VERSION "dbc-export 1 2026.26.6.5"

NS_ :

BS_:

BU_: ADSP APSB BB CMP DAS DPB EPAS3P EPASTP EPASTS GTW IDB OCS1P PTC RCM RCU TCU TCU2 UDS UI UIS VCLEFT VCSEAT2L VCSEAT2R

BO_ 1384 GTW_alertLog: 8 GTW
 SG_ GTW_alertID M : 0|9@1+ (1,0) [0|511] "" Vector__XXX
 SG_ GTW_alertState : 15|1@1+ (1,0) [0|1] "" Vector__XXX
 SG_ GTW_a014_crcVersion m14 : 16|32@1+ (1,0) [0|4294967295] "" Vector__XXX
 SG_ GTW_a015_crcVersion m15 : 16|32@1+ (1,0) [0|4294967295] "" Vector__XXX
 SG_ GTW_a016_crcVersion m16 : 16|32@1+ (1,0) [0|4294967295] "" Vector__XXX
 SG_ GTW_a017_crcVersion m17 : 16|32@1+ (1,0) [0|4294967295] "" Vector__XXX
 SG_ GTW_a018_crcVersion m18 : 16|32@1+ (1,0) [0|4294967295] "" Vector__XXX
 SG_ GTW_a019_crcVersion m19 : 16|32@1+ (1,0) [0|4294967295] "" Vector__XXX
 SG_ GTW_a020_crcVersion m20 : 16|32@1+ (1,0) [0|4294967295] "" Vector__XXX
 SG_ GTW_a021_crcVersion m21 : 16|32@1+ (1,0) [0|4294967295] "" Vector__XXX
 SG_ GTW_a022_crcVersion m22 : 16|32@1+ (1,0) [0|4294967295] "" Vector__XXX
 SG_ GTW_a023_crcVersion m23 : 16|32@1+ (1,0) [0|4294967295] "" Vector__XXX
 SG_ GTW_a024_crcVersion m24 : 16|32@1+ (1,0) [0|4294967295] "" Vector__XXX
 SG_ GTW_a025_crcVersion m25 : 16|32@1+ (1,0) [0|4294967295] "" Vector__XXX
 SG_ GTW_a026_crcVersion m26 : 16|32@1+ (1,0) [0|4294967295] "" Vector__XXX
 SG_ GTW_a027_crcVersion m27 : 16|32@1+ (1,0) [0|4294967295] "" Vector__XXX
 SG_ GTW_a028_crcVersion m28 : 16|32@1+ (1,0) [0|4294967295] "" Vector__XXX
 SG_ GTW_a029_crcVersion m29 : 16|32@1+ (1,0) [0|4294967295] "" Vector__XXX
 SG_ GTW_a030_crcVersion m30 : 16|32@1+ (1,0) [0|4294967295] "" Vector__XXX
 SG_ GTW_a031_crcVersion m31 : 16|32@1+ (1,0) [0|4294967295] "" Vector__XXX
 SG_ GTW_a032_crcVersion m32 : 16|32@1+ (1,0) [0|4294967295] "" Vector__XXX
 SG_ GTW_a033_crcVersion m33 : 16|32@1+ (1,0) [0|4294967295] "" Vector__XXX
 SG_ GTW_a034_crcVersion m34 : 16|32@1+ (1,0) [0|4294967295] "" Vector__XXX
 SG_ GTW_a035_crcVersion m35 : 16|32@1+ (1,0) [0|4294967295] "" Vector__XXX
 SG_ GTW_a036_crcVersion m36 : 16|32@1+ (1,0) [0|4294967295] "" Vector__XXX
 SG_ GTW_a037_crcVersion m37 : 16|32@1+ (1,0) [0|4294967295] "" Vector__XXX
 SG_ GTW_a038_crcVersion m38 : 16|32@1+ (1,0) [0|4294967295] "" Vector__XXX
 SG_ GTW_a039_crcVersion m39 : 16|32@1+ (1,0) [0|4294967295] "" Vector__XXX
 SG_ GTW_a040_crcVersion m40 : 16|32@1+ (1,0) [0|4294967295] "" Vector__XXX
 SG_ GTW_a041_crcVersion m41 : 16|32@1+ (1,0) [0|4294967295] "" Vector__XXX
 SG_ GTW_a042_crcVersion m42 : 16|32@1+ (1,0) [0|4294967295] "" Vector__XXX
 SG_ GTW_a043_crcVersion m43 : 16|32@1+ (1,0) [0|4294967295] "" Vector__XXX
 SG_ GTW_a045_crcVersion m45 : 16|32@1+ (1,0) [0|4294967295] "" Vector__XXX
 SG_ GTW_a046_crcVersion m46 : 16|32@1+ (1,0) [0|4294967295] "" Vector__XXX
 SG_ GTW_a047_crcVersion m47 : 16|32@1+ (1,0) [0|4294967295] "" Vector__XXX
 SG_ GTW_a048_crcVersion m48 : 16|32@1+ (1,0) [0|4294967295] "" Vector__XXX
 SG_ GTW_a049_headerError m49 : 16|2@1+ (1,0) [0|3] "" Vector__XXX
 SG_ GTW_a054_crcVersion m54 : 16|32@1+ (1,0) [0|4294967295] "" Vector__XXX
 SG_ GTW_a055_crcVersion m55 : 16|32@1+ (1,0) [0|4294967295] "" Vector__XXX
 SG_ GTW_a062_bmpWatchdogReason m62 : 16|3@1+ (1,0) [0|7] "" Vector__XXX
 SG_ GTW_a063_VEH_faultConfinement m63 : 16|2@1+ (1,0) [0|3] "" Vector__XXX
 SG_ GTW_a064_CH_faultConfinement m64 : 16|2@1+ (1,0) [0|3] "" Vector__XXX
 SG_ GTW_a065_PARTY_faultConfinement m65 : 16|2@1+ (1,0) [0|3] "" Vector__XXX
 SG_ GTW_a066_type m66 : 16|5@1+ (1,0) [0|31] "" Vector__XXX
 SG_ GTW_a066_exceptionCfgId m66 : 21|8@1+ (1,0) [0|255] "" Vector__XXX
 SG_ GTW_a066_uptime m66 : 29|32@1+ (1,0) [0|4294967295] "" Vector__XXX
 SG_ GTW_a066_core m66 : 61|3@1+ (1,0) [0|7] "" Vector__XXX
 SG_ GTW_a068_codeKeyMissing m68 : 16|1@1+ (1,0) [0|1] "" Vector__XXX
 SG_ GTW_a068_cmdKeyMissing m68 : 17|1@1+ (1,0) [0|1] "" Vector__XXX
 SG_ GTW_a069_sdIntStatusErrs m69 : 16|1@1+ (1,0) [0|1] "" Vector__XXX
 SG_ GTW_a069_sdTimeout m69 : 17|1@1+ (1,0) [0|1] "" Vector__XXX
 SG_ GTW_a069_sdCmdErr m69 : 18|1@1+ (1,0) [0|1] "" Vector__XXX
 SG_ GTW_a069_sdWriteErr m69 : 19|1@1+ (1,0) [0|1] "" Vector__XXX
 SG_ GTW_a069_sdReadErr m69 : 20|1@1+ (1,0) [0|1] "" Vector__XXX
 SG_ GTW_a069_autoCmd12Err m69 : 21|1@1+ (1,0) [0|1] "" Vector__XXX
 SG_ GTW_a072_updtFailureMask m72 : 16|32@1+ (1,0) [0|4294967295] "" Vector__XXX
 SG_ GTW_a073_SOCResetRequestor m73 : 16|3@1+ (1,0) [0|7] "" Vector__XXX
 SG_ GTW_a077_bmpPmicErrorType m77 : 16|3@1+ (1,0) [0|7] "" Vector__XXX
 SG_ GTW_a097_crcVersion m97 : 16|32@1+ (1,0) [0|4294967295] "" Vector__XXX
 SG_ GTW_a098_crcVersion m98 : 16|32@1+ (1,0) [0|4294967295] "" Vector__XXX
 SG_ GTW_a099_crcVersion m99 : 16|32@1+ (1,0) [0|4294967295] "" Vector__XXX
 SG_ GTW_a100_crcVersion m100 : 16|32@1+ (1,0) [0|4294967295] "" Vector__XXX
 SG_ GTW_a101_switchStuck m101 : 16|1@1+ (1,0) [0|1] "" Vector__XXX
 SG_ GTW_a101_ETH_SW_nINT m101 : 17|1@1+ (1,0) [0|1] "" Vector__XXX
 SG_ GTW_a106_crcVersion m106 : 16|32@1+ (1,0) [0|4294967295] "" Vector__XXX
 SG_ GTW_a107_crcVersion m107 : 16|32@1+ (1,0) [0|4294967295] "" Vector__XXX
 SG_ GTW_a108_crcVersion m108 : 16|32@1+ (1,0) [0|4294967295] "" Vector__XXX
 SG_ GTW_a117_MC_RGM_DES m117 : 16|32@1+ (1,0) [0|4294967295] "" Vector__XXX
 SG_ GTW_a118_MC_RGM_FES m118 : 16|32@1+ (1,0) [0|4294967295] "" Vector__XXX
 SG_ GTW_a122_BDY_faultConfinement m122 : 16|2@1+ (1,0) [0|3] "" Vector__XXX
 SG_ GTW_a129_crcVersion m129 : 16|32@1+ (1,0) [0|4294967295] "" Vector__XXX
 SG_ GTW_a138_sdLifetimeUsed m138 : 16|8@1+ (1,0) [0|255] "" Vector__XXX
 SG_ GTW_a139_crcVersion m139 : 16|32@1+ (1,0) [0|4294967295] "" Vector__XXX
 SG_ GTW_a150_crcVersion m150 : 16|32@1+ (1,0) [0|4294967295] "" Vector__XXX
 SG_ GTW_a151_crcVersion m151 : 16|32@1+ (1,0) [0|4294967295] "" Vector__XXX
 SG_ GTW_a155_crcVersion m155 : 16|32@1+ (1,0) [0|4294967295] "" Vector__XXX
 SG_ GTW_a164_crcVersion m164 : 16|32@1+ (1,0) [0|4294967295] "" Vector__XXX
 SG_ GTW_a165_crcVersion m165 : 16|32@1+ (1,0) [0|4294967295] "" Vector__XXX
 SG_ GTW_a169_TPMS_pressureFL m169 : 16|8@1+ (1,0) [0|255] "" Vector__XXX
 SG_ GTW_a170_TPMS_pressureFR m170 : 16|8@1+ (1,0) [0|255] "" Vector__XXX
 SG_ GTW_a171_TPMS_pressureRL m171 : 16|8@1+ (1,0) [0|255] "" Vector__XXX
 SG_ GTW_a172_TPMS_pressureRR m172 : 16|8@1+ (1,0) [0|255] "" Vector__XXX
 SG_ GTW_a173_TPMS_pressureFL m173 : 16|8@1+ (1,0) [0|255] "" Vector__XXX
 SG_ GTW_a174_TPMS_pressureFR m174 : 16|8@1+ (1,0) [0|255] "" Vector__XXX
 SG_ GTW_a175_TPMS_pressureRL m175 : 16|8@1+ (1,0) [0|255] "" Vector__XXX
 SG_ GTW_a176_TPMS_pressureRR m176 : 16|8@1+ (1,0) [0|255] "" Vector__XXX
 SG_ GTW_a219_crcVersion m219 : 16|32@1+ (1,0) [0|4294967295] "" Vector__XXX
 SG_ GTW_a223_crcVersion m223 : 16|32@1+ (1,0) [0|4294967295] "" Vector__XXX
 SG_ GTW_a226_crcVersion m226 : 16|32@1+ (1,0) [0|4294967295] "" Vector__XXX
 SG_ GTW_a227_crcVersion m227 : 16|32@1+ (1,0) [0|4294967295] "" Vector__XXX
 SG_ GTW_a228_crcVersion m228 : 16|32@1+ (1,0) [0|4294967295] "" Vector__XXX
 SG_ GTW_a244_crcVersion m244 : 16|32@1+ (1,0) [0|4294967295] "" Vector__XXX
 SG_ GTW_a245_page0ControlValue m245 : 16|16@1+ (1,0) [0|65535] "" Vector__XXX
 SG_ GTW_a245_page1ControlValue m245 : 32|16@1+ (1,0) [0|65535] "" Vector__XXX
 SG_ GTW_a261_failureReason m261 : 16|3@1+ (1,0) [0|7] "" Vector__XXX
 SG_ GTW_a261_failureData1 m261 : 24|16@1+ (1,0) [0|65535] "" Vector__XXX
 SG_ GTW_a261_failureData2 m261 : 40|16@1+ (1,0) [0|65535] "" Vector__XXX
 SG_ GTW_a273_crcVersion m273 : 16|32@1+ (1,0) [0|4294967295] "" Vector__XXX
 SG_ GTW_a274_crcVersion m274 : 16|32@1+ (1,0) [0|4294967295] "" Vector__XXX
 SG_ GTW_a277_mitigationFailureReason m277 : 16|3@1+ (1,0) [0|7] "" Vector__XXX
 SG_ GTW_a279_repeatCount m279 : 16|8@1+ (1,0) [0|255] "" Vector__XXX
 SG_ GTW_a279_failureReason m279 : 24|3@1+ (1,0) [0|7] "" Vector__XXX
 SG_ GTW_a279_failureData1 m279 : 32|16@1+ (1,0) [0|65535] "" Vector__XXX
 SG_ GTW_a279_failureData2 m279 : 48|16@1+ (1,0) [0|65535] "" Vector__XXX
 SG_ GTW_a309_crcVersion m309 : 16|32@1+ (1,0) [0|4294967295] "" Vector__XXX
 SG_ GTW_a317_status m317 : 16|3@1+ (1,0) [0|7] "" Vector__XXX
 SG_ GTW_a317_errorCode m317 : 19|5@1+ (1,0) [0|31] "" Vector__XXX
 SG_ GTW_a329_crcVersion m329 : 16|32@1+ (1,0) [0|4294967295] "" Vector__XXX
 SG_ GTW_a330_crcVersion m330 : 16|32@1+ (1,0) [0|4294967295] "" Vector__XXX
 SG_ GTW_a331_crcVersion m331 : 16|32@1+ (1,0) [0|4294967295] "" Vector__XXX
 SG_ GTW_a342_crcVersion m342 : 16|32@1+ (1,0) [0|4294967295] "" Vector__XXX
 SG_ GTW_a348_crcVersion m348 : 16|32@1+ (1,0) [0|4294967295] "" Vector__XXX
 SG_ GTW_a349_crcVersion m349 : 16|32@1+ (1,0) [0|4294967295] "" Vector__XXX
 SG_ GTW_a354_crcVersion m354 : 16|32@1+ (1,0) [0|4294967295] "" Vector__XXX
 SG_ GTW_a355_crcVersion m355 : 16|32@1+ (1,0) [0|4294967295] "" Vector__XXX
 SG_ GTW_a358_crcVersion m358 : 16|32@1+ (1,0) [0|4294967295] "" Vector__XXX
 SG_ GTW_a359_crcVersion m359 : 16|32@1+ (1,0) [0|4294967295] "" Vector__XXX
 SG_ GTW_a360_crcVersion m360 : 16|32@1+ (1,0) [0|4294967295] "" Vector__XXX
 SG_ GTW_a361_crcVersion m361 : 16|32@1+ (1,0) [0|4294967295] "" Vector__XXX
 SG_ GTW_a362_crcVersion m362 : 16|32@1+ (1,0) [0|4294967295] "" Vector__XXX
 SG_ GTW_a363_crcVersion m363 : 16|32@1+ (1,0) [0|4294967295] "" Vector__XXX
 SG_ GTW_a364_crcVersion m364 : 16|32@1+ (1,0) [0|4294967295] "" Vector__XXX
 SG_ GTW_a380_crcVersion m380 : 16|32@1+ (1,0) [0|4294967295] "" Vector__XXX
 SG_ GTW_a381_crcVersion m381 : 16|32@1+ (1,0) [0|4294967295] "" Vector__XXX
 SG_ GTW_a382_crcVersion m382 : 16|32@1+ (1,0) [0|4294967295] "" Vector__XXX
 SG_ GTW_a383_crcVersion m383 : 16|32@1+ (1,0) [0|4294967295] "" Vector__XXX
 SG_ GTW_a384_crcVersion m384 : 16|32@1+ (1,0) [0|4294967295] "" Vector__XXX
 SG_ GTW_a385_crcVersion m385 : 16|32@1+ (1,0) [0|4294967295] "" Vector__XXX
 SG_ GTW_a386_crcVersion m386 : 16|32@1+ (1,0) [0|4294967295] "" Vector__XXX
 SG_ GTW_a394_crcVersion m394 : 16|32@1+ (1,0) [0|4294967295] "" Vector__XXX
 SG_ GTW_a401_crcVersion m401 : 16|32@1+ (1,0) [0|4294967295] "" Vector__XXX
 SG_ GTW_a402_crcVersion m402 : 16|32@1+ (1,0) [0|4294967295] "" Vector__XXX
 SG_ GTW_a409_RES_CAUSE m409 : 16|32@1+ (1,0) [0|4294967295] "" Vector__XXX
 SG_ GTW_a410_RES_CAUSE2 m410 : 16|32@1+ (1,0) [0|4294967295] "" Vector__XXX
 SG_ GTW_a418_crcVersion m418 : 16|32@1+ (1,0) [0|4294967295] "" Vector__XXX
 SG_ GTW_a427_crcVersion m427 : 16|32@1+ (1,0) [0|4294967295] "" Vector__XXX
 SG_ GTW_a428_crcVersion m428 : 16|32@1+ (1,0) [0|4294967295] "" Vector__XXX
 SG_ GTW_a429_crcVersion m429 : 16|32@1+ (1,0) [0|4294967295] "" Vector__XXX
 SG_ GTW_a439_crcVersion m439 : 16|32@1+ (1,0) [0|4294967295] "" Vector__XXX

BO_ 62 GTW_alertMatrix: 8 GTW
 SG_ GTW_matrixIndex M : 0|4@1+ (1,0) [0|15] "" Vector__XXX
 SG_ GTW_w001_canEthTxQueue m0 : 4|1@1+ (1,0) [0|1] "" Vector__XXX
 SG_ GTW_w002_taskError m0 : 5|1@1+ (1,0) [0|1] "" Vector__XXX
 SG_ GTW_w003_logWriteRecord m0 : 6|1@1+ (1,0) [0|1] "" Vector__XXX
 SG_ GTW_w004_mallocHook m0 : 7|1@1+ (1,0) [0|1] "" Vector__XXX
 SG_ GTW_w005_stackOverflowHook m0 : 8|1@1+ (1,0) [0|1] "" Vector__XXX
 SG_ GTW_w006_ifTxOutputFull m0 : 9|1@1+ (1,0) [0|1] "" Vector__XXX
 SG_ GTW_w007_ifRxBufError m0 : 10|1@1+ (1,0) [0|1] "" Vector__XXX
 SG_ GTW_w008_ifPbufAllocError m0 : 11|1@1+ (1,0) [0|1] "" Vector__XXX
 SG_ GTW_w009_lateTask m0 : 12|1@1+ (1,0) [0|1] "" Vector__XXX
 SG_ GTW_w010_wdTaskCount m0 : 13|1@1+ (1,0) [0|1] "" Vector__XXX
 SG_ GTW_w011_cancoreWatchdog m0 : 14|1@1+ (1,0) [0|1] "" Vector__XXX
 SG_ GTW_w012_maincoreWatchdog m0 : 15|1@1+ (1,0) [0|1] "" Vector__XXX
 SG_ GTW_w014_APSversionMismatch m0 : 17|1@1+ (1,0) [0|1] "" Vector__XXX
 SG_ GTW_w015_DIFversionMismatch m0 : 18|1@1+ (1,0) [0|1] "" Vector__XXX
 SG_ GTW_w016_BLEEPCENTERversionMisma m0 : 19|1@1+ (1,0) [0|1] "" Vector__XXX
 SG_ GTW_w017_BMSversionMismatch m0 : 20|1@1+ (1,0) [0|1] "" Vector__XXX
 SG_ GTW_w018_CMPversionMismatch m0 : 21|1@1+ (1,0) [0|1] "" Vector__XXX
 SG_ GTW_w019_CPversionMismatch m0 : 22|1@1+ (1,0) [0|1] "" Vector__XXX
 SG_ GTW_w020_DIRversionMismatch m0 : 23|1@1+ (1,0) [0|1] "" Vector__XXX
 SG_ GTW_w021_EPAS3PversionMismatch m0 : 24|1@1+ (1,0) [0|1] "" Vector__XXX
 SG_ GTW_w022_EPBLversionMismatch m0 : 25|1@1+ (1,0) [0|1] "" Vector__XXX
 SG_ GTW_w023_EPBRversionMismatch m0 : 26|1@1+ (1,0) [0|1] "" Vector__XXX
 SG_ GTW_w024_ESPversionMismatch m0 : 27|1@1+ (1,0) [0|1] "" Vector__XXX
 SG_ GTW_w025_ESPCALversionMismatch m0 : 28|1@1+ (1,0) [0|1] "" Vector__XXX
 SG_ GTW_w026_GTWversionMismatch m0 : 29|1@1+ (1,0) [0|1] "" Vector__XXX
 SG_ GTW_w027_HVPversionMismatch m0 : 30|1@1+ (1,0) [0|1] "" Vector__XXX
 SG_ GTW_w028_IBSTversionMismatch m0 : 31|1@1+ (1,0) [0|1] "" Vector__XXX
 SG_ GTW_w029_IBSTCALversionMismatch m0 : 32|1@1+ (1,0) [0|1] "" Vector__XXX
 SG_ GTW_w030_OCS1PversionMismatch m0 : 33|1@1+ (1,0) [0|1] "" Vector__XXX
 SG_ GTW_w031_PARKversionMismatch m0 : 34|1@1+ (1,0) [0|1] "" Vector__XXX
 SG_ GTW_w032_PCSversionMismatch m0 : 35|1@1+ (1,0) [0|1] "" Vector__XXX
 SG_ GTW_w033_PCSCPU2versionMismatch m0 : 36|1@1+ (1,0) [0|1] "" Vector__XXX
 SG_ GTW_w034_PMRversionMismatch m0 : 37|1@1+ (1,0) [0|1] "" Vector__XXX
 SG_ GTW_w035_PMFversionMismatch m0 : 38|1@1+ (1,0) [0|1] "" Vector__XXX
 SG_ GTW_w036_PTCversionMismatch m0 : 39|1@1+ (1,0) [0|1] "" Vector__XXX
 SG_ GTW_w037_RADCversionMismatch m0 : 40|1@1+ (1,0) [0|1] "" Vector__XXX
 SG_ GTW_w038_RCMversionMismatch m0 : 41|1@1+ (1,0) [0|1] "" Vector__XXX
 SG_ GTW_w039_RCMCALversionMismatch m0 : 42|1@1+ (1,0) [0|1] "" Vector__XXX
 SG_ GTW_w040_SCCMversionMismatch m0 : 43|1@1+ (1,0) [0|1] "" Vector__XXX
 SG_ GTW_w041_VCSECversionMismatch m0 : 44|1@1+ (1,0) [0|1] "" Vector__XXX
 SG_ GTW_w042_TASversionMismatch m0 : 45|1@1+ (1,0) [0|1] "" Vector__XXX
 SG_ GTW_w043_THSversionMismatch m0 : 46|1@1+ (1,0) [0|1] "" Vector__XXX
 SG_ GTW_w045_VCFRONTversionMismatch m0 : 48|1@1+ (1,0) [0|1] "" Vector__XXX
 SG_ GTW_w046_VCLEFTversionMismatch m0 : 49|1@1+ (1,0) [0|1] "" Vector__XXX
 SG_ GTW_w047_VCRIGHTversionMismatch m0 : 50|1@1+ (1,0) [0|1] "" Vector__XXX
 SG_ GTW_w048_EPAS3SversionMismatch m0 : 51|1@1+ (1,0) [0|1] "" Vector__XXX
 SG_ GTW_w049_corruptedManifest m0 : 52|1@1+ (1,0) [0|1] "" Vector__XXX
 SG_ GTW_w050_sdCardInitFailure m0 : 53|1@1+ (1,0) [0|1] "" Vector__XXX
 SG_ GTW_w051_sdCardFileSystemFailure m0 : 54|1@1+ (1,0) [0|1] "" Vector__XXX
 SG_ GTW_w052_ifTxSpans m0 : 55|1@1+ (1,0) [0|1] "" Vector__XXX
 SG_ GTW_w053_busSleepFailure m0 : 56|1@1+ (1,0) [0|1] "" Vector__XXX
 SG_ GTW_w054_OPCRversionMismatch m0 : 57|1@1+ (1,0) [0|1] "" Vector__XXX
 SG_ GTW_w055_OPCFversionMismatch m0 : 58|1@1+ (1,0) [0|1] "" Vector__XXX
 SG_ GTW_w057_i2cFailure m0 : 60|1@1+ (1,0) [0|1] "" Vector__XXX
 SG_ GTW_w058_rtcAlarmFailure m0 : 61|1@1+ (1,0) [0|1] "" Vector__XXX
 SG_ GTW_w059_inFactoryMode m0 : 62|1@1+ (1,0) [0|1] "" Vector__XXX
 SG_ GTW_w060_unFused m0 : 63|1@1+ (1,0) [0|1] "" Vector__XXX
 SG_ GTW_w061_bmpSleepFailure m1 : 4|1@1+ (1,0) [0|1] "" Vector__XXX
 SG_ GTW_w062_bmpWatchdog m1 : 5|1@1+ (1,0) [0|1] "" Vector__XXX
 SG_ GTW_w063_VEH_canFault m1 : 6|1@1+ (1,0) [0|1] "" Vector__XXX
 SG_ GTW_w064_CH_canFault m1 : 7|1@1+ (1,0) [0|1] "" Vector__XXX
 SG_ GTW_w065_PARTY_canFault m1 : 8|1@1+ (1,0) [0|1] "" Vector__XXX
 SG_ GTW_w066_exception m1 : 9|1@1+ (1,0) [0|1] "" Vector__XXX
 SG_ GTW_w067_tcpDebug m1 : 10|1@1+ (1,0) [0|1] "" Vector__XXX
 SG_ GTW_w068_prodKeyMissing m1 : 11|1@1+ (1,0) [0|1] "" Vector__XXX
 SG_ GTW_w069_diskioErr m1 : 12|1@1+ (1,0) [0|1] "" Vector__XXX
 SG_ GTW_w070_hrlDump m1 : 13|1@1+ (1,0) [0|1] "" Vector__XXX
 SG_ GTW_w071_hrlTrigger m1 : 14|1@1+ (1,0) [0|1] "" Vector__XXX
 SG_ GTW_w072_updateFailure m1 : 15|1@1+ (1,0) [0|1] "" Vector__XXX
 SG_ GTW_w073_steeringWheelReset m1 : 16|1@1+ (1,0) [0|1] "" Vector__XXX
 SG_ GTW_w074_epas3pMIA m1 : 17|1@1+ (1,0) [0|1] "" Vector__XXX
 SG_ GTW_w075_epas3sMIA m1 : 18|1@1+ (1,0) [0|1] "" Vector__XXX
 SG_ GTW_w076_ethInterfaceReset m1 : 19|1@1+ (1,0) [0|1] "" Vector__XXX
 SG_ GTW_w077_bmpPmicError m1 : 20|1@1+ (1,0) [0|1] "" Vector__XXX
 SG_ GTW_w078_VEHbusOverloaded m1 : 21|1@1+ (1,0) [0|1] "" Vector__XXX
 SG_ GTW_w079_PARTYbusOverloaded m1 : 22|1@1+ (1,0) [0|1] "" Vector__XXX
 SG_ GTW_w080_CHbusOverloaded m1 : 23|1@1+ (1,0) [0|1] "" Vector__XXX
 SG_ GTW_w081_udsMessageRejected m1 : 24|1@1+ (1,0) [0|1] "" Vector__XXX
 SG_ GTW_w082_sdCardBSCorrupted m1 : 25|1@1+ (1,0) [0|1] "" Vector__XXX
 SG_ GTW_w083_udsMsgDroppedByTcpStack m1 : 26|1@1+ (1,0) [0|1] "" Vector__XXX
 SG_ GTW_w084_canFrameDropped m1 : 27|1@1+ (1,0) [0|1] "" Vector__XXX
 SG_ GTW_w085_fuseStateUnknown m1 : 28|1@1+ (1,0) [0|1] "" Vector__XXX
 SG_ GTW_w086_ocu m1 : 29|1@1+ (1,0) [0|1] "" Vector__XXX
 SG_ GTW_w087_ocuInProgress m1 : 30|1@1+ (1,0) [0|1] "" Vector__XXX
 SG_ GTW_w088_sdCardInvReqParallel m1 : 31|1@1+ (1,0) [0|1] "" Vector__XXX
 SG_ GTW_w089_sdCardWatchdog m1 : 32|1@1+ (1,0) [0|1] "" Vector__XXX
 SG_ GTW_w090_ocuFailed m1 : 33|1@1+ (1,0) [0|1] "" Vector__XXX
 SG_ GTW_w091_lowStack m1 : 34|1@1+ (1,0) [0|1] "" Vector__XXX
 SG_ GTW_w092_sdCardInvReqZero m1 : 35|1@1+ (1,0) [0|1] "" Vector__XXX
 SG_ GTW_w093_sdCardInvReqOverflowBas m1 : 36|1@1+ (1,0) [0|1] "" Vector__XXX
 SG_ GTW_w094_sdCardInvReqOverflowCou m1 : 37|1@1+ (1,0) [0|1] "" Vector__XXX
 SG_ GTW_w095_sdCardFull m1 : 38|1@1+ (1,0) [0|1] "" Vector__XXX
 SG_ GTW_w096_sdCardFatCorrupted m1 : 39|1@1+ (1,0) [0|1] "" Vector__XXX
 SG_ GTW_w097_HCMLversionMismatch m1 : 40|1@1+ (1,0) [0|1] "" Vector__XXX
 SG_ GTW_w098_HCMRversionMismatch m1 : 41|1@1+ (1,0) [0|1] "" Vector__XXX
 SG_ GTW_w099_SWCversionMismatch m1 : 42|1@1+ (1,0) [0|1] "" Vector__XXX
 SG_ GTW_w100_CBCversionMismatch m1 : 43|1@1+ (1,0) [0|1] "" Vector__XXX
 SG_ GTW_w101_switchWatchdog m1 : 44|1@1+ (1,0) [0|1] "" Vector__XXX
 SG_ GTW_w103_sdCardFormatted m1 : 46|1@1+ (1,0) [0|1] "" Vector__XXX
 SG_ GTW_w104_sdCardDriverArgCorrupte m1 : 47|1@1+ (1,0) [0|1] "" Vector__XXX
 SG_ GTW_w105_eBuckConfigured m1 : 48|1@1+ (1,0) [0|1] "" Vector__XXX
 SG_ GTW_w106_BLEEPLEFTversionMismatc m1 : 49|1@1+ (1,0) [0|1] "" Vector__XXX
 SG_ GTW_w107_BLEEPRIGHTversionMismat m1 : 50|1@1+ (1,0) [0|1] "" Vector__XXX
 SG_ GTW_w108_BLEEPREARversionMismatc m1 : 51|1@1+ (1,0) [0|1] "" Vector__XXX
 SG_ GTW_w109_failedToStartUpdater m1 : 52|1@1+ (1,0) [0|1] "" Vector__XXX
 SG_ GTW_w110_readMdioFailed m1 : 53|1@1+ (1,0) [0|1] "" Vector__XXX
 SG_ GTW_w111_writeMdioFailed m1 : 54|1@1+ (1,0) [0|1] "" Vector__XXX
 SG_ GTW_w112_z4bDisabled m1 : 55|1@1+ (1,0) [0|1] "" Vector__XXX
 SG_ GTW_w113_unrecognizedCanMessage m1 : 56|1@1+ (1,0) [0|1] "" Vector__XXX
 SG_ GTW_w114_updtRetried m1 : 57|1@1+ (1,0) [0|1] "" Vector__XXX
 SG_ GTW_w115_hrlEventFileAvail m1 : 58|1@1+ (1,0) [0|1] "" Vector__XXX
 SG_ GTW_w116_switchInitFailed m1 : 59|1@1+ (1,0) [0|1] "" Vector__XXX
 SG_ GTW_w117_unexpectedDestructiveRe m1 : 60|1@1+ (1,0) [0|1] "" Vector__XXX
 SG_ GTW_w118_unexpectedFunctionalRes m1 : 61|1@1+ (1,0) [0|1] "" Vector__XXX
 SG_ GTW_w120_switchUnlocked m1 : 63|1@1+ (1,0) [0|1] "" Vector__XXX
 SG_ GTW_w122_BDY_canFault m2 : 5|1@1+ (1,0) [0|1] "" Vector__XXX
 SG_ GTW_w123_BDYbusOverloaded m2 : 6|1@1+ (1,0) [0|1] "" Vector__XXX
 SG_ GTW_w125_switchReplayUnlocked m2 : 8|1@1+ (1,0) [0|1] "" Vector__XXX
 SG_ GTW_w127_noFilePointersAvailable m2 : 10|1@1+ (1,0) [0|1] "" Vector__XXX
 SG_ GTW_w129_ICRversionMismatch m2 : 12|1@1+ (1,0) [0|1] "" Vector__XXX
 SG_ GTW_w133_adspFaultDetected m2 : 16|1@1+ (1,0) [0|1] "" Vector__XXX
 SG_ GTW_w134_disableFeatureFailed m2 : 17|1@1+ (1,0) [0|1] "" Vector__XXX
 SG_ GTW_w135_canLogQueueFull m2 : 18|1@1+ (1,0) [0|1] "" Vector__XXX
 SG_ GTW_w136_hrlGameModeFileAvail m2 : 19|1@1+ (1,0) [0|1] "" Vector__XXX
 SG_ GTW_w137_lowHeap m2 : 20|1@1+ (1,0) [0|1] "" Vector__XXX
 SG_ GTW_w138_sdCardEndOfLife m2 : 21|1@1+ (1,0) [0|1] "" Vector__XXX
 SG_ GTW_w139_CMPDversionMismatch m2 : 22|1@1+ (1,0) [0|1] "" Vector__XXX
 SG_ GTW_w140_cancoreHeartbeat m2 : 23|1@1+ (1,0) [0|1] "" Vector__XXX
 SG_ GTW_w141_teleCANETHis m2 : 24|1@1+ (1,0) [0|1] "" Vector__XXX
 SG_ GTW_w143_possibleCanWakeIssue m2 : 26|1@1+ (1,0) [0|1] "" Vector__XXX
 SG_ GTW_w144_hrlStateMachine m2 : 27|1@1+ (1,0) [0|1] "" Vector__XXX
 SG_ GTW_w145_carConfigsNotWritten m2 : 28|1@1+ (1,0) [0|1] "" Vector__XXX
 SG_ GTW_w146_performancePackageMisma m2 : 29|1@1+ (1,0) [0|1] "" Vector__XXX
 SG_ GTW_w147_updateAbortFor12v m2 : 30|1@1+ (1,0) [0|1] "" Vector__XXX
 SG_ GTW_w149_rtcTimeSetInPast m2 : 32|1@1+ (1,0) [0|1] "" Vector__XXX
 SG_ GTW_w150_HCM3LversionMismatch m2 : 33|1@1+ (1,0) [0|1] "" Vector__XXX
 SG_ GTW_w151_HCM3RversionMismatch m2 : 34|1@1+ (1,0) [0|1] "" Vector__XXX
 SG_ GTW_w153_externalRtcAlarmFailure m2 : 36|1@1+ (1,0) [0|1] "" Vector__XXX
 SG_ GTW_w155_PMversionMismatch m2 : 38|1@1+ (1,0) [0|1] "" Vector__XXX
 SG_ GTW_w164_VCBATTversionMismatch m2 : 47|1@1+ (1,0) [0|1] "" Vector__XXX
 SG_ GTW_w165_USMversionMismatch m2 : 48|1@1+ (1,0) [0|1] "" Vector__XXX
 SG_ GTW_w166_nErrCanFaultVeh m2 : 49|1@1+ (1,0) [0|1] "" Vector__XXX
 SG_ GTW_w167_nErrCanFaultCh m2 : 50|1@1+ (1,0) [0|1] "" Vector__XXX
 SG_ GTW_w168_nErrCanFaultParty m2 : 51|1@1+ (1,0) [0|1] "" Vector__XXX
 SG_ GTW_w169_TPMSsoftWarnFrontLeft m2 : 52|1@1+ (1,0) [0|1] "" Vector__XXX
 SG_ GTW_w170_TPMSsoftWarnFrontRight m2 : 53|1@1+ (1,0) [0|1] "" Vector__XXX
 SG_ GTW_w171_TPMSsoftWarnRearLeft m2 : 54|1@1+ (1,0) [0|1] "" Vector__XXX
 SG_ GTW_w172_TPMSsoftWarnRearRight m2 : 55|1@1+ (1,0) [0|1] "" Vector__XXX
 SG_ GTW_w173_TPMShardWarnFrontLeft m2 : 56|1@1+ (1,0) [0|1] "" Vector__XXX
 SG_ GTW_w174_TPMShardWarnFrontRight m2 : 57|1@1+ (1,0) [0|1] "" Vector__XXX
 SG_ GTW_w175_TPMShardWarnRearLeft m2 : 58|1@1+ (1,0) [0|1] "" Vector__XXX
 SG_ GTW_w176_TPMShardWarnRearRight m2 : 59|1@1+ (1,0) [0|1] "" Vector__XXX
 SG_ GTW_w186_swrPrecaution m3 : 9|1@1+ (1,0) [0|1] "" Vector__XXX
 SG_ GTW_w218_switchOTPIncorrect m3 : 41|1@1+ (1,0) [0|1] "" Vector__XXX
 SG_ GTW_w219_CMPSversionMismatch m3 : 42|1@1+ (1,0) [0|1] "" Vector__XXX
 SG_ GTW_w223_LVBMSversionMismatch m3 : 46|1@1+ (1,0) [0|1] "" Vector__XXX
 SG_ GTW_w224_sdCardUpgradeNeeded m3 : 47|1@1+ (1,0) [0|1] "" Vector__XXX
 SG_ GTW_w225_resetOnSleepWake m3 : 48|1@1+ (1,0) [0|1] "" Vector__XXX
 SG_ GTW_w226_DISPversionMismatch m3 : 49|1@1+ (1,0) [0|1] "" Vector__XXX
 SG_ GTW_w227_DISPTOUCHversionMismatc m3 : 50|1@1+ (1,0) [0|1] "" Vector__XXX
 SG_ GTW_w228_DISPOSDversionMismatch m3 : 51|1@1+ (1,0) [0|1] "" Vector__XXX
 SG_ GTW_w229_displaySoftsetConnectio m3 : 52|1@1+ (1,0) [0|1] "" Vector__XXX
 SG_ GTW_w230_touchInterruptStorm m3 : 53|1@1+ (1,0) [0|1] "" Vector__XXX
 SG_ GTW_w244_SDCRversionMismatch m4 : 7|1@1+ (1,0) [0|1] "" Vector__XXX
 SG_ GTW_w245_apsNotDisabled m4 : 8|1@1+ (1,0) [0|1] "" Vector__XXX
 SG_ GTW_w246_touchcoreHeartbeat m4 : 9|1@1+ (1,0) [0|1] "" Vector__XXX
 SG_ GTW_w255_rtc32KHzWatchdog m4 : 18|1@1+ (1,0) [0|1] "" Vector__XXX
 SG_ GTW_w260_unknownPN m4 : 23|1@1+ (1,0) [0|1] "" Vector__XXX
 SG_ GTW_w261_adspWatchdog m4 : 24|1@1+ (1,0) [0|1] "" Vector__XXX
 SG_ GTW_w262_canLogBlockDropped m4 : 25|1@1+ (1,0) [0|1] "" Vector__XXX
 SG_ GTW_w263_hrlUdpFileAvail m4 : 26|1@1+ (1,0) [0|1] "" Vector__XXX
 SG_ GTW_w264_hrlPseudoFileAvail m4 : 27|1@1+ (1,0) [0|1] "" Vector__XXX
 SG_ GTW_w265_optionFlagsError m4 : 28|1@1+ (1,0) [0|1] "" Vector__XXX
 SG_ GTW_w266_dpp1MIA m4 : 29|1@1+ (1,0) [0|1] "" Vector__XXX
 SG_ GTW_w267_dpp2MIA m4 : 30|1@1+ (1,0) [0|1] "" Vector__XXX
 SG_ GTW_w268_stoMIA m4 : 31|1@1+ (1,0) [0|1] "" Vector__XXX
 SG_ GTW_w273_BLEEPREARLEFTversionMis m4 : 36|1@1+ (1,0) [0|1] "" Vector__XXX
 SG_ GTW_w274_BLEEPREARRIGHTversionMi m4 : 37|1@1+ (1,0) [0|1] "" Vector__XXX
 SG_ GTW_w275_VDDCORE_DrMOS_Fault m4 : 38|1@1+ (1,0) [0|1] "" Vector__XXX
 SG_ GTW_w276_VDDSOC_DrMOS_Fault m4 : 39|1@1+ (1,0) [0|1] "" Vector__XXX
 SG_ GTW_w277_NonRevCDrMOSMitigationF m4 : 40|1@1+ (1,0) [0|1] "" Vector__XXX
 SG_ GTW_w278_ethSwitchCongested m4 : 41|1@1+ (1,0) [0|1] "" Vector__XXX
 SG_ GTW_w279_adspRepeatedWatchdog m4 : 42|1@1+ (1,0) [0|1] "" Vector__XXX
 SG_ GTW_w280_hrlFrameDropped m4 : 43|1@1+ (1,0) [0|1] "" Vector__XXX
 SG_ GTW_w281_likelyMissedPoke m4 : 44|1@1+ (1,0) [0|1] "" Vector__XXX
 SG_ GTW_w282_tcuPhyConfigurationFail m4 : 45|1@1+ (1,0) [0|1] "" Vector__XXX
 SG_ GTW_w309_VCUSBversionMismatch m5 : 12|1@1+ (1,0) [0|1] "" Vector__XXX
 SG_ GTW_w311_canLogQueueFullBeforeFs m5 : 14|1@1+ (1,0) [0|1] "" Vector__XXX
 SG_ GTW_w312_hrlFileIncomplete m5 : 15|1@1+ (1,0) [0|1] "" Vector__XXX
 SG_ GTW_w313_OSDActive m5 : 16|1@1+ (1,0) [0|1] "" Vector__XXX
 SG_ GTW_w314_canLogBlockWriteErr m5 : 17|1@1+ (1,0) [0|1] "" Vector__XXX
 SG_ GTW_w316_sdCardChkdskRepair m5 : 19|1@1+ (1,0) [0|1] "" Vector__XXX
 SG_ GTW_w317_sdCardChkdskRepairFaile m5 : 20|1@1+ (1,0) [0|1] "" Vector__XXX
 SG_ GTW_w322_gestureUnrecognizedFrom m5 : 25|1@1+ (1,0) [0|1] "" Vector__XXX
 SG_ GTW_w323_gestureStartOutOfStrip m5 : 26|1@1+ (1,0) [0|1] "" Vector__XXX
 SG_ GTW_w328_smartShiftDisabled m5 : 31|1@1+ (1,0) [0|1] "" Vector__XXX
 SG_ GTW_w329_FOHMversionMismatch m5 : 32|1@1+ (1,0) [0|1] "" Vector__XXX
 SG_ GTW_w330_SWSLversionMismatch m5 : 33|1@1+ (1,0) [0|1] "" Vector__XXX
 SG_ GTW_w331_SWSRversionMismatch m5 : 34|1@1+ (1,0) [0|1] "" Vector__XXX
 SG_ GTW_w332_unknownDisplayPN m5 : 35|1@1+ (1,0) [0|1] "" Vector__XXX
 SG_ GTW_w334_hrlFolderSpaceLow m5 : 37|1@1+ (1,0) [0|1] "" Vector__XXX
 SG_ GTW_w336_possibleCanTxIssue m5 : 39|1@1+ (1,0) [0|1] "" Vector__XXX
 SG_ GTW_w342_VCBLDCPPversionMismatch m5 : 45|1@1+ (1,0) [0|1] "" Vector__XXX
 SG_ GTW_w348_VCBLDCFversionMismatch m5 : 51|1@1+ (1,0) [0|1] "" Vector__XXX
 SG_ GTW_w349_VCBLDCPBversionMismatch m5 : 52|1@1+ (1,0) [0|1] "" Vector__XXX
 SG_ GTW_w350_mOSDCrcCheck m5 : 53|1@1+ (1,0) [0|1] "" Vector__XXX
 SG_ GTW_w351_sOSDCrcCheck m5 : 54|1@1+ (1,0) [0|1] "" Vector__XXX
 SG_ GTW_w352_mASILStatusCheck m5 : 55|1@1+ (1,0) [0|1] "" Vector__XXX
 SG_ GTW_w353_sASILStatusCheck m5 : 56|1@1+ (1,0) [0|1] "" Vector__XXX
 SG_ GTW_w354_EPASTPversionMismatch m5 : 57|1@1+ (1,0) [0|1] "" Vector__XXX
 SG_ GTW_w355_EPASTSversionMismatch m5 : 58|1@1+ (1,0) [0|1] "" Vector__XXX
 SG_ GTW_w356_touchGPIOStatusCheck m5 : 59|1@1+ (1,0) [0|1] "" Vector__XXX
 SG_ GTW_w358_RGBIPFLversionMismatch m5 : 61|1@1+ (1,0) [0|1] "" Vector__XXX
 SG_ GTW_w359_RGBIPFRversionMismatch m5 : 62|1@1+ (1,0) [0|1] "" Vector__XXX
 SG_ GTW_w360_RGBDOORFLversionMismatc m5 : 63|1@1+ (1,0) [0|1] "" Vector__XXX
 SG_ GTW_w361_RGBDOORRLversionMismatc m6 : 4|1@1+ (1,0) [0|1] "" Vector__XXX
 SG_ GTW_w362_RGBDOORFRversionMismatc m6 : 5|1@1+ (1,0) [0|1] "" Vector__XXX
 SG_ GTW_w363_RGBDOORRRversionMismatc m6 : 6|1@1+ (1,0) [0|1] "" Vector__XXX
 SG_ GTW_w364_BLEEPCRADLEversionMisma m6 : 7|1@1+ (1,0) [0|1] "" Vector__XXX
 SG_ GTW_w366_uiGearRequestMismatch m6 : 9|1@1+ (1,0) [0|1] "" Vector__XXX
 SG_ GTW_w376_blFailedToExecBootImg m6 : 19|1@1+ (1,0) [0|1] "" Vector__XXX
 SG_ GTW_w380_DPBversionMismatch m6 : 23|1@1+ (1,0) [0|1] "" Vector__XXX
 SG_ GTW_w381_DPBCALversionMismatch m6 : 24|1@1+ (1,0) [0|1] "" Vector__XXX
 SG_ GTW_w382_IDBversionMismatch m6 : 25|1@1+ (1,0) [0|1] "" Vector__XXX
 SG_ GTW_w383_IDB1versionMismatch m6 : 26|1@1+ (1,0) [0|1] "" Vector__XXX
 SG_ GTW_w384_IDBCALversionMismatch m6 : 27|1@1+ (1,0) [0|1] "" Vector__XXX
 SG_ GTW_w385_RCUversionMismatch m6 : 28|1@1+ (1,0) [0|1] "" Vector__XXX
 SG_ GTW_w386_RCUCALversionMismatch m6 : 29|1@1+ (1,0) [0|1] "" Vector__XXX
 SG_ GTW_w387_externalRtcReadFailure m6 : 30|1@1+ (1,0) [0|1] "" Vector__XXX
 SG_ GTW_w388_adspWatchdogSkipped m6 : 31|1@1+ (1,0) [0|1] "" Vector__XXX
 SG_ GTW_w389_rcmEventDetected m6 : 32|1@1+ (1,0) [0|1] "" Vector__XXX
 SG_ GTW_w390_displayFwQueryFailed m6 : 33|1@1+ (1,0) [0|1] "" Vector__XXX
 SG_ GTW_w391_adspMacAddrCheckFailed m6 : 34|1@1+ (1,0) [0|1] "" Vector__XXX
 SG_ GTW_w393_osdSramCrcMismatch m6 : 36|1@1+ (1,0) [0|1] "" Vector__XXX
 SG_ GTW_w394_WIPERversionMismatch m6 : 37|1@1+ (1,0) [0|1] "" Vector__XXX
 SG_ GTW_w395_lwipIcmpError m6 : 38|1@1+ (1,0) [0|1] "" Vector__XXX
 SG_ GTW_w396_alreadyInReverse m6 : 39|1@1+ (1,0) [0|1] "" Vector__XXX
 SG_ GTW_w397_alreadyInDrive m6 : 40|1@1+ (1,0) [0|1] "" Vector__XXX
 SG_ GTW_w398_awakeForExtendedTime m6 : 41|1@1+ (1,0) [0|1] "" Vector__XXX
 SG_ GTW_w399_ethIfRxTcpipQueueDrop m6 : 42|1@1+ (1,0) [0|1] "" Vector__XXX
 SG_ GTW_w400_ethlSwitchOTPIncorrect m6 : 43|1@1+ (1,0) [0|1] "" Vector__XXX
 SG_ GTW_w401_VCSEAT2LversionMismatch m6 : 44|1@1+ (1,0) [0|1] "" Vector__XXX
 SG_ GTW_w402_VCSEAT2RversionMismatch m6 : 45|1@1+ (1,0) [0|1] "" Vector__XXX
 SG_ GTW_w409_unexpectedResetCause m6 : 52|1@1+ (1,0) [0|1] "" Vector__XXX
 SG_ GTW_w410_unexpectedResetCause2 m6 : 53|1@1+ (1,0) [0|1] "" Vector__XXX
 SG_ GTW_w411_tASILStatusCheck m6 : 54|1@1+ (1,0) [0|1] "" Vector__XXX
 SG_ GTW_w414_socHeldInReset m6 : 57|1@1+ (1,0) [0|1] "" Vector__XXX
 SG_ GTW_w418_TRCMversionMismatch m6 : 61|1@1+ (1,0) [0|1] "" Vector__XXX
 SG_ GTW_w420_unexpectedCanMessageLen m6 : 63|1@1+ (1,0) [0|1] "" Vector__XXX
 SG_ GTW_w421_ModemEthLinkDown m7 : 4|1@1+ (1,0) [0|1] "" Vector__XXX
 SG_ GTW_w422_ethSwitchSevereCongesti m7 : 5|1@1+ (1,0) [0|1] "" Vector__XXX
 SG_ GTW_w427_DISPBRIDGEversionMismat m7 : 10|1@1+ (1,0) [0|1] "" Vector__XXX
 SG_ GTW_w428_LUMBAR32LversionMismatc m7 : 11|1@1+ (1,0) [0|1] "" Vector__XXX
 SG_ GTW_w429_LUMBAR32RversionMismatc m7 : 12|1@1+ (1,0) [0|1] "" Vector__XXX
 SG_ GTW_w436_possibleCanRxIssue m7 : 19|1@1+ (1,0) [0|1] "" Vector__XXX
 SG_ GTW_w437_softFlowControlNotRunni m7 : 20|1@1+ (1,0) [0|1] "" Vector__XXX
 SG_ GTW_w438_wakeSourceUnknown m7 : 21|1@1+ (1,0) [0|1] "" Vector__XXX
 SG_ GTW_w439_VCCCversionMismatch m7 : 22|1@1+ (1,0) [0|1] "" Vector__XXX
 SG_ GTW_w450_unexpectedAutopilotCont m7 : 33|1@1+ (1,0) [0|1] "" Vector__XXX
 SG_ GTW_w451_diagCanBufferExhausted m7 : 34|1@1+ (1,0) [0|1] "" Vector__XXX
 SG_ GTW_w452_diagCanStaleSocket m7 : 35|1@1+ (1,0) [0|1] "" Vector__XXX
 SG_ GTW_w453_diagCanFdSetDesync m7 : 36|1@1+ (1,0) [0|1] "" Vector__XXX
 SG_ GTW_w454_diagCanFrameOverread m7 : 37|1@1+ (1,0) [0|1] "" Vector__XXX
 SG_ GTW_w455_hrlDumpPageOwnershipErr m7 : 38|1@1+ (1,0) [0|1] "" Vector__XXX
 SG_ GTW_w456_hrlStateMachinePageOwne m7 : 39|1@1+ (1,0) [0|1] "" Vector__XXX
 SG_ GTW_w463_displayEdidReadFailed m7 : 46|1@1+ (1,0) [0|1] "" Vector__XXX
 SG_ GTW_w469_backlightFsmUnhealthy m7 : 52|1@1+ (1,0) [0|1] "" Vector__XXX

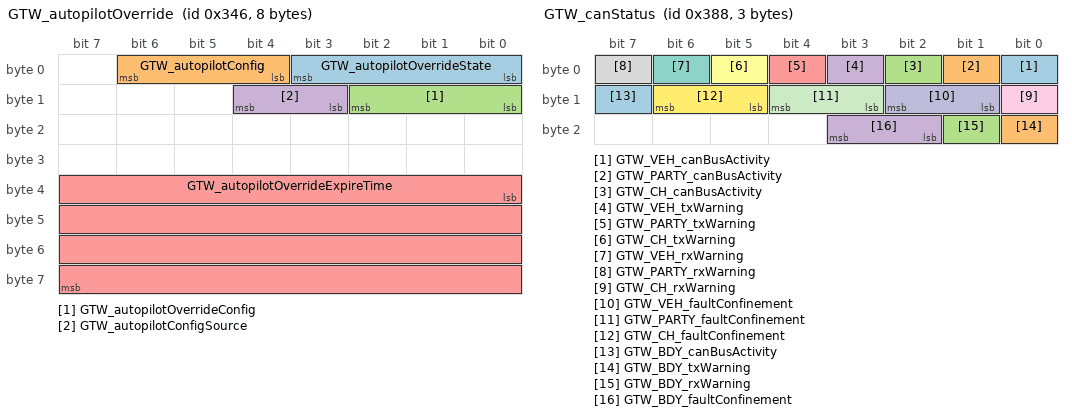
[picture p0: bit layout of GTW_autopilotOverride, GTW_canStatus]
BO_ 838 GTW_autopilotOverride: 8 GTW
 SG_ GTW_autopilotOverrideState : 0|4@1+ (1,0) [0|15] "" Vector__XXX
 SG_ GTW_autopilotConfig : 4|3@1+ (1,0) [0|7] "" Vector__XXX
 SG_ GTW_autopilotOverrideConfig : 8|3@1+ (1,0) [0|7] "" Vector__XXX
 SG_ GTW_autopilotConfigSource : 11|2@1+ (1,0) [0|3] "" Vector__XXX
 SG_ GTW_autopilotOverrideExpireTime : 32|32@1+ (1,0) [0|4294967295] "" Vector__XXX

BO_ 904 GTW_canStatus: 3 GTW
 SG_ GTW_VEH_canBusActivity : 0|1@1+ (1,0) [0|1] "" Vector__XXX
 SG_ GTW_PARTY_canBusActivity : 1|1@1+ (1,0) [0|1] "" Vector__XXX
 SG_ GTW_CH_canBusActivity : 2|1@1+ (1,0) [0|1] "" Vector__XXX
 SG_ GTW_VEH_txWarning : 3|1@1+ (1,0) [0|1] "" Vector__XXX
 SG_ GTW_PARTY_txWarning : 4|1@1+ (1,0) [0|1] "" Vector__XXX
 SG_ GTW_CH_txWarning : 5|1@1+ (1,0) [0|1] "" Vector__XXX
 SG_ GTW_VEH_rxWarning : 6|1@1+ (1,0) [0|1] "" Vector__XXX
 SG_ GTW_PARTY_rxWarning : 7|1@1+ (1,0) [0|1] "" Vector__XXX
 SG_ GTW_CH_rxWarning : 8|1@1+ (1,0) [0|1] "" Vector__XXX
 SG_ GTW_VEH_faultConfinement : 9|2@1+ (1,0) [0|3] "" Vector__XXX
 SG_ GTW_PARTY_faultConfinement : 11|2@1+ (1,0) [0|3] "" Vector__XXX
 SG_ GTW_CH_faultConfinement : 13|2@1+ (1,0) [0|3] "" Vector__XXX
 SG_ GTW_BDY_canBusActivity : 15|1@1+ (1,0) [0|1] "" Vector__XXX
 SG_ GTW_BDY_txWarning : 16|1@1+ (1,0) [0|1] "" Vector__XXX
 SG_ GTW_BDY_rxWarning : 17|1@1+ (1,0) [0|1] "" Vector__XXX
 SG_ GTW_BDY_faultConfinement : 18|2@1+ (1,0) [0|3] "" Vector__XXX

BO_ 792 GTW_carState: 8 GTW
 SG_ GTW_factoryGated : 48|1@1+ (1,0) [0|1] "" Vector__XXX

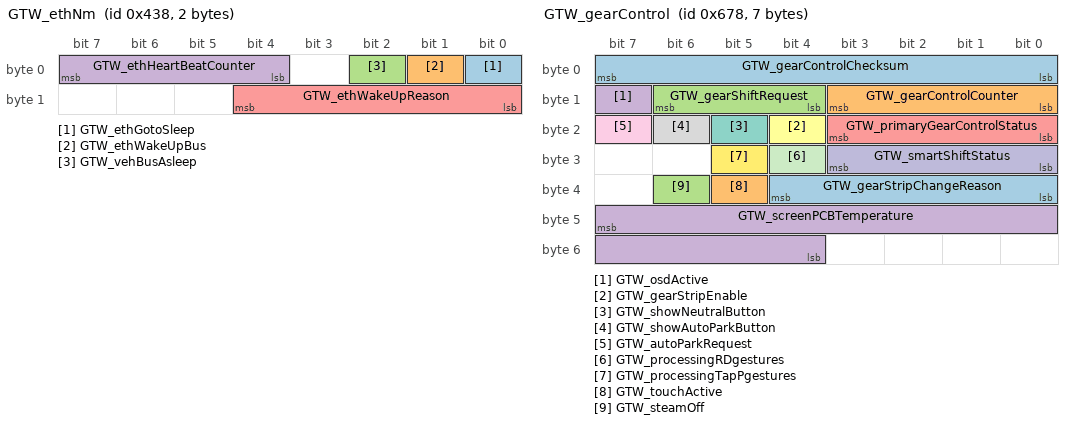
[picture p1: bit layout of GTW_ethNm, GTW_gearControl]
BO_ 1080 GTW_ethNm: 2 GTW
 SG_ GTW_ethGotoSleep : 0|1@1+ (1,0) [0|1] "" Vector__XXX
 SG_ GTW_ethWakeUpBus : 1|1@1+ (1,0) [0|1] "" Vector__XXX
 SG_ GTW_vehBusAsleep : 2|1@1+ (1,0) [0|1] "" Vector__XXX
 SG_ GTW_ethHeartBeatCounter : 4|4@1+ (1,0) [0|15] "" Vector__XXX
 SG_ GTW_ethWakeUpReason : 8|5@1+ (1,0) [0|31] "" Vector__XXX

BO_ 1376 GTW_factoryEcuPresent: 4 GTW
 SG_ GTW_OCS1Ppresent : 0|1@1+ (1,0) [0|1] "" Vector__XXX
 SG_ GTW_PCSpresent : 1|1@1+ (1,0) [0|1] "" Vector__XXX
 SG_ GTW_HVPpresent : 2|1@1+ (1,0) [0|1] "" Vector__XXX
 SG_ GTW_BMSpresent : 3|1@1+ (1,0) [0|1] "" Vector__XXX
 SG_ GTW_CPpresent : 4|1@1+ (1,0) [0|1] "" Vector__XXX
 SG_ GTW_RCMpresent : 5|1@1+ (1,0) [0|1] "" Vector__XXX
 SG_ GTW_SCCMpresent : 6|1@1+ (1,0) [0|1] "" Vector__XXX
 SG_ GTW_VCSECpresent : 7|1@1+ (1,0) [0|1] "" Vector__XXX
 SG_ GTW_EPAS3Ppresent : 8|1@1+ (1,0) [0|1] "" Vector__XXX
 SG_ GTW_EPBLpresent : 9|1@1+ (1,0) [0|1] "" Vector__XXX
 SG_ GTW_EPBRpresent : 10|1@1+ (1,0) [0|1] "" Vector__XXX
 SG_ GTW_ESPpresent : 11|1@1+ (1,0) [0|1] "" Vector__XXX
 SG_ GTW_IBSTpresent : 12|1@1+ (1,0) [0|1] "" Vector__XXX
 SG_ GTW_PARKpresent : 13|1@1+ (1,0) [0|1] "" Vector__XXX
 SG_ GTW_RADCpresent : 14|1@1+ (1,0) [0|1] "" Vector__XXX
 SG_ GTW_TPMSpresent : 15|1@1+ (1,0) [0|1] "" Vector__XXX
 SG_ GTW_VCFRONTpresent : 16|1@1+ (1,0) [0|1] "" Vector__XXX
 SG_ GTW_VCLEFTpresent : 17|1@1+ (1,0) [0|1] "" Vector__XXX
 SG_ GTW_VCRIGHTpresent : 18|1@1+ (1,0) [0|1] "" Vector__XXX
 SG_ GTW_EPAS3Spresent : 19|1@1+ (1,0) [0|1] "" Vector__XXX
 SG_ GTW_CMPpresent : 20|1@1+ (1,0) [0|1] "" Vector__XXX
 SG_ GTW_DASpresent : 21|1@1+ (1,0) [0|1] "" Vector__XXX
 SG_ GTW_PTCpresent : 22|1@1+ (1,0) [0|1] "" Vector__XXX
 SG_ GTW_SWCpresent : 23|1@1+ (1,0) [0|1] "" Vector__XXX
 SG_ GTW_PMRpresent : 25|1@1+ (1,0) [0|1] "" Vector__XXX
 SG_ GTW_PMFpresent : 26|1@1+ (1,0) [0|1] "" Vector__XXX
 SG_ GTW_DIRpresent : 27|1@1+ (1,0) [0|1] "" Vector__XXX
 SG_ GTW_DIFpresent : 28|1@1+ (1,0) [0|1] "" Vector__XXX

BO_ 1656 GTW_gearControl: 7 GTW
 SG_ GTW_gearControlChecksum : 0|8@1+ (1,0) [0|255] "" Vector__XXX
 SG_ GTW_gearControlCounter : 8|4@1+ (1,0) [0|15] "" Vector__XXX
 SG_ GTW_gearShiftRequest : 12|3@1+ (1,0) [1|7] "" Vector__XXX
 SG_ GTW_osdActive : 15|1@1+ (1,0) [0|1] "" Vector__XXX
 SG_ GTW_primaryGearControlStatus : 16|4@1+ (1,0) [0|15] "" Vector__XXX
 SG_ GTW_gearStripEnable : 20|1@1+ (1,0) [0|1] "" Vector__XXX
 SG_ GTW_showNeutralButton : 21|1@1+ (1,0) [0|1] "" Vector__XXX
 SG_ GTW_showAutoParkButton : 22|1@1+ (1,0) [0|1] "" Vector__XXX
 SG_ GTW_autoParkRequest : 23|1@1+ (1,0) [0|1] "" Vector__XXX
 SG_ GTW_smartShiftStatus : 24|4@1+ (1,0) [1|15] "" Vector__XXX
 SG_ GTW_processingRDgestures : 28|1@1+ (1,0) [0|1] "" Vector__XXX
 SG_ GTW_processingTapPgestures : 29|1@1+ (1,0) [0|1] "" Vector__XXX
 SG_ GTW_gearStripChangeReason : 32|5@1+ (1,0) [1|31] "" Vector__XXX
 SG_ GTW_touchActive : 37|1@1+ (1,0) [0|1] "" Vector__XXX
 SG_ GTW_steamOff : 38|1@1+ (1,0) [0|1] "" Vector__XXX
 SG_ GTW_screenPCBTemperature : 47|12@0- (0.0625,0) [-128|127.875] "degC" Vector__XXX

BO_ 2033 GTW_hrl: 7 GTW
 SG_ GTW_hrlIndex M : 0|2@1+ (1,0) [0|3] "" Vector__XXX
 SG_ GTW_hrlPagesCount m1 : 15|32@0+ (1,0) [0|4294967295] "" Vector__XXX
 SG_ GTW_hrlSdCardSizeGB m1 : 40|8@1+ (1,0) [1|255] "" Vector__XXX
 SG_ GTW_hrlState m2 : 2|1@1+ (1,0) [0|1] "" Vector__XXX
 SG_ GTW_hrlTriggerDuration m2 : 15|16@0+ (1,0) [0|65535] "seconds" Vector__XXX
 SG_ GTW_hrlTriggerType m2 : 24|4@1+ (1,0) [0|15] "" Vector__XXX
 SG_ GTW_hrlTriggerId m2 : 39|16@0+ (1,0) [0|65535] "" Vector__XXX
 SG_ GTW_hrlTriggerBus m2 : 53|3@1+ (1,0) [0|7] "" Vector__XXX

BO_ 2026 GTW_hrlExternalEvent: 8 GTW
 SG_ GTW_hrlEventStartEpoch : 7|32@0+ (1,0) [0|4294967295] "seconds" Vector__XXX
 SG_ GTW_hrlEventEndEpoch : 39|32@0+ (1,0) [0|4294967295] "seconds" Vector__XXX

BO_ 60 GTW_info: 8 GTW
 SG_ GTW_infoIndex M : 0|8@1+ (1,0) [0|255] "" Vector__XXX
 SG_ GTW_buildType m10 : 8|3@1+ (1,0) [0|7] "" Vector__XXX
 SG_ GTW_hardwareId m10 : 32|16@1+ (1,0) [0|65535] "" Vector__XXX
 SG_ GTW_platformType m13 : 8|8@1+ (1,0) [0|255] "" Vector__XXX
 SG_ GTW_appCrc m13 : 32|32@1+ (1,0) [0|4294967295] "" Vector__XXX
 SG_ GTW_applicationGitHash m17 : 8|56@1+ (1,0) [0|7.20575940379e+16] "" Vector__XXX
 SG_ GTW_bootGitHash m18 : 8|56@1+ (1,0) [0|7.20575940379e+16] "" Vector__XXX

BO_ 1370 GTW_mismatchFault: 8 GTW
 SG_ GTW_mismatchFaultIndex M : 0|3@1+ (1,0) [0|7] "" Vector__XXX
 SG_ GTW_mismatchFaultChecksum : 3|8@1+ (1,0) [0|255] "" Vector__XXX
 SG_ GTW_mismatchFaultCounter : 11|4@1+ (1,0) [0|15] "" Vector__XXX
 SG_ GTW_GTWmismatchFault m1 : 15|1@1+ (1,0) [0|1] "" Vector__XXX
 SG_ GTW_BMSmismatchFault m1 : 16|1@1+ (1,0) [0|1] "" Vector__XXX
 SG_ GTW_APSmismatchFault m1 : 17|1@1+ (1,0) [0|1] "" Vector__XXX
 SG_ GTW_BLEEPCENTERmismatchFault m1 : 18|1@1+ (1,0) [0|1] "" Vector__XXX
 SG_ GTW_BLEEPLEFTmismatchFault m1 : 19|1@1+ (1,0) [0|1] "" Vector__XXX
 SG_ GTW_BLEEPREARmismatchFault m1 : 20|1@1+ (1,0) [0|1] "" Vector__XXX
 SG_ GTW_BLEEPRIGHTmismatchFault m1 : 21|1@1+ (1,0) [0|1] "" Vector__XXX
 SG_ GTW_CBCmismatchFault m1 : 22|1@1+ (1,0) [0|1] "" Vector__XXX
 SG_ GTW_CMPmismatchFault m1 : 23|1@1+ (1,0) [0|1] "" Vector__XXX
 SG_ GTW_CPmismatchFault m1 : 24|1@1+ (1,0) [0|1] "" Vector__XXX
 SG_ GTW_DIFmismatchFault m1 : 25|1@1+ (1,0) [0|1] "" Vector__XXX
 SG_ GTW_DIRmismatchFault m1 : 26|1@1+ (1,0) [0|1] "" Vector__XXX
 SG_ GTW_EPAS3PmismatchFault m1 : 27|1@1+ (1,0) [0|1] "" Vector__XXX
 SG_ GTW_EPAS3SmismatchFault m1 : 28|1@1+ (1,0) [0|1] "" Vector__XXX
 SG_ GTW_EPBLmismatchFault m1 : 29|1@1+ (1,0) [0|1] "" Vector__XXX
 SG_ GTW_EPBRmismatchFault m1 : 30|1@1+ (1,0) [0|1] "" Vector__XXX
 SG_ GTW_ESPCALmismatchFault m1 : 31|1@1+ (1,0) [0|1] "" Vector__XXX
 SG_ GTW_ESPmismatchFault m1 : 32|1@1+ (1,0) [0|1] "" Vector__XXX
 SG_ GTW_HCM3LmismatchFault m1 : 33|1@1+ (1,0) [0|1] "" Vector__XXX
 SG_ GTW_HCM3RmismatchFault m1 : 34|1@1+ (1,0) [0|1] "" Vector__XXX
 SG_ GTW_HCMLmismatchFault m1 : 35|1@1+ (1,0) [0|1] "" Vector__XXX
 SG_ GTW_HCMRmismatchFault m1 : 36|1@1+ (1,0) [0|1] "" Vector__XXX
 SG_ GTW_HVPmismatchFault m1 : 37|1@1+ (1,0) [0|1] "" Vector__XXX
 SG_ GTW_IBSTCALmismatchFault m1 : 38|1@1+ (1,0) [0|1] "" Vector__XXX
 SG_ GTW_IBSTmismatchFault m1 : 39|1@1+ (1,0) [0|1] "" Vector__XXX
 SG_ GTW_LVBMSmismatchFault m1 : 40|1@1+ (1,0) [0|1] "" Vector__XXX
 SG_ GTW_OCS1PmismatchFault m1 : 41|1@1+ (1,0) [0|1] "" Vector__XXX
 SG_ GTW_OPCFmismatchFault m1 : 42|1@1+ (1,0) [0|1] "" Vector__XXX
 SG_ GTW_OPCRmismatchFault m1 : 43|1@1+ (1,0) [0|1] "" Vector__XXX
 SG_ GTW_PARKmismatchFault m1 : 44|1@1+ (1,0) [0|1] "" Vector__XXX
 SG_ GTW_PCSCPU2mismatchFault m1 : 45|1@1+ (1,0) [0|1] "" Vector__XXX
 SG_ GTW_PCSmismatchFault m1 : 46|1@1+ (1,0) [0|1] "" Vector__XXX
 SG_ GTW_PMFmismatchFault m1 : 47|1@1+ (1,0) [0|1] "" Vector__XXX
 SG_ GTW_PMRmismatchFault m1 : 48|1@1+ (1,0) [0|1] "" Vector__XXX
 SG_ GTW_PTCmismatchFault m1 : 49|1@1+ (1,0) [0|1] "" Vector__XXX
 SG_ GTW_RCMCALmismatchFault m1 : 50|1@1+ (1,0) [0|1] "" Vector__XXX
 SG_ GTW_RCMmismatchFault m1 : 51|1@1+ (1,0) [0|1] "" Vector__XXX
 SG_ GTW_SCCMmismatchFault m1 : 52|1@1+ (1,0) [0|1] "" Vector__XXX
 SG_ GTW_SDCRmismatchFault m1 : 53|1@1+ (1,0) [0|1] "" Vector__XXX
 SG_ GTW_SWCmismatchFault m1 : 54|1@1+ (1,0) [0|1] "" Vector__XXX
 SG_ GTW_THSmismatchFault m1 : 55|1@1+ (1,0) [0|1] "" Vector__XXX
 SG_ GTW_VCFRONTmismatchFault m1 : 56|1@1+ (1,0) [0|1] "" Vector__XXX
 SG_ GTW_VCLEFTmismatchFault m1 : 57|1@1+ (1,0) [0|1] "" Vector__XXX
 SG_ GTW_VCRIGHTmismatchFault m1 : 58|1@1+ (1,0) [0|1] "" Vector__XXX
 SG_ GTW_VCSECmismatchFault m1 : 59|1@1+ (1,0) [0|1] "" Vector__XXX
 SG_ GTW_PMmismatchFault m1 : 60|1@1+ (1,0) [0|1] "" Vector__XXX

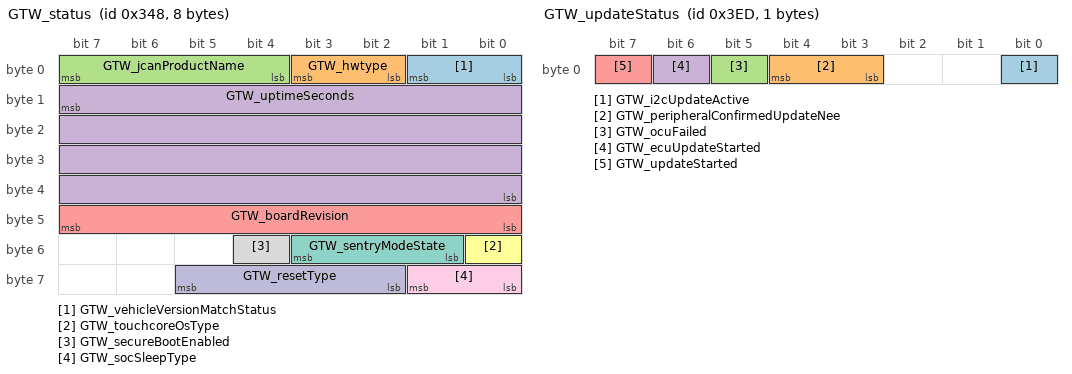
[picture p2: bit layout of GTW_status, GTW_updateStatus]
BO_ 840 GTW_status: 8 GTW
 SG_ GTW_vehicleVersionMatchStatus : 0|2@1+ (1,0) [0|3] "" Vector__XXX
 SG_ GTW_hwtype : 2|2@1+ (1,0) [1|3] "" Vector__XXX
 SG_ GTW_jcanProductName : 4|4@1+ (1,0) [1|15] "" Vector__XXX
 SG_ GTW_uptimeSeconds : 15|32@0+ (1,0) [0|4294967295] "s" Vector__XXX
 SG_ GTW_boardRevision : 40|8@1+ (1,0) [0|255] "" Vector__XXX
 SG_ GTW_touchcoreOsType : 48|1@1+ (1,0) [0|1] "" Vector__XXX
 SG_ GTW_sentryModeState : 49|3@1+ (1,0) [0|7] "" Vector__XXX
 SG_ GTW_secureBootEnabled : 52|1@1+ (1,0) [0|1] "" Vector__XXX
 SG_ GTW_socSleepType : 56|2@1+ (1,0) [1|3] "" Vector__XXX
 SG_ GTW_resetType : 58|4@1+ (1,0) [1|15] "" Vector__XXX

BO_ 1005 GTW_updateStatus: 1 GTW
 SG_ GTW_i2cUpdateActive : 0|1@1+ (1,0) [0|1] "" Vector__XXX
 SG_ GTW_peripheralConfirmedUpdateNee : 3|2@1+ (1,0) [0|3] "" Vector__XXX
 SG_ GTW_ocuFailed : 5|1@1+ (1,0) [0|1] "" Vector__XXX
 SG_ GTW_ecuUpdateStarted : 6|1@1+ (1,0) [0|1] "" Vector__XXX
 SG_ GTW_updateStarted : 7|1@1+ (1,0) [0|1] "" Vector__XXX

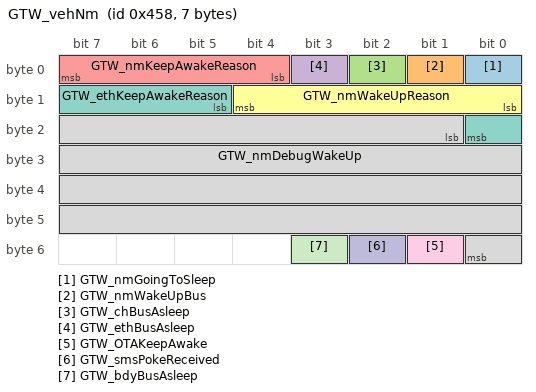
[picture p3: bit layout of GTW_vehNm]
BO_ 1112 GTW_vehNm: 7 GTW
 SG_ GTW_nmGoingToSleep : 0|1@1+ (1,0) [0|1] "" Vector__XXX
 SG_ GTW_nmWakeUpBus : 1|1@1+ (1,0) [0|1] "" Vector__XXX
 SG_ GTW_chBusAsleep : 2|1@1+ (1,0) [0|1] "" Vector__XXX
 SG_ GTW_ethBusAsleep : 3|1@1+ (1,0) [0|1] "" Vector__XXX
 SG_ GTW_nmKeepAwakeReason : 4|4@1+ (1,0) [1|15] "" Vector__XXX
 SG_ GTW_nmWakeUpReason : 8|5@1+ (1,0) [0|31] "" Vector__XXX
 SG_ GTW_ethKeepAwakeReason : 13|4@1+ (1,0) [1|15] "" Vector__XXX
 SG_ GTW_nmDebugWakeUp : 17|32@1+ (1,0) [0|4294967295] "" Vector__XXX
 SG_ GTW_OTAKeepAwake : 49|1@1+ (1,0) [0|1] "" Vector__XXX
 SG_ GTW_smsPokeReceived : 50|1@1+ (1,0) [0|1] "" Vector__XXX
 SG_ GTW_bdyBusAsleep : 51|1@1+ (1,0) [0|1] "" Vector__XXX

BO_ 1470 IDB_alertLog: 8 IDB
 SG_ IDB_alertID M : 0|8@1+ (1,0) [0|255] "" Vector__XXX
 SG_ IDB_alertState : 15|1@1+ (1,0) [0|1] "" Vector__XXX
 SG_ IDB_a014_wheelSpeedSensorFreq m14 : 16|1@1+ (1,0) [0|1] "" Vector__XXX
 SG_ IDB_a014_wheelSpeedSensorPhase m14 : 17|1@1+ (1,0) [0|1] "" Vector__XXX
 SG_ IDB_a014_wheelSpeedSensorMisinst m14 : 18|1@1+ (1,0) [0|1] "" Vector__XXX
 SG_ IDB_a014_wheelSpeedSensorWrongEx m14 : 19|1@1+ (1,0) [0|1] "" Vector__XXX
 SG_ IDB_a014_wheelSpeedSensorSpeedJu m14 : 20|1@1+ (1,0) [0|1] "" Vector__XXX
 SG_ IDB_a014_wheelSpeedSensorSp_0001 m14 : 21|1@1+ (1,0) [0|1] "" Vector__XXX
 SG_ IDB_a014_wheelSpeedSensorAirGap m14 : 22|1@1+ (1,0) [0|1] "" Vector__XXX
 SG_ IDB_a014_wheelSpeedSensorBIST m14 : 23|1@1+ (1,0) [0|1] "" Vector__XXX
 SG_ IDB_a014_wheelSpeedSensorLeakage m14 : 24|1@1+ (1,0) [0|1] "" Vector__XXX
 SG_ IDB_a014_wheelSpeedSensorOverTem m14 : 25|1@1+ (1,0) [0|1] "" Vector__XXX
 SG_ IDB_a014_wheelSpeedSensorSh_0001 m14 : 26|1@1+ (1,0) [0|1] "" Vector__XXX
 SG_ IDB_a014_wheelSpeedSensorShortTo m14 : 27|1@1+ (1,0) [0|1] "" Vector__XXX
 SG_ IDB_a014_wheelSpeedSensorOpen m14 : 28|1@1+ (1,0) [0|1] "" Vector__XXX
 SG_ IDB_a015_wheelSpeedSensorFreq m15 : 16|1@1+ (1,0) [0|1] "" Vector__XXX
 SG_ IDB_a015_wheelSpeedSensorPhase m15 : 17|1@1+ (1,0) [0|1] "" Vector__XXX
 SG_ IDB_a015_wheelSpeedSensorMisinst m15 : 18|1@1+ (1,0) [0|1] "" Vector__XXX
 SG_ IDB_a015_wheelSpeedSensorWrongEx m15 : 19|1@1+ (1,0) [0|1] "" Vector__XXX
 SG_ IDB_a015_wheelSpeedSensorSpeedJu m15 : 20|1@1+ (1,0) [0|1] "" Vector__XXX
 SG_ IDB_a015_wheelSpeedSensorSp_0001 m15 : 21|1@1+ (1,0) [0|1] "" Vector__XXX
 SG_ IDB_a015_wheelSpeedSensorAirGap m15 : 22|1@1+ (1,0) [0|1] "" Vector__XXX
 SG_ IDB_a015_wheelSpeedSensorBIST m15 : 23|1@1+ (1,0) [0|1] "" Vector__XXX
 SG_ IDB_a015_wheelSpeedSensorLeakage m15 : 24|1@1+ (1,0) [0|1] "" Vector__XXX
 SG_ IDB_a015_wheelSpeedSensorOverTem m15 : 25|1@1+ (1,0) [0|1] "" Vector__XXX
 SG_ IDB_a015_wheelSpeedSensorSh_0001 m15 : 26|1@1+ (1,0) [0|1] "" Vector__XXX
 SG_ IDB_a015_wheelSpeedSensorShortTo m15 : 27|1@1+ (1,0) [0|1] "" Vector__XXX
 SG_ IDB_a015_wheelSpeedSensorOpen m15 : 28|1@1+ (1,0) [0|1] "" Vector__XXX
 SG_ IDB_a016_wheelSpeedSensorFreq m16 : 16|1@1+ (1,0) [0|1] "" Vector__XXX
 SG_ IDB_a016_wheelSpeedSensorPhase m16 : 17|1@1+ (1,0) [0|1] "" Vector__XXX
 SG_ IDB_a016_wheelSpeedSensorMisinst m16 : 18|1@1+ (1,0) [0|1] "" Vector__XXX
 SG_ IDB_a016_wheelSpeedSensorWrongEx m16 : 19|1@1+ (1,0) [0|1] "" Vector__XXX
 SG_ IDB_a016_wheelSpeedSensorSpeedJu m16 : 20|1@1+ (1,0) [0|1] "" Vector__XXX
 SG_ IDB_a016_wheelSpeedSensorSp_0001 m16 : 21|1@1+ (1,0) [0|1] "" Vector__XXX
 SG_ IDB_a016_wheelSpeedSensorAirGap m16 : 22|1@1+ (1,0) [0|1] "" Vector__XXX
 SG_ IDB_a016_wheelSpeedSensorBIST m16 : 23|1@1+ (1,0) [0|1] "" Vector__XXX
 SG_ IDB_a016_wheelSpeedSensorLeakage m16 : 24|1@1+ (1,0) [0|1] "" Vector__XXX
 SG_ IDB_a016_wheelSpeedSensorOverTem m16 : 25|1@1+ (1,0) [0|1] "" Vector__XXX
 SG_ IDB_a016_wheelSpeedSensorSh_0001 m16 : 26|1@1+ (1,0) [0|1] "" Vector__XXX
 SG_ IDB_a016_wheelSpeedSensorShortTo m16 : 27|1@1+ (1,0) [0|1] "" Vector__XXX
 SG_ IDB_a016_wheelSpeedSensorOpen m16 : 28|1@1+ (1,0) [0|1] "" Vector__XXX
 SG_ IDB_a017_wheelSpeedSensorFreq m17 : 16|1@1+ (1,0) [0|1] "" Vector__XXX
 SG_ IDB_a017_wheelSpeedSensorPhase m17 : 17|1@1+ (1,0) [0|1] "" Vector__XXX
 SG_ IDB_a017_wheelSpeedSensorMisinst m17 : 18|1@1+ (1,0) [0|1] "" Vector__XXX
 SG_ IDB_a017_wheelSpeedSensorWrongEx m17 : 19|1@1+ (1,0) [0|1] "" Vector__XXX
 SG_ IDB_a017_wheelSpeedSensorSpeedJu m17 : 20|1@1+ (1,0) [0|1] "" Vector__XXX
 SG_ IDB_a017_wheelSpeedSensorSp_0001 m17 : 21|1@1+ (1,0) [0|1] "" Vector__XXX
 SG_ IDB_a017_wheelSpeedSensorAirGap m17 : 22|1@1+ (1,0) [0|1] "" Vector__XXX
 SG_ IDB_a017_wheelSpeedSensorBIST m17 : 23|1@1+ (1,0) [0|1] "" Vector__XXX
 SG_ IDB_a017_wheelSpeedSensorLeakage m17 : 24|1@1+ (1,0) [0|1] "" Vector__XXX
 SG_ IDB_a017_wheelSpeedSensorOverTem m17 : 25|1@1+ (1,0) [0|1] "" Vector__XXX
 SG_ IDB_a017_wheelSpeedSensorSh_0001 m17 : 26|1@1+ (1,0) [0|1] "" Vector__XXX
 SG_ IDB_a017_wheelSpeedSensorShortTo m17 : 27|1@1+ (1,0) [0|1] "" Vector__XXX
 SG_ IDB_a017_wheelSpeedSensorOpen m17 : 28|1@1+ (1,0) [0|1] "" Vector__XXX
 SG_ IDB_a020_canSignalValidity m20 : 16|1@1+ (1,0) [0|1] "" Vector__XXX
 SG_ IDB_a020_signalValueCrosscheck m20 : 17|1@1+ (1,0) [0|1] "" Vector__XXX
 SG_ IDB_a030_primaryExternalCircuitL m30 : 16|1@1+ (1,0) [0|1] "" Vector__XXX
 SG_ IDB_a030_secondaryExternalCircui m30 : 17|1@1+ (1,0) [0|1] "" Vector__XXX
 SG_ IDB_a030_primaryChamberInternalL m30 : 18|1@1+ (1,0) [0|1] "" Vector__XXX
 SG_ IDB_a030_syncModeInternalLeakage m30 : 19|1@1+ (1,0) [0|1] "" Vector__XXX
 SG_ IDB_a030_secondaryChamberInterna m30 : 20|1@1+ (1,0) [0|1] "" Vector__XXX
 SG_ IDB_a030_masterCylinderInternalL m30 : 21|1@1+ (1,0) [0|1] "" Vector__XXX
 SG_ IDB_a060_validityOnChassisBus m60 : 16|1@1+ (1,0) [0|1] "" Vector__XXX
 SG_ IDB_a060_validityOnPartyBus m60 : 17|1@1+ (1,0) [0|1] "" Vector__XXX
 SG_ IDB_a061_validityOnChassisBus m61 : 16|1@1+ (1,0) [0|1] "" Vector__XXX
 SG_ IDB_a061_validityOnPartyBus m61 : 17|1@1+ (1,0) [0|1] "" Vector__XXX
 SG_ IDB_a063_validityOnChassisBus m63 : 16|1@1+ (1,0) [0|1] "" Vector__XXX
 SG_ IDB_a063_validityOnPartyBus m63 : 17|1@1+ (1,0) [0|1] "" Vector__XXX
 SG_ IDB_a064_validityOnChassisBus m64 : 16|1@1+ (1,0) [0|1] "" Vector__XXX
 SG_ IDB_a064_validityOnPartyBus m64 : 17|1@1+ (1,0) [0|1] "" Vector__XXX
 SG_ IDB_a065_validityOnChassisBus m65 : 16|1@1+ (1,0) [0|1] "" Vector__XXX
 SG_ IDB_a065_validityOnPartyBus m65 : 17|1@1+ (1,0) [0|1] "" Vector__XXX
 SG_ IDB_a106_qualifierValidity m106 : 16|1@1+ (1,0) [0|1] "" Vector__XXX
 SG_ IDB_a106_signalNotAvailable m106 : 17|1@1+ (1,0) [0|1] "" Vector__XXX
 SG_ IDB_a107_qualifierValidity m107 : 16|1@1+ (1,0) [0|1] "" Vector__XXX
 SG_ IDB_a107_signalNotAvailable m107 : 17|1@1+ (1,0) [0|1] "" Vector__XXX
 SG_ IDB_a112_qualifierValidity m112 : 16|1@1+ (1,0) [0|1] "" Vector__XXX
 SG_ IDB_a112_signalNotAvailable m112 : 17|1@1+ (1,0) [0|1] "" Vector__XXX
 SG_ IDB_a113_qualifierValidity m113 : 16|1@1+ (1,0) [0|1] "" Vector__XXX
 SG_ IDB_a113_signalNotAvailable m113 : 17|1@1+ (1,0) [0|1] "" Vector__XXX
 SG_ IDB_a114_qualifierValidity m114 : 16|1@1+ (1,0) [0|1] "" Vector__XXX
 SG_ IDB_a114_signalNotAvailable m114 : 17|1@1+ (1,0) [0|1] "" Vector__XXX
 SG_ IDB_a126_PMebrCmdStateValidity m126 : 16|1@1+ (1,0) [0|1] "" Vector__XXX
 SG_ IDB_a126_PMstate2Validity m126 : 17|1@1+ (1,0) [0|1] "" Vector__XXX
 SG_ IDB_a126_PMstate2Missing m126 : 18|1@1+ (1,0) [0|1] "" Vector__XXX
 SG_ IDB_a126_DIchassisControlValidit m126 : 19|1@1+ (1,0) [0|1] "" Vector__XXX
 SG_ IDB_a126_DIchassisControlMissing m126 : 20|1@1+ (1,0) [0|1] "" Vector__XXX
 SG_ IDB_a126_DIrequestActiveValidity m126 : 21|1@1+ (1,0) [0|1] "" Vector__XXX
 SG_ IDB_a129_validityOnChassisBus m129 : 16|1@1+ (1,0) [0|1] "" Vector__XXX
 SG_ IDB_a129_validityOnPartyBus m129 : 17|1@1+ (1,0) [0|1] "" Vector__XXX
 SG_ IDB_a130_PMbrakePedalCmdQFValidi m130 : 16|1@1+ (1,0) [0|1] "" Vector__XXX
 SG_ IDB_a130_PMstate2Validity m130 : 17|1@1+ (1,0) [0|1] "" Vector__XXX
 SG_ IDB_a130_PMstate2Missing m130 : 18|1@1+ (1,0) [0|1] "" Vector__XXX
 SG_ IDB_a130_DIbrakeCommandValidity m130 : 19|1@1+ (1,0) [0|1] "" Vector__XXX
 SG_ IDB_a130_DIbrakeCommandMissing m130 : 20|1@1+ (1,0) [0|1] "" Vector__XXX
 SG_ IDB_a130_DIbrakeTorqueCommandFul m130 : 21|1@1+ (1,0) [0|1] "" Vector__XXX
 SG_ IDB_a130_DIbrakeTorqueComma_0001 m130 : 22|1@1+ (1,0) [0|1] "" Vector__XXX
 SG_ IDB_a132_validityOnChassisBus m132 : 16|1@1+ (1,0) [0|1] "" Vector__XXX
 SG_ IDB_a132_validityOnPartyBus m132 : 17|1@1+ (1,0) [0|1] "" Vector__XXX

BO_ 983 IDB_alertMatrix: 8 IDB
 SG_ IDB_matrixIndex M : 0|4@1+ (1,0) [0|15] "" Vector__XXX
 SG_ IDB_a001_mcuGenericFault m0 : 4|1@1+ (1,0) [0|1] "" Vector__XXX
 SG_ IDB_a002_supplyOvervoltage m0 : 5|1@1+ (1,0) [0|1] "" Vector__XXX
 SG_ IDB_a003_supplyHardOvervoltage m0 : 6|1@1+ (1,0) [0|1] "" Vector__XXX
 SG_ IDB_a004_supplyUndervoltage m0 : 7|1@1+ (1,0) [0|1] "" Vector__XXX
 SG_ IDB_a005_supplyMidUndervoltage m0 : 8|1@1+ (1,0) [0|1] "" Vector__XXX
 SG_ IDB_a006_supplyHardUndervoltage m0 : 9|1@1+ (1,0) [0|1] "" Vector__XXX
 SG_ IDB_a007_wakeLineOpen m0 : 10|1@1+ (1,0) [0|1] "" Vector__XXX
 SG_ IDB_a008_motorPowerOpen m0 : 11|1@1+ (1,0) [0|1] "" Vector__XXX
 SG_ IDB_a009_asicBoostFault m0 : 12|1@1+ (1,0) [0|1] "" Vector__XXX
 SG_ IDB_a010_asicGenericFault m0 : 13|1@1+ (1,0) [0|1] "" Vector__XXX
 SG_ IDB_a011_solenoidValveFault m0 : 14|1@1+ (1,0) [0|1] "" Vector__XXX
 SG_ IDB_a012_motorGenericFault m0 : 15|1@1+ (1,0) [0|1] "" Vector__XXX
 SG_ IDB_a013_motorPosSensorFault m0 : 16|1@1+ (1,0) [0|1] "" Vector__XXX
 SG_ IDB_a014_FrLWSSFault m0 : 17|1@1+ (1,0) [0|1] "" Vector__XXX
 SG_ IDB_a015_FrRWSSFault m0 : 18|1@1+ (1,0) [0|1] "" Vector__XXX
 SG_ IDB_a016_ReLWSSFault m0 : 19|1@1+ (1,0) [0|1] "" Vector__XXX
 SG_ IDB_a017_ReRWSSFault m0 : 20|1@1+ (1,0) [0|1] "" Vector__XXX
 SG_ IDB_a018_WSSGenericFault m0 : 21|1@1+ (1,0) [0|1] "" Vector__XXX
 SG_ IDB_a019_pedalSensorFault m0 : 22|1@1+ (1,0) [0|1] "" Vector__XXX
 SG_ IDB_a020_RCUpedalTravelMismatch m0 : 23|1@1+ (1,0) [0|1] "" Vector__XXX
 SG_ IDB_a021_pedalSensorNotCal m0 : 24|1@1+ (1,0) [0|1] "" Vector__XXX
 SG_ IDB_a022_brakeFluidLow m0 : 25|1@1+ (1,0) [0|1] "" Vector__XXX
 SG_ IDB_a023_steeringImplausible m0 : 26|1@1+ (1,0) [0|1] "" Vector__XXX
 SG_ IDB_a024_yawImplausible m0 : 27|1@1+ (1,0) [0|1] "" Vector__XXX
 SG_ IDB_a025_ayImplausible m0 : 28|1@1+ (1,0) [0|1] "" Vector__XXX
 SG_ IDB_a026_axImplausible m0 : 29|1@1+ (1,0) [0|1] "" Vector__XXX
 SG_ IDB_a027_circuitPresSensorFault m0 : 30|1@1+ (1,0) [0|1] "" Vector__XXX
 SG_ IDB_a028_simPresSensorFault m0 : 31|1@1+ (1,0) [0|1] "" Vector__XXX
 SG_ IDB_a029_pressureSensNotCal m0 : 32|1@1+ (1,0) [0|1] "" Vector__XXX
 SG_ IDB_a030_fluidLeakDetected m0 : 33|1@1+ (1,0) [0|1] "" Vector__XXX
 SG_ IDB_a031_solenoidValveStuck m0 : 34|1@1+ (1,0) [0|1] "" Vector__XXX
 SG_ IDB_a032_motorSoftOverheat m0 : 35|1@1+ (1,0) [0|1] "" Vector__XXX
 SG_ IDB_a033_motorHardOverheat m0 : 36|1@1+ (1,0) [0|1] "" Vector__XXX
 SG_ IDB_a034_motorPositionSetFault m0 : 37|1@1+ (1,0) [0|1] "" Vector__XXX
 SG_ IDB_a035_motorStuck m0 : 38|1@1+ (1,0) [0|1] "" Vector__XXX
 SG_ IDB_a036_partyBusOff m0 : 39|1@1+ (1,0) [0|1] "" Vector__XXX
 SG_ IDB_a037_chassisBusOff m0 : 40|1@1+ (1,0) [0|1] "" Vector__XXX
 SG_ IDB_a038_motorInitFault m0 : 41|1@1+ (1,0) [0|1] "" Vector__XXX
 SG_ IDB_a039_absActive m0 : 42|1@1+ (1,0) [0|1] "" Vector__XXX
 SG_ IDB_a040_ebdActive m0 : 43|1@1+ (1,0) [0|1] "" Vector__XXX
 SG_ IDB_a041_vdcActive m0 : 44|1@1+ (1,0) [0|1] "" Vector__XXX
 SG_ IDB_a042_btcActive m0 : 45|1@1+ (1,0) [0|1] "" Vector__XXX
 SG_ IDB_a043_cbcActive m0 : 46|1@1+ (1,0) [0|1] "" Vector__XXX
 SG_ IDB_a044_standstillSkidDetected m0 : 47|1@1+ (1,0) [0|1] "" Vector__XXX
 SG_ IDB_a045_panicBrakeAssistActive m0 : 48|1@1+ (1,0) [0|1] "" Vector__XXX
 SG_ IDB_a046_fadeCompensationActive m0 : 49|1@1+ (1,0) [0|1] "" Vector__XXX
 SG_ IDB_a047_brakeDiscWipeActive m0 : 50|1@1+ (1,0) [0|1] "" Vector__XXX
 SG_ IDB_a048_scmActive m0 : 51|1@1+ (1,0) [0|1] "" Vector__XXX
 SG_ IDB_a049_cdpActive m0 : 52|1@1+ (1,0) [0|1] "" Vector__XXX
 SG_ IDB_a050_absFaulted m0 : 53|1@1+ (1,0) [0|1] "" Vector__XXX
 SG_ IDB_a051_ebdFaulted m0 : 54|1@1+ (1,0) [0|1] "" Vector__XXX
 SG_ IDB_a052_vdcFaulted m0 : 55|1@1+ (1,0) [0|1] "" Vector__XXX
 SG_ IDB_a053_DItorquePathFaulted m0 : 56|1@1+ (1,0) [0|1] "" Vector__XXX
 SG_ IDB_a054_skidDetectionFaulted m0 : 57|1@1+ (1,0) [0|1] "" Vector__XXX
 SG_ IDB_a055_panicBrakeAssistFaulted m0 : 58|1@1+ (1,0) [0|1] "" Vector__XXX
 SG_ IDB_a056_fadeCompensationFaulted m0 : 59|1@1+ (1,0) [0|1] "" Vector__XXX
 SG_ IDB_a057_bdwRequestInvalid m0 : 60|1@1+ (1,0) [0|1] "" Vector__XXX
 SG_ IDB_a058_scmFaulted m0 : 61|1@1+ (1,0) [0|1] "" Vector__XXX
 SG_ IDB_a059_cdpFaulted m0 : 62|1@1+ (1,0) [0|1] "" Vector__XXX
 SG_ IDB_a060_RCUstatusDLC m0 : 63|1@1+ (1,0) [0|1] "" Vector__XXX
 SG_ IDB_a061_RCUstatusChecksum m1 : 4|1@1+ (1,0) [0|1] "" Vector__XXX
 SG_ IDB_a062_RCUstatusCounter m1 : 5|1@1+ (1,0) [0|1] "" Vector__XXX
 SG_ IDB_a063_RCUactuationDLC m1 : 6|1@1+ (1,0) [0|1] "" Vector__XXX
 SG_ IDB_a064_RCUactuationChecksum m1 : 7|1@1+ (1,0) [0|1] "" Vector__XXX
 SG_ IDB_a065_RCUactuationCounter m1 : 8|1@1+ (1,0) [0|1] "" Vector__XXX
 SG_ IDB_a066_DIFtorqueDLC m1 : 9|1@1+ (1,0) [0|1] "" Vector__XXX
 SG_ IDB_a067_DIFtorqueChecksum m1 : 10|1@1+ (1,0) [0|1] "" Vector__XXX
 SG_ IDB_a068_DIFtorqueCounter m1 : 11|1@1+ (1,0) [0|1] "" Vector__XXX
 SG_ IDB_a069_DIchassisControlDLC m1 : 12|1@1+ (1,0) [0|1] "" Vector__XXX
 SG_ IDB_a070_DIchassisControlChecksu m1 : 13|1@1+ (1,0) [0|1] "" Vector__XXX
 SG_ IDB_a071_DIchassisControlCounter m1 : 14|1@1+ (1,0) [0|1] "" Vector__XXX
 SG_ IDB_a072_DIsystemStatusDLC m1 : 15|1@1+ (1,0) [0|1] "" Vector__XXX
 SG_ IDB_a073_DIsystemStatusChecksum m1 : 16|1@1+ (1,0) [0|1] "" Vector__XXX
 SG_ IDB_a074_DIsystemStatusCounter m1 : 17|1@1+ (1,0) [0|1] "" Vector__XXX
 SG_ IDB_a075_DIRtorqueDLC m1 : 18|1@1+ (1,0) [0|1] "" Vector__XXX
 SG_ IDB_a076_DIRtorqueChecksum m1 : 19|1@1+ (1,0) [0|1] "" Vector__XXX
 SG_ IDB_a077_DIRtorqueCounter m1 : 20|1@1+ (1,0) [0|1] "" Vector__XXX
 SG_ IDB_a078_DIvdcLeftDLC m1 : 21|1@1+ (1,0) [0|1] "" Vector__XXX
 SG_ IDB_a079_DIvdcLeftChecksum m1 : 22|1@1+ (1,0) [0|1] "" Vector__XXX
 SG_ IDB_a080_DIvdcLeftCounter m1 : 23|1@1+ (1,0) [0|1] "" Vector__XXX
 SG_ IDB_a081_DIvdcRightDLC m1 : 24|1@1+ (1,0) [0|1] "" Vector__XXX
 SG_ IDB_a082_DIvdcRightChecksum m1 : 25|1@1+ (1,0) [0|1] "" Vector__XXX
 SG_ IDB_a083_DIvdcRightCounter m1 : 26|1@1+ (1,0) [0|1] "" Vector__XXX
 SG_ IDB_a084_EPAS3PsysStatusDLC m1 : 27|1@1+ (1,0) [0|1] "" Vector__XXX
 SG_ IDB_a085_EPAS3PsysStatusChecksum m1 : 28|1@1+ (1,0) [0|1] "" Vector__XXX
 SG_ IDB_a086_EPAS3PsysStatusCounter m1 : 29|1@1+ (1,0) [0|1] "" Vector__XXX
 SG_ IDB_a087_PMstate2DLC m1 : 30|1@1+ (1,0) [0|1] "" Vector__XXX
 SG_ IDB_a088_PMstate2Checksum m1 : 31|1@1+ (1,0) [0|1] "" Vector__XXX
 SG_ IDB_a089_PMstate2Counter m1 : 32|1@1+ (1,0) [0|1] "" Vector__XXX
 SG_ IDB_a090_RCMinertial1DLC m1 : 33|1@1+ (1,0) [0|1] "" Vector__XXX
 SG_ IDB_a091_RCMinertial1Checksum m1 : 34|1@1+ (1,0) [0|1] "" Vector__XXX
 SG_ IDB_a092_RCMinertial1Counter m1 : 35|1@1+ (1,0) [0|1] "" Vector__XXX
 SG_ IDB_a093_RCMinertial2DLC m1 : 36|1@1+ (1,0) [0|1] "" Vector__XXX
 SG_ IDB_a094_RCMinertial2Checksum m1 : 37|1@1+ (1,0) [0|1] "" Vector__XXX
 SG_ IDB_a095_RCMinertial2Counter m1 : 38|1@1+ (1,0) [0|1] "" Vector__XXX
 SG_ IDB_a096_VCFRONTLVPowerStateDLC m1 : 39|1@1+ (1,0) [0|1] "" Vector__XXX
 SG_ IDB_a097_VCFRONTLVPwrStChecksum m1 : 40|1@1+ (1,0) [0|1] "" Vector__XXX
 SG_ IDB_a098_VCFRONTLVPwrStCounter m1 : 41|1@1+ (1,0) [0|1] "" Vector__XXX
 SG_ IDB_a099_RCMcollisionDLC m1 : 42|1@1+ (1,0) [0|1] "" Vector__XXX
 SG_ IDB_a100_RCMcollisionChecksum m1 : 43|1@1+ (1,0) [0|1] "" Vector__XXX
 SG_ IDB_a101_RCMcollisionCounter m1 : 44|1@1+ (1,0) [0|1] "" Vector__XXX
 SG_ IDB_a102_bdwRequestActiveInvalid m1 : 45|1@1+ (1,0) [0|1] "" Vector__XXX
 SG_ IDB_a103_DIfullTorquePathFaulted m1 : 46|1@1+ (1,0) [0|1] "" Vector__XXX
 SG_ IDB_a104_DIaccelPosInvalid m1 : 47|1@1+ (1,0) [0|1] "" Vector__XXX
 SG_ IDB_a105_DIgearInvalid m1 : 48|1@1+ (1,0) [0|1] "" Vector__XXX
 SG_ IDB_a106_DIFtorqueInvalid m1 : 49|1@1+ (1,0) [0|1] "" Vector__XXX
 SG_ IDB_a107_DIRtorqueInvalid m1 : 50|1@1+ (1,0) [0|1] "" Vector__XXX
 SG_ IDB_a108_EPBstatusDLC m1 : 51|1@1+ (1,0) [0|1] "" Vector__XXX
 SG_ IDB_a109_BDWsignalInvalid m1 : 52|1@1+ (1,0) [0|1] "" Vector__XXX
 SG_ IDB_a110_EPBstatusCounter m1 : 53|1@1+ (1,0) [0|1] "" Vector__XXX
 SG_ IDB_a111_EPBstatusChecksum m1 : 54|1@1+ (1,0) [0|1] "" Vector__XXX
 SG_ IDB_a112_yawRateInvalid m1 : 55|1@1+ (1,0) [0|1] "" Vector__XXX
 SG_ IDB_a113_latAccelInvalid m1 : 56|1@1+ (1,0) [0|1] "" Vector__XXX
 SG_ IDB_a114_longAccelInvalid m1 : 57|1@1+ (1,0) [0|1] "" Vector__XXX
 SG_ IDB_a115_VCFRONTespLvStInvalid m1 : 58|1@1+ (1,0) [0|1] "" Vector__XXX
 SG_ IDB_a116_VCFRONTsensorsDLC m1 : 59|1@1+ (1,0) [0|1] "" Vector__XXX
 SG_ IDB_a117_VCLEFTepbmStatusDLC m1 : 60|1@1+ (1,0) [0|1] "" Vector__XXX
 SG_ IDB_a118_VCLEFTepbmStatusCounter m1 : 61|1@1+ (1,0) [0|1] "" Vector__XXX
 SG_ IDB_a119_VCLEFTepbmStatusChecksu m1 : 62|1@1+ (1,0) [0|1] "" Vector__XXX
 SG_ IDB_a120_EPAS3Pinvalid m1 : 63|1@1+ (1,0) [0|1] "" Vector__XXX
 SG_ IDB_a121_dynoModeActive m2 : 4|1@1+ (1,0) [0|1] "" Vector__XXX
 SG_ IDB_a122_DIFtorqueCommandInvalid m2 : 5|1@1+ (1,0) [0|1] "" Vector__XXX
 SG_ IDB_a123_DIRtorqueCommandInvalid m2 : 6|1@1+ (1,0) [0|1] "" Vector__XXX
 SG_ IDB_a124_VCFRONTtempInvalid m2 : 7|1@1+ (1,0) [0|1] "" Vector__XXX
 SG_ IDB_a125_PMvdcCmdStateInvalid m2 : 8|1@1+ (1,0) [0|1] "" Vector__XXX
 SG_ IDB_a126_DItorqueRequestInvalid m2 : 9|1@1+ (1,0) [0|1] "" Vector__XXX
 SG_ IDB_a127_brakeFluidLevelInvalid m2 : 10|1@1+ (1,0) [0|1] "" Vector__XXX
 SG_ IDB_a128_largeAirVolume m2 : 11|1@1+ (1,0) [0|1] "" Vector__XXX
 SG_ IDB_a129_RCUinputRodStrokeInvali m2 : 12|1@1+ (1,0) [0|1] "" Vector__XXX
 SG_ IDB_a130_DIfullTorqueRequestInva m2 : 13|1@1+ (1,0) [0|1] "" Vector__XXX
 SG_ IDB_a131_cbcFaulted m2 : 14|1@1+ (1,0) [0|1] "" Vector__XXX
 SG_ IDB_a132_RCUinputRodStrokeQFInva m2 : 15|1@1+ (1,0) [0|1] "" Vector__XXX
 SG_ IDB_a133_DIbrakeCommandDLC m2 : 16|1@1+ (1,0) [0|1] "" Vector__XXX
 SG_ IDB_a134_DIbrakeCommandCounter m2 : 17|1@1+ (1,0) [0|1] "" Vector__XXX
 SG_ IDB_a135_DIbrakeCommandChecksum m2 : 18|1@1+ (1,0) [0|1] "" Vector__XXX
 SG_ IDB_a136_RCUptsCalMissing m2 : 19|1@1+ (1,0) [0|1] "" Vector__XXX
 SG_ IDB_a137_VCLEFTcdpRequestInvalid m2 : 20|1@1+ (1,0) [0|1] "" Vector__XXX
 SG_ IDB_a138_DIbrakeTorqueCommandAnd m2 : 21|1@1+ (1,0) [0|1] "" Vector__XXX
 SG_ IDB_a139_DIbrakeTorqueCommandFul m2 : 22|1@1+ (1,0) [0|1] "" Vector__XXX
 SG_ IDB_a140_PMbrakePedalCmdQFInvali m2 : 23|1@1+ (1,0) [0|1] "" Vector__XXX
 SG_ IDB_a141_DIbrakeTorqueCommandFul m2 : 24|1@1+ (1,0) [0|1] "" Vector__XXX
 SG_ IDB_a142_PMebrCmdStateInvalid m2 : 25|1@1+ (1,0) [0|1] "" Vector__XXX
 SG_ IDB_a143_factoryModeActive m2 : 26|1@1+ (1,0) [0|1] "" Vector__XXX
 SG_ IDB_a144_hydraulicPushthroughAct m2 : 27|1@1+ (1,0) [0|1] "" Vector__XXX
 SG_ IDB_a145_DASredundantBrakingCont m2 : 28|1@1+ (1,0) [0|1] "" Vector__XXX
 SG_ IDB_a146_DASredundantBrakingCont m2 : 29|1@1+ (1,0) [0|1] "" Vector__XXX
 SG_ IDB_a147_DASredundantBrakingCont m2 : 30|1@1+ (1,0) [0|1] "" Vector__XXX
 SG_ IDB_a148_DASbrakeTorqueCommandIn m2 : 31|1@1+ (1,0) [0|1] "" Vector__XXX
 SG_ IDB_a149_DASmiaBrakeTorqueComman m2 : 32|1@1+ (1,0) [0|1] "" Vector__XXX
 SG_ IDB_a150_DIlocStatus2DLC m2 : 33|1@1+ (1,0) [0|1] "" Vector__XXX
 SG_ IDB_a151_DIlocStatus2Counter m2 : 34|1@1+ (1,0) [0|1] "" Vector__XXX
 SG_ IDB_a152_DIlocStatus2Checksum m2 : 35|1@1+ (1,0) [0|1] "" Vector__XXX
 SG_ IDB_a155_PMlocStateDLC m2 : 38|1@1+ (1,0) [0|1] "" Vector__XXX
 SG_ IDB_a156_PMlocStateChecksum m2 : 39|1@1+ (1,0) [0|1] "" Vector__XXX
 SG_ IDB_a157_PMlocStateCounter m2 : 40|1@1+ (1,0) [0|1] "" Vector__XXX

BO_ 828 IDB_info: 8 IDB
 SG_ IDB_infoIndex M : 0|8@1+ (1,0) [0|255] "" Vector__XXX
 SG_ IDB_infoPcbaID m11 : 16|8@1+ (1,0) [0|255] "" Vector__XXX
 SG_ IDB_infoAssemblyID m11 : 24|8@1+ (1,0) [0|255] "" Vector__XXX
 SG_ IDB_infoUsageID m11 : 32|16@1+ (1,0) [0|65535] "" Vector__XXX
 SG_ IDB_infoSubUsageID m11 : 48|16@1+ (1,0) [0|65535] "" Vector__XXX

BO_ 1429 OCS1P_alertLog: 8 OCS1P
 SG_ OCS1P_alertID M : 0|8@1+ (1,0) [0|255] "" Vector__XXX
 SG_ OCS1P_alertState : 15|1@1+ (1,0) [0|1] "" Vector__XXX
 SG_ OCS1P_a121_sandwichFreq m121 : 16|32@1+ (1,0) [0|4294967295] "" Vector__XXX
 SG_ OCS1P_a122_sandwichFreq m122 : 16|32@1+ (1,0) [0|4294967295] "" Vector__XXX
 SG_ OCS1P_a123_sandwichFreq m123 : 16|32@1+ (1,0) [0|4294967295] "" Vector__XXX
 SG_ OCS1P_a124_cushionSelfFreq m124 : 16|32@1+ (1,0) [0|4294967295] "" Vector__XXX
 SG_ OCS1P_a125_cushionSelfFreq m125 : 16|32@1+ (1,0) [0|4294967295] "" Vector__XXX
 SG_ OCS1P_a126_cushionSelfFreq m126 : 16|32@1+ (1,0) [0|4294967295] "" Vector__XXX
 SG_ OCS1P_a127_seatbackSelfFreq m127 : 16|32@1+ (1,0) [0|4294967295] "" Vector__XXX
 SG_ OCS1P_a128_seatbackSelfFreq m128 : 16|32@1+ (1,0) [0|4294967295] "" Vector__XXX
 SG_ OCS1P_a129_seatbackSelfFreq m129 : 16|32@1+ (1,0) [0|4294967295] "" Vector__XXX
 SG_ OCS1P_a130_sandwichNoCalib m130 : 16|1@1+ (1,0) [0|1] "" Vector__XXX
 SG_ OCS1P_a131_cushionSelfNoCalib m131 : 16|1@1+ (1,0) [0|1] "" Vector__XXX
 SG_ OCS1P_a132_seatbackSelfNoCalib m132 : 16|1@1+ (1,0) [0|1] "" Vector__XXX
 SG_ OCS1P_a133_sandwichBadCalib m133 : 16|1@1+ (1,0) [0|1] "" Vector__XXX
 SG_ OCS1P_a134_uninitializedCalib m134 : 16|1@1+ (1,0) [0|1] "" Vector__XXX
 SG_ OCS1P_a135_tempNoCalib m135 : 16|1@1+ (1,0) [0|1] "" Vector__XXX
 SG_ OCS1P_a140_tempInvalidCalib m140 : 16|1@1+ (1,0) [0|1] "" Vector__XXX
 SG_ OCS1P_a141_humidityInvalidCalib m141 : 16|1@1+ (1,0) [0|1] "" Vector__XXX
 SG_ OCS1P_a142_tempHumidityInvalid m142 : 16|1@1+ (1,0) [0|1] "" Vector__XXX
 SG_ OCS1P_a143_mismatchPassAirbag m143 : 16|1@1+ (1,0) [0|1] "" Vector__XXX
 SG_ OCS1P_a144_mismatchCarRegion m144 : 16|1@1+ (1,0) [0|1] "" Vector__XXX

BO_TX_BU_ 1384 : GTW;
BO_TX_BU_ 62 : GTW;
BO_TX_BU_ 838 : GTW;
BO_TX_BU_ 904 : GTW;
BO_TX_BU_ 792 : GTW;
BO_TX_BU_ 1080 : GTW;
BO_TX_BU_ 1376 : GTW;
BO_TX_BU_ 1656 : GTW;
BO_TX_BU_ 2033 : GTW;
BO_TX_BU_ 2026 : GTW;
BO_TX_BU_ 60 : GTW;
BO_TX_BU_ 1370 : GTW;
BO_TX_BU_ 840 : GTW;
BO_TX_BU_ 1005 : GTW;
BO_TX_BU_ 1112 : GTW;
BO_TX_BU_ 1470 : IDB;
BO_TX_BU_ 983 : IDB;
BO_TX_BU_ 828 : IDB;
BO_TX_BU_ 1429 : OCS1P;
CM_ BO_ 1384 "Gateway message: alert log";
CM_ SG_ 1384 GTW_alertID "Gateway: alert ID";
CM_ SG_ 1384 GTW_alertState "Gateway: alert state";
CM_ SG_ 1384 GTW_a014_crcVersion "Gateway: a014 crc version";
CM_ SG_ 1384 GTW_a015_crcVersion "Gateway: a015 crc version";
CM_ SG_ 1384 GTW_a016_crcVersion "Gateway: a016 crc version";
CM_ SG_ 1384 GTW_a017_crcVersion "Gateway: a017 crc version";
CM_ SG_ 1384 GTW_a018_crcVersion "Gateway: a018 crc version";
CM_ SG_ 1384 GTW_a019_crcVersion "Gateway: a019 crc version";
CM_ SG_ 1384 GTW_a020_crcVersion "Gateway: a020 crc version";
CM_ SG_ 1384 GTW_a021_crcVersion "Gateway: a021 crc version";
CM_ SG_ 1384 GTW_a022_crcVersion "Gateway: a022 crc version";
CM_ SG_ 1384 GTW_a023_crcVersion "Gateway: a023 crc version";
CM_ SG_ 1384 GTW_a024_crcVersion "Gateway: a024 crc version";
CM_ SG_ 1384 GTW_a025_crcVersion "Gateway: a025 crc version";
CM_ SG_ 1384 GTW_a026_crcVersion "Gateway: a026 crc version";
CM_ SG_ 1384 GTW_a027_crcVersion "Gateway: a027 crc version";
CM_ SG_ 1384 GTW_a028_crcVersion "Gateway: a028 crc version";
CM_ SG_ 1384 GTW_a029_crcVersion "Gateway: a029 crc version";
CM_ SG_ 1384 GTW_a030_crcVersion "Gateway: a030 crc version";
CM_ SG_ 1384 GTW_a031_crcVersion "Gateway: a031 crc version";
CM_ SG_ 1384 GTW_a032_crcVersion "Gateway: a032 crc version";
CM_ SG_ 1384 GTW_a033_crcVersion "Gateway: a033 crc version";
CM_ SG_ 1384 GTW_a034_crcVersion "Gateway: a034 crc version";
CM_ SG_ 1384 GTW_a035_crcVersion "Gateway: a035 crc version";
CM_ SG_ 1384 GTW_a036_crcVersion "Gateway: a036 crc version";
CM_ SG_ 1384 GTW_a037_crcVersion "Gateway: a037 crc version";
CM_ SG_ 1384 GTW_a038_crcVersion "Gateway: a038 crc version";
CM_ SG_ 1384 GTW_a039_crcVersion "Gateway: a039 crc version";
CM_ SG_ 1384 GTW_a040_crcVersion "Gateway: a040 crc version";
CM_ SG_ 1384 GTW_a041_crcVersion "Gateway: a041 crc version";
CM_ SG_ 1384 GTW_a042_crcVersion "Gateway: a042 crc version";
CM_ SG_ 1384 GTW_a043_crcVersion "Gateway: a043 crc version";
CM_ SG_ 1384 GTW_a045_crcVersion "Gateway: a045 crc version";
CM_ SG_ 1384 GTW_a046_crcVersion "Gateway: a046 crc version";
CM_ SG_ 1384 GTW_a047_crcVersion "Gateway: a047 crc version";
CM_ SG_ 1384 GTW_a048_crcVersion "Gateway: a048 crc version";
CM_ SG_ 1384 GTW_a049_headerError "Gateway: a049 header error";
CM_ SG_ 1384 GTW_a054_crcVersion "Gateway: a054 crc version";
CM_ SG_ 1384 GTW_a055_crcVersion "Gateway: a055 crc version";
CM_ SG_ 1384 GTW_a062_bmpWatchdogReason "Gateway: a062 bmp watchdog reason";
CM_ SG_ 1384 GTW_a063_VEH_faultConfinement "Gateway: a063 VEH fault confinement";
CM_ SG_ 1384 GTW_a064_CH_faultConfinement "Gateway: a064 CH fault confinement";
CM_ SG_ 1384 GTW_a065_PARTY_faultConfinement "Gateway: a065 PARTY fault confinement";
CM_ SG_ 1384 GTW_a066_type "Gateway: a066 type";
CM_ SG_ 1384 GTW_a066_exceptionCfgId "Gateway: a066 exception cfg id";
CM_ SG_ 1384 GTW_a066_uptime "Gateway: a066 uptime";
CM_ SG_ 1384 GTW_a066_core "Gateway: a066 core";
CM_ SG_ 1384 GTW_a068_codeKeyMissing "Gateway: a068 code key missing";
CM_ SG_ 1384 GTW_a068_cmdKeyMissing "Gateway: a068 cmd key missing";
CM_ SG_ 1384 GTW_a069_sdIntStatusErrs "Gateway: a069 sd int status errs";
CM_ SG_ 1384 GTW_a069_sdTimeout "Gateway: a069 sd timeout";
CM_ SG_ 1384 GTW_a069_sdCmdErr "Gateway: a069 sd cmd err";
CM_ SG_ 1384 GTW_a069_sdWriteErr "Gateway: a069 sd write err";
CM_ SG_ 1384 GTW_a069_sdReadErr "Gateway: a069 sd read err";
CM_ SG_ 1384 GTW_a069_autoCmd12Err "Gateway: a069 auto cmd12 err";
CM_ SG_ 1384 GTW_a072_updtFailureMask "Gateway: a072 updt failure mask";
CM_ SG_ 1384 GTW_a073_SOCResetRequestor "Gateway: a073 SOC reset requestor";
CM_ SG_ 1384 GTW_a077_bmpPmicErrorType "Gateway: a077 bmp pmic error type";
CM_ SG_ 1384 GTW_a097_crcVersion "Gateway: a097 crc version";
CM_ SG_ 1384 GTW_a098_crcVersion "Gateway: a098 crc version";
CM_ SG_ 1384 GTW_a099_crcVersion "Gateway: a099 crc version";
CM_ SG_ 1384 GTW_a100_crcVersion "Gateway: a100 crc version";
CM_ SG_ 1384 GTW_a101_switchStuck "Gateway: a101 switch stuck";
CM_ SG_ 1384 GTW_a101_ETH_SW_nINT "Gateway: a101 ETH SW n INT";
CM_ SG_ 1384 GTW_a106_crcVersion "Gateway: a106 crc version";
CM_ SG_ 1384 GTW_a107_crcVersion "Gateway: a107 crc version";
CM_ SG_ 1384 GTW_a108_crcVersion "Gateway: a108 crc version";
CM_ SG_ 1384 GTW_a117_MC_RGM_DES "Gateway: a117 MC RGM DES";
CM_ SG_ 1384 GTW_a118_MC_RGM_FES "Gateway: a118 MC RGM FES";
CM_ SG_ 1384 GTW_a122_BDY_faultConfinement "Gateway: a122 BDY fault confinement";
CM_ SG_ 1384 GTW_a129_crcVersion "Gateway: a129 crc version";
CM_ SG_ 1384 GTW_a138_sdLifetimeUsed "Gateway: a138 sd lifetime used";
CM_ SG_ 1384 GTW_a139_crcVersion "Gateway: a139 crc version";
CM_ SG_ 1384 GTW_a150_crcVersion "Gateway: a150 crc version";
CM_ SG_ 1384 GTW_a151_crcVersion "Gateway: a151 crc version";
CM_ SG_ 1384 GTW_a155_crcVersion "Gateway: a155 crc version";
CM_ SG_ 1384 GTW_a164_crcVersion "Gateway: a164 crc version";
CM_ SG_ 1384 GTW_a165_crcVersion "Gateway: a165 crc version";
CM_ SG_ 1384 GTW_a169_TPMS_pressureFL "Gateway: a169 TPMS pressure FL";
CM_ SG_ 1384 GTW_a170_TPMS_pressureFR "Gateway: a170 TPMS pressure FR";
CM_ SG_ 1384 GTW_a171_TPMS_pressureRL "Gateway: a171 TPMS pressure RL";
CM_ SG_ 1384 GTW_a172_TPMS_pressureRR "Gateway: a172 TPMS pressure RR";
CM_ SG_ 1384 GTW_a173_TPMS_pressureFL "Gateway: a173 TPMS pressure FL";
CM_ SG_ 1384 GTW_a174_TPMS_pressureFR "Gateway: a174 TPMS pressure FR";
CM_ SG_ 1384 GTW_a175_TPMS_pressureRL "Gateway: a175 TPMS pressure RL";
CM_ SG_ 1384 GTW_a176_TPMS_pressureRR "Gateway: a176 TPMS pressure RR";
CM_ SG_ 1384 GTW_a219_crcVersion "Gateway: a219 crc version";
CM_ SG_ 1384 GTW_a223_crcVersion "Gateway: a223 crc version";
CM_ SG_ 1384 GTW_a226_crcVersion "Gateway: a226 crc version";
CM_ SG_ 1384 GTW_a227_crcVersion "Gateway: a227 crc version";
CM_ SG_ 1384 GTW_a228_crcVersion "Gateway: a228 crc version";
CM_ SG_ 1384 GTW_a244_crcVersion "Gateway: a244 crc version";
CM_ SG_ 1384 GTW_a245_page0ControlValue "Gateway: a245 page0 control value";
CM_ SG_ 1384 GTW_a245_page1ControlValue "Gateway: a245 page1 control value";
CM_ SG_ 1384 GTW_a261_failureReason "Gateway: a261 failure reason";
CM_ SG_ 1384 GTW_a261_failureData1 "Gateway: a261 failure data1";
CM_ SG_ 1384 GTW_a261_failureData2 "Gateway: a261 failure data2";
CM_ SG_ 1384 GTW_a273_crcVersion "Gateway: a273 crc version";
CM_ SG_ 1384 GTW_a274_crcVersion "Gateway: a274 crc version";
CM_ SG_ 1384 GTW_a277_mitigationFailureReason "Gateway: a277 mitigation failure reason";
CM_ SG_ 1384 GTW_a279_repeatCount "Gateway: a279 repeat count";
CM_ SG_ 1384 GTW_a279_failureReason "Gateway: a279 failure reason";
CM_ SG_ 1384 GTW_a279_failureData1 "Gateway: a279 failure data1";
CM_ SG_ 1384 GTW_a279_failureData2 "Gateway: a279 failure data2";
CM_ SG_ 1384 GTW_a309_crcVersion "Gateway: a309 crc version";
CM_ SG_ 1384 GTW_a317_status "Gateway: a317 status";
CM_ SG_ 1384 GTW_a317_errorCode "Gateway: a317 error code";
CM_ SG_ 1384 GTW_a329_crcVersion "Gateway: a329 crc version";
CM_ SG_ 1384 GTW_a330_crcVersion "Gateway: a330 crc version";
CM_ SG_ 1384 GTW_a331_crcVersion "Gateway: a331 crc version";
CM_ SG_ 1384 GTW_a342_crcVersion "Gateway: a342 crc version";
CM_ SG_ 1384 GTW_a348_crcVersion "Gateway: a348 crc version";
CM_ SG_ 1384 GTW_a349_crcVersion "Gateway: a349 crc version";
CM_ SG_ 1384 GTW_a354_crcVersion "Gateway: a354 crc version";
CM_ SG_ 1384 GTW_a355_crcVersion "Gateway: a355 crc version";
CM_ SG_ 1384 GTW_a358_crcVersion "Gateway: a358 crc version";
CM_ SG_ 1384 GTW_a359_crcVersion "Gateway: a359 crc version";
CM_ SG_ 1384 GTW_a360_crcVersion "Gateway: a360 crc version";
CM_ SG_ 1384 GTW_a361_crcVersion "Gateway: a361 crc version";
CM_ SG_ 1384 GTW_a362_crcVersion "Gateway: a362 crc version";
CM_ SG_ 1384 GTW_a363_crcVersion "Gateway: a363 crc version";
CM_ SG_ 1384 GTW_a364_crcVersion "Gateway: a364 crc version";
CM_ SG_ 1384 GTW_a380_crcVersion "Gateway: a380 crc version";
CM_ SG_ 1384 GTW_a381_crcVersion "Gateway: a381 crc version";
CM_ SG_ 1384 GTW_a382_crcVersion "Gateway: a382 crc version";
CM_ SG_ 1384 GTW_a383_crcVersion "Gateway: a383 crc version";
CM_ SG_ 1384 GTW_a384_crcVersion "Gateway: a384 crc version";
CM_ SG_ 1384 GTW_a385_crcVersion "Gateway: a385 crc version";
CM_ SG_ 1384 GTW_a386_crcVersion "Gateway: a386 crc version";
CM_ SG_ 1384 GTW_a394_crcVersion "Gateway: a394 crc version";
CM_ SG_ 1384 GTW_a401_crcVersion "Gateway: a401 crc version";
CM_ SG_ 1384 GTW_a402_crcVersion "Gateway: a402 crc version";
CM_ SG_ 1384 GTW_a409_RES_CAUSE "Gateway: a409 RES CAUSE";
CM_ SG_ 1384 GTW_a410_RES_CAUSE2 "Gateway: a410 RES CAUSE2";
CM_ SG_ 1384 GTW_a418_crcVersion "Gateway: a418 crc version";
CM_ SG_ 1384 GTW_a427_crcVersion "Gateway: a427 crc version";
CM_ SG_ 1384 GTW_a428_crcVersion "Gateway: a428 crc version";
CM_ SG_ 1384 GTW_a429_crcVersion "Gateway: a429 crc version";
CM_ SG_ 1384 GTW_a439_crcVersion "Gateway: a439 crc version";
CM_ BO_ 62 "Gateway message: alert matrix";
CM_ SG_ 62 GTW_matrixIndex "Gateway: matrix index";
CM_ SG_ 62 GTW_w001_canEthTxQueue "Gateway: w001 can eth tx queue";
CM_ SG_ 62 GTW_w002_taskError "Gateway: w002 task error";
CM_ SG_ 62 GTW_w003_logWriteRecord "Gateway: w003 log write record";
CM_ SG_ 62 GTW_w004_mallocHook "Gateway: w004 malloc hook";
CM_ SG_ 62 GTW_w005_stackOverflowHook "Gateway: w005 stack overflow hook";
CM_ SG_ 62 GTW_w006_ifTxOutputFull "Gateway: w006 if tx output full";
CM_ SG_ 62 GTW_w007_ifRxBufError "Gateway: w007 if rx buf error";
CM_ SG_ 62 GTW_w008_ifPbufAllocError "Gateway: w008 if pbuf alloc error";
CM_ SG_ 62 GTW_w009_lateTask "Gateway: w009 late task";
CM_ SG_ 62 GTW_w010_wdTaskCount "Gateway: w010 wd task count";
CM_ SG_ 62 GTW_w011_cancoreWatchdog "Gateway: w011 cancore watchdog";
CM_ SG_ 62 GTW_w012_maincoreWatchdog "Gateway: w012 maincore watchdog";
CM_ SG_ 62 GTW_w014_APSversionMismatch "Gateway: w014 AP sversion mismatch";
CM_ SG_ 62 GTW_w015_DIFversionMismatch "Gateway: w015 DI fversion mismatch";
CM_ SG_ 62 GTW_w016_BLEEPCENTERversionMisma "Gateway: w016 BLEEPCENTE rversion mismatch";
CM_ SG_ 62 GTW_w017_BMSversionMismatch "Gateway: w017 BM sversion mismatch";
CM_ SG_ 62 GTW_w018_CMPversionMismatch "Gateway: w018 CM pversion mismatch";
CM_ SG_ 62 GTW_w019_CPversionMismatch "Gateway: w019 c pversion mismatch";
CM_ SG_ 62 GTW_w020_DIRversionMismatch "Gateway: w020 DI rversion mismatch";
CM_ SG_ 62 GTW_w021_EPAS3PversionMismatch "Gateway: w021 EPAS3 pversion mismatch";
CM_ SG_ 62 GTW_w022_EPBLversionMismatch "Gateway: w022 EPB lversion mismatch";
CM_ SG_ 62 GTW_w023_EPBRversionMismatch "Gateway: w023 EPB rversion mismatch";
CM_ SG_ 62 GTW_w024_ESPversionMismatch "Gateway: w024 ES pversion mismatch";
CM_ SG_ 62 GTW_w025_ESPCALversionMismatch "Gateway: w025 ESPCA lversion mismatch";
CM_ SG_ 62 GTW_w026_GTWversionMismatch "Gateway: w026 GT wversion mismatch";
CM_ SG_ 62 GTW_w027_HVPversionMismatch "Gateway: w027 HV pversion mismatch";
CM_ SG_ 62 GTW_w028_IBSTversionMismatch "Gateway: w028 IBS tversion mismatch";
CM_ SG_ 62 GTW_w029_IBSTCALversionMismatch "Gateway: w029 IBSTCA lversion mismatch";
CM_ SG_ 62 GTW_w030_OCS1PversionMismatch "Gateway: w030 OCS1 pversion mismatch";
CM_ SG_ 62 GTW_w031_PARKversionMismatch "Gateway: w031 PAR kversion mismatch";
CM_ SG_ 62 GTW_w032_PCSversionMismatch "Gateway: w032 PC sversion mismatch";
CM_ SG_ 62 GTW_w033_PCSCPU2versionMismatch "Gateway: w033 pcscpu2version mismatch";
CM_ SG_ 62 GTW_w034_PMRversionMismatch "Gateway: w034 PM rversion mismatch";
CM_ SG_ 62 GTW_w035_PMFversionMismatch "Gateway: w035 PM fversion mismatch";
CM_ SG_ 62 GTW_w036_PTCversionMismatch "Gateway: w036 PT cversion mismatch";
CM_ SG_ 62 GTW_w037_RADCversionMismatch "Gateway: w037 RAD cversion mismatch";
CM_ SG_ 62 GTW_w038_RCMversionMismatch "Gateway: w038 RC mversion mismatch";
CM_ SG_ 62 GTW_w039_RCMCALversionMismatch "Gateway: w039 RCMCA lversion mismatch";
CM_ SG_ 62 GTW_w040_SCCMversionMismatch "Gateway: w040 SCC mversion mismatch";
CM_ SG_ 62 GTW_w041_VCSECversionMismatch "Gateway: w041 VCSE cversion mismatch";
CM_ SG_ 62 GTW_w042_TASversionMismatch "Gateway: w042 TA sversion mismatch";
CM_ SG_ 62 GTW_w043_THSversionMismatch "Gateway: w043 TH sversion mismatch";
CM_ SG_ 62 GTW_w045_VCFRONTversionMismatch "Gateway: w045 VCFRON tversion mismatch";
CM_ SG_ 62 GTW_w046_VCLEFTversionMismatch "Gateway: w046 VCLEF tversion mismatch";
CM_ SG_ 62 GTW_w047_VCRIGHTversionMismatch "Gateway: w047 VCRIGH tversion mismatch";
CM_ SG_ 62 GTW_w048_EPAS3SversionMismatch "Gateway: w048 EPAS3 sversion mismatch";
CM_ SG_ 62 GTW_w049_corruptedManifest "Gateway: w049 corrupted manifest";
CM_ SG_ 62 GTW_w050_sdCardInitFailure "Gateway: w050 sd card init failure";
CM_ SG_ 62 GTW_w051_sdCardFileSystemFailure "Gateway: w051 sd card file system failure";
CM_ SG_ 62 GTW_w052_ifTxSpans "Gateway: w052 if tx spans";
CM_ SG_ 62 GTW_w053_busSleepFailure "Gateway: w053 bus sleep failure";
CM_ SG_ 62 GTW_w054_OPCRversionMismatch "Gateway: w054 OPC rversion mismatch";
CM_ SG_ 62 GTW_w055_OPCFversionMismatch "Gateway: w055 OPC fversion mismatch";
CM_ SG_ 62 GTW_w057_i2cFailure "Gateway: w057 i2c failure";
CM_ SG_ 62 GTW_w058_rtcAlarmFailure "Gateway: w058 rtc alarm failure";
CM_ SG_ 62 GTW_w059_inFactoryMode "Gateway: w059 in factory mode";
CM_ SG_ 62 GTW_w060_unFused "Gateway: w060 un fused";
CM_ SG_ 62 GTW_w061_bmpSleepFailure "Gateway: w061 bmp sleep failure";
CM_ SG_ 62 GTW_w062_bmpWatchdog "Gateway: w062 bmp watchdog";
CM_ SG_ 62 GTW_w063_VEH_canFault "Gateway: w063 VEH can fault";
CM_ SG_ 62 GTW_w064_CH_canFault "Gateway: w064 CH can fault";
CM_ SG_ 62 GTW_w065_PARTY_canFault "Gateway: w065 PARTY can fault";
CM_ SG_ 62 GTW_w066_exception "Gateway: w066 exception";
CM_ SG_ 62 GTW_w067_tcpDebug "Gateway: w067 tcp debug";
CM_ SG_ 62 GTW_w068_prodKeyMissing "Gateway: w068 prod key missing";
CM_ SG_ 62 GTW_w069_diskioErr "Gateway: w069 diskio err";
CM_ SG_ 62 GTW_w070_hrlDump "Gateway: w070 hrl dump";
CM_ SG_ 62 GTW_w071_hrlTrigger "Gateway: w071 hrl trigger";
CM_ SG_ 62 GTW_w072_updateFailure "Gateway: w072 update failure";
CM_ SG_ 62 GTW_w073_steeringWheelReset "Gateway: w073 steering wheel reset";
CM_ SG_ 62 GTW_w074_epas3pMIA "Gateway: w074 epas3p MIA";
CM_ SG_ 62 GTW_w075_epas3sMIA "Gateway: w075 epas3s MIA";
CM_ SG_ 62 GTW_w076_ethInterfaceReset "Gateway: w076 eth interface reset";
CM_ SG_ 62 GTW_w077_bmpPmicError "Gateway: w077 bmp pmic error";
CM_ SG_ 62 GTW_w078_VEHbusOverloaded "Gateway: w078 VE hbus overloaded";
CM_ SG_ 62 GTW_w079_PARTYbusOverloaded "Gateway: w079 PART ybus overloaded";
CM_ SG_ 62 GTW_w080_CHbusOverloaded "Gateway: w080 c hbus overloaded";
CM_ SG_ 62 GTW_w081_udsMessageRejected "Gateway: w081 uds message rejected";
CM_ SG_ 62 GTW_w082_sdCardBSCorrupted "Gateway: w082 sd card BS corrupted";
CM_ SG_ 62 GTW_w083_udsMsgDroppedByTcpStack "Gateway: w083 uds msg dropped by tcp stack";
CM_ SG_ 62 GTW_w084_canFrameDropped "Gateway: w084 can frame dropped";
CM_ SG_ 62 GTW_w085_fuseStateUnknown "Gateway: w085 fuse state unknown";
CM_ SG_ 62 GTW_w086_ocu "Gateway: w086 ocu";
CM_ SG_ 62 GTW_w087_ocuInProgress "Gateway: w087 ocu in progress";
CM_ SG_ 62 GTW_w088_sdCardInvReqParallel "Gateway: w088 sd card inv req parallel";
CM_ SG_ 62 GTW_w089_sdCardWatchdog "Gateway: w089 sd card watchdog";
CM_ SG_ 62 GTW_w090_ocuFailed "Gateway: w090 ocu failed";
CM_ SG_ 62 GTW_w091_lowStack "Gateway: w091 low stack";
CM_ SG_ 62 GTW_w092_sdCardInvReqZero "Gateway: w092 sd card inv req zero";
CM_ SG_ 62 GTW_w093_sdCardInvReqOverflowBas "Gateway: w093 sd card inv req overflow base";
CM_ SG_ 62 GTW_w094_sdCardInvReqOverflowCou "Gateway: w094 sd card inv req overflow count";
CM_ SG_ 62 GTW_w095_sdCardFull "Gateway: w095 sd card full";
CM_ SG_ 62 GTW_w096_sdCardFatCorrupted "Gateway: w096 sd card fat corrupted";
CM_ SG_ 62 GTW_w097_HCMLversionMismatch "Gateway: w097 HCM lversion mismatch";
CM_ SG_ 62 GTW_w098_HCMRversionMismatch "Gateway: w098 HCM rversion mismatch";
CM_ SG_ 62 GTW_w099_SWCversionMismatch "Gateway: w099 SW cversion mismatch";
CM_ SG_ 62 GTW_w100_CBCversionMismatch "Gateway: w100 CB cversion mismatch";
CM_ SG_ 62 GTW_w101_switchWatchdog "Gateway: w101 switch watchdog";
CM_ SG_ 62 GTW_w103_sdCardFormatted "Gateway: w103 sd card formatted";
CM_ SG_ 62 GTW_w104_sdCardDriverArgCorrupte "Gateway: w104 sd card driver arg corrupted";
CM_ SG_ 62 GTW_w105_eBuckConfigured "Gateway: w105 e buck configured";
CM_ SG_ 62 GTW_w106_BLEEPLEFTversionMismatc "Gateway: w106 BLEEPLEF tversion mismatch";
CM_ SG_ 62 GTW_w107_BLEEPRIGHTversionMismat "Gateway: w107 BLEEPRIGH tversion mismatch";
CM_ SG_ 62 GTW_w108_BLEEPREARversionMismatc "Gateway: w108 BLEEPREA rversion mismatch";
CM_ SG_ 62 GTW_w109_failedToStartUpdater "Gateway: w109 failed to start updater";
CM_ SG_ 62 GTW_w110_readMdioFailed "Gateway: w110 read mdio failed";
CM_ SG_ 62 GTW_w111_writeMdioFailed "Gateway: w111 write mdio failed";
CM_ SG_ 62 GTW_w112_z4bDisabled "Gateway: w112 z4b disabled";
CM_ SG_ 62 GTW_w113_unrecognizedCanMessage "Gateway: w113 unrecognized can message";
CM_ SG_ 62 GTW_w114_updtRetried "Gateway: w114 updt retried";
CM_ SG_ 62 GTW_w115_hrlEventFileAvail "Gateway: w115 hrl event file avail";
CM_ SG_ 62 GTW_w116_switchInitFailed "Gateway: w116 switch init failed";
CM_ SG_ 62 GTW_w117_unexpectedDestructiveRe "Gateway: w117 unexpected destructive reset status";
CM_ SG_ 62 GTW_w118_unexpectedFunctionalRes "Gateway: w118 unexpected functional reset status";
CM_ SG_ 62 GTW_w120_switchUnlocked "Gateway: w120 switch unlocked";
CM_ SG_ 62 GTW_w122_BDY_canFault "Gateway: w122 BDY can fault";
CM_ SG_ 62 GTW_w123_BDYbusOverloaded "Gateway: w123 BD ybus overloaded";
CM_ SG_ 62 GTW_w125_switchReplayUnlocked "Gateway: w125 switch replay unlocked";
CM_ SG_ 62 GTW_w127_noFilePointersAvailable "Gateway: w127 no file pointers available";
CM_ SG_ 62 GTW_w129_ICRversionMismatch "Gateway: w129 IC rversion mismatch";
CM_ SG_ 62 GTW_w133_adspFaultDetected "Gateway: w133 adsp fault detected";
CM_ SG_ 62 GTW_w134_disableFeatureFailed "Gateway: w134 disable feature failed";
CM_ SG_ 62 GTW_w135_canLogQueueFull "Gateway: w135 can log queue full";
CM_ SG_ 62 GTW_w136_hrlGameModeFileAvail "Gateway: w136 hrl game mode file avail";
CM_ SG_ 62 GTW_w137_lowHeap "Gateway: w137 low heap";
CM_ SG_ 62 GTW_w138_sdCardEndOfLife "Gateway: w138 sd card end of life";
CM_ SG_ 62 GTW_w139_CMPDversionMismatch "Gateway: w139 CMP dversion mismatch";
CM_ SG_ 62 GTW_w140_cancoreHeartbeat "Gateway: w140 cancore heartbeat";
CM_ SG_ 62 GTW_w141_teleCANETHis "Gateway: w141 tele CANET his";
CM_ SG_ 62 GTW_w143_possibleCanWakeIssue "Gateway: w143 possible can wake issue";
CM_ SG_ 62 GTW_w144_hrlStateMachine "Gateway: w144 hrl state machine";
CM_ SG_ 62 GTW_w145_carConfigsNotWritten "Gateway: w145 car configs not written";
CM_ SG_ 62 GTW_w146_performancePackageMisma "Gateway: w146 performance package mismatch";
CM_ SG_ 62 GTW_w147_updateAbortFor12v "Gateway: w147 update abort for12v";
CM_ SG_ 62 GTW_w149_rtcTimeSetInPast "Gateway: w149 rtc time set in past";
CM_ SG_ 62 GTW_w150_HCM3LversionMismatch "Gateway: w150 HCM3 lversion mismatch";
CM_ SG_ 62 GTW_w151_HCM3RversionMismatch "Gateway: w151 HCM3 rversion mismatch";
CM_ SG_ 62 GTW_w153_externalRtcAlarmFailure "Gateway: w153 external rtc alarm failure";
CM_ SG_ 62 GTW_w155_PMversionMismatch "Gateway: w155 p mversion mismatch";
CM_ SG_ 62 GTW_w164_VCBATTversionMismatch "Gateway: w164 VCBAT tversion mismatch";
CM_ SG_ 62 GTW_w165_USMversionMismatch "Gateway: w165 US mversion mismatch";
CM_ SG_ 62 GTW_w166_nErrCanFaultVeh "Gateway: w166 n err can fault veh";
CM_ SG_ 62 GTW_w167_nErrCanFaultCh "Gateway: w167 n err can fault ch";
CM_ SG_ 62 GTW_w168_nErrCanFaultParty "Gateway: w168 n err can fault party";
CM_ SG_ 62 GTW_w169_TPMSsoftWarnFrontLeft "Gateway: w169 TPM ssoft warn front left";
CM_ SG_ 62 GTW_w170_TPMSsoftWarnFrontRight "Gateway: w170 TPM ssoft warn front right";
CM_ SG_ 62 GTW_w171_TPMSsoftWarnRearLeft "Gateway: w171 TPM ssoft warn rear left";
CM_ SG_ 62 GTW_w172_TPMSsoftWarnRearRight "Gateway: w172 TPM ssoft warn rear right";
CM_ SG_ 62 GTW_w173_TPMShardWarnFrontLeft "Gateway: w173 TPM shard warn front left";
CM_ SG_ 62 GTW_w174_TPMShardWarnFrontRight "Gateway: w174 TPM shard warn front right";
CM_ SG_ 62 GTW_w175_TPMShardWarnRearLeft "Gateway: w175 TPM shard warn rear left";
CM_ SG_ 62 GTW_w176_TPMShardWarnRearRight "Gateway: w176 TPM shard warn rear right";
CM_ SG_ 62 GTW_w186_swrPrecaution "Gateway: w186 swr precaution";
CM_ SG_ 62 GTW_w218_switchOTPIncorrect "Gateway: w218 switch OTP incorrect";
CM_ SG_ 62 GTW_w219_CMPSversionMismatch "Gateway: w219 CMP sversion mismatch";
CM_ SG_ 62 GTW_w223_LVBMSversionMismatch "Gateway: w223 LVBM sversion mismatch";
CM_ SG_ 62 GTW_w224_sdCardUpgradeNeeded "Gateway: w224 sd card upgrade needed";
CM_ SG_ 62 GTW_w225_resetOnSleepWake "Gateway: w225 reset on sleep wake";
CM_ SG_ 62 GTW_w226_DISPversionMismatch "Gateway: w226 DIS pversion mismatch";
CM_ SG_ 62 GTW_w227_DISPTOUCHversionMismatc "Gateway: w227 DISPTOUC hversion mismatch";
CM_ SG_ 62 GTW_w228_DISPOSDversionMismatch "Gateway: w228 DISPOS dversion mismatch";
CM_ SG_ 62 GTW_w229_displaySoftsetConnectio "Gateway: w229 display softset connection";
CM_ SG_ 62 GTW_w230_touchInterruptStorm "Gateway: w230 touch interrupt storm";
CM_ SG_ 62 GTW_w244_SDCRversionMismatch "Gateway: w244 SDC rversion mismatch";
CM_ SG_ 62 GTW_w245_apsNotDisabled "Gateway: w245 aps not disabled";
CM_ SG_ 62 GTW_w246_touchcoreHeartbeat "Gateway: w246 touchcore heartbeat";
CM_ SG_ 62 GTW_w255_rtc32KHzWatchdog "Gateway: w255 rtc32 k hz watchdog";
CM_ SG_ 62 GTW_w260_unknownPN "Gateway: w260 unknown PN";
CM_ SG_ 62 GTW_w261_adspWatchdog "Gateway: w261 adsp watchdog";
CM_ SG_ 62 GTW_w262_canLogBlockDropped "Gateway: w262 can log block dropped";
CM_ SG_ 62 GTW_w263_hrlUdpFileAvail "Gateway: w263 hrl udp file avail";
CM_ SG_ 62 GTW_w264_hrlPseudoFileAvail "Gateway: w264 hrl pseudo file avail";
CM_ SG_ 62 GTW_w265_optionFlagsError "Gateway: w265 option flags error";
CM_ SG_ 62 GTW_w266_dpp1MIA "Gateway: w266 dpp1 MIA";
CM_ SG_ 62 GTW_w267_dpp2MIA "Gateway: w267 dpp2 MIA";
CM_ SG_ 62 GTW_w268_stoMIA "Gateway: w268 sto MIA";
CM_ SG_ 62 GTW_w273_BLEEPREARLEFTversionMis "Gateway: w273 BLEEPREARLEF tversion mismatch";
CM_ SG_ 62 GTW_w274_BLEEPREARRIGHTversionMi "Gateway: w274 BLEEPREARRIGH tversion mismatch";
CM_ SG_ 62 GTW_w275_VDDCORE_DrMOS_Fault "Gateway: w275 VDDCORE dr MOS fault";
CM_ SG_ 62 GTW_w276_VDDSOC_DrMOS_Fault "Gateway: w276 VDDSOC dr MOS fault";
CM_ SG_ 62 GTW_w277_NonRevCDrMOSMitigationF "Gateway: w277 non rev c dr MOS mitigation failed";
CM_ SG_ 62 GTW_w278_ethSwitchCongested "Gateway: w278 eth switch congested";
CM_ SG_ 62 GTW_w279_adspRepeatedWatchdog "Gateway: w279 adsp repeated watchdog";
CM_ SG_ 62 GTW_w280_hrlFrameDropped "Gateway: w280 hrl frame dropped";
CM_ SG_ 62 GTW_w281_likelyMissedPoke "Gateway: w281 likely missed poke";
CM_ SG_ 62 GTW_w282_tcuPhyConfigurationFail "Gateway: w282 tcu phy configuration failed";
CM_ SG_ 62 GTW_w309_VCUSBversionMismatch "Gateway: w309 VCUS bversion mismatch";
CM_ SG_ 62 GTW_w311_canLogQueueFullBeforeFs "Gateway: w311 can log queue full before fs init";
CM_ SG_ 62 GTW_w312_hrlFileIncomplete "Gateway: w312 hrl file incomplete";
CM_ SG_ 62 GTW_w313_OSDActive "Gateway: w313 OSD active";
CM_ SG_ 62 GTW_w314_canLogBlockWriteErr "Gateway: w314 can log block write err";
CM_ SG_ 62 GTW_w316_sdCardChkdskRepair "Gateway: w316 sd card chkdsk repair";
CM_ SG_ 62 GTW_w317_sdCardChkdskRepairFaile "Gateway: w317 sd card chkdsk repair failed";
CM_ SG_ 62 GTW_w322_gestureUnrecognizedFrom "Gateway: w322 gesture unrecognized from moving";
CM_ SG_ 62 GTW_w323_gestureStartOutOfStrip "Gateway: w323 gesture start out of strip";
CM_ SG_ 62 GTW_w328_smartShiftDisabled "Gateway: w328 smart shift disabled";
CM_ SG_ 62 GTW_w329_FOHMversionMismatch "Gateway: w329 FOH mversion mismatch";
CM_ SG_ 62 GTW_w330_SWSLversionMismatch "Gateway: w330 SWS lversion mismatch";
CM_ SG_ 62 GTW_w331_SWSRversionMismatch "Gateway: w331 SWS rversion mismatch";
CM_ SG_ 62 GTW_w332_unknownDisplayPN "Gateway: w332 unknown display PN";
CM_ SG_ 62 GTW_w334_hrlFolderSpaceLow "Gateway: w334 hrl folder space low";
CM_ SG_ 62 GTW_w336_possibleCanTxIssue "Gateway: w336 possible can tx issue";
CM_ SG_ 62 GTW_w342_VCBLDCPPversionMismatch "Gateway: w342 VCBLDCP pversion mismatch";
CM_ SG_ 62 GTW_w348_VCBLDCFversionMismatch "Gateway: w348 VCBLDC fversion mismatch";
CM_ SG_ 62 GTW_w349_VCBLDCPBversionMismatch "Gateway: w349 VCBLDCP bversion mismatch";
CM_ SG_ 62 GTW_w350_mOSDCrcCheck "Gateway: w350 m OSD crc check";
CM_ SG_ 62 GTW_w351_sOSDCrcCheck "Gateway: w351 s OSD crc check";
CM_ SG_ 62 GTW_w352_mASILStatusCheck "Gateway: w352 m ASIL status check";
CM_ SG_ 62 GTW_w353_sASILStatusCheck "Gateway: w353 s ASIL status check";
CM_ SG_ 62 GTW_w354_EPASTPversionMismatch "Gateway: w354 EPAST pversion mismatch";
CM_ SG_ 62 GTW_w355_EPASTSversionMismatch "Gateway: w355 EPAST sversion mismatch";
CM_ SG_ 62 GTW_w356_touchGPIOStatusCheck "Gateway: w356 touch GPIO status check";
CM_ SG_ 62 GTW_w358_RGBIPFLversionMismatch "Gateway: w358 RGBIPF lversion mismatch";
CM_ SG_ 62 GTW_w359_RGBIPFRversionMismatch "Gateway: w359 RGBIPF rversion mismatch";
CM_ SG_ 62 GTW_w360_RGBDOORFLversionMismatc "Gateway: w360 RGBDOORF lversion mismatch";
CM_ SG_ 62 GTW_w361_RGBDOORRLversionMismatc "Gateway: w361 RGBDOORR lversion mismatch";
CM_ SG_ 62 GTW_w362_RGBDOORFRversionMismatc "Gateway: w362 RGBDOORF rversion mismatch";
CM_ SG_ 62 GTW_w363_RGBDOORRRversionMismatc "Gateway: w363 RGBDOORR rversion mismatch";
CM_ SG_ 62 GTW_w364_BLEEPCRADLEversionMisma "Gateway: w364 BLEEPCRADL eversion mismatch";
CM_ SG_ 62 GTW_w366_uiGearRequestMismatch "Gateway: w366 ui gear request mismatch";
CM_ SG_ 62 GTW_w376_blFailedToExecBootImg "Gateway: w376 bl failed to exec boot img";
CM_ SG_ 62 GTW_w380_DPBversionMismatch "Gateway: w380 DP bversion mismatch";
CM_ SG_ 62 GTW_w381_DPBCALversionMismatch "Gateway: w381 DPBCA lversion mismatch";
CM_ SG_ 62 GTW_w382_IDBversionMismatch "Gateway: w382 ID bversion mismatch";
CM_ SG_ 62 GTW_w383_IDB1versionMismatch "Gateway: w383 idb1version mismatch";
CM_ SG_ 62 GTW_w384_IDBCALversionMismatch "Gateway: w384 IDBCA lversion mismatch";
CM_ SG_ 62 GTW_w385_RCUversionMismatch "Gateway: w385 RC uversion mismatch";
CM_ SG_ 62 GTW_w386_RCUCALversionMismatch "Gateway: w386 RCUCA lversion mismatch";
CM_ SG_ 62 GTW_w387_externalRtcReadFailure "Gateway: w387 external rtc read failure";
CM_ SG_ 62 GTW_w388_adspWatchdogSkipped "Gateway: w388 adsp watchdog skipped";
CM_ SG_ 62 GTW_w389_rcmEventDetected "Gateway: w389 rcm event detected";
CM_ SG_ 62 GTW_w390_displayFwQueryFailed "Gateway: w390 display fw query failed";
CM_ SG_ 62 GTW_w391_adspMacAddrCheckFailed "Gateway: w391 adsp mac addr check failed";
CM_ SG_ 62 GTW_w393_osdSramCrcMismatch "Gateway: w393 osd sram crc mismatch";
CM_ SG_ 62 GTW_w394_WIPERversionMismatch "Gateway: w394 WIPE rversion mismatch";
CM_ SG_ 62 GTW_w395_lwipIcmpError "Gateway: w395 lwip icmp error";
CM_ SG_ 62 GTW_w396_alreadyInReverse "Gateway: w396 already in reverse";
CM_ SG_ 62 GTW_w397_alreadyInDrive "Gateway: w397 already in drive";
CM_ SG_ 62 GTW_w398_awakeForExtendedTime "Gateway: w398 awake for extended time";
CM_ SG_ 62 GTW_w399_ethIfRxTcpipQueueDrop "Gateway: w399 eth if rx tcpip queue drop";
CM_ SG_ 62 GTW_w400_ethlSwitchOTPIncorrect "Gateway: w400 ethl switch OTP incorrect";
CM_ SG_ 62 GTW_w401_VCSEAT2LversionMismatch "Gateway: w401 VCSEAT2 lversion mismatch";
CM_ SG_ 62 GTW_w402_VCSEAT2RversionMismatch "Gateway: w402 VCSEAT2 rversion mismatch";
CM_ SG_ 62 GTW_w409_unexpectedResetCause "Gateway: w409 unexpected reset cause";
CM_ SG_ 62 GTW_w410_unexpectedResetCause2 "Gateway: w410 unexpected reset cause2";
CM_ SG_ 62 GTW_w411_tASILStatusCheck "Gateway: w411 t ASIL status check";
CM_ SG_ 62 GTW_w414_socHeldInReset "Gateway: w414 soc held in reset";
CM_ SG_ 62 GTW_w418_TRCMversionMismatch "Gateway: w418 TRC mversion mismatch";
CM_ SG_ 62 GTW_w420_unexpectedCanMessageLen "Gateway: w420 unexpected can message length";
CM_ SG_ 62 GTW_w421_ModemEthLinkDown "Gateway: w421 modem eth link down";
CM_ SG_ 62 GTW_w422_ethSwitchSevereCongesti "Gateway: w422 eth switch severe congestion watchdog";
CM_ SG_ 62 GTW_w427_DISPBRIDGEversionMismat "Gateway: w427 DISPBRIDG eversion mismatch";
CM_ SG_ 62 GTW_w428_LUMBAR32LversionMismatc "Gateway: w428 LUMBAR32 lversion mismatch";
CM_ SG_ 62 GTW_w429_LUMBAR32RversionMismatc "Gateway: w429 LUMBAR32 rversion mismatch";
CM_ SG_ 62 GTW_w436_possibleCanRxIssue "Gateway: w436 possible can rx issue";
CM_ SG_ 62 GTW_w437_softFlowControlNotRunni "Gateway: w437 soft flow control not running";
CM_ SG_ 62 GTW_w438_wakeSourceUnknown "Gateway: w438 wake source unknown";
CM_ SG_ 62 GTW_w439_VCCCversionMismatch "Gateway: w439 VCC cversion mismatch";
CM_ SG_ 62 GTW_w450_unexpectedAutopilotCont "Gateway: w450 unexpected autopilot control can message";
CM_ SG_ 62 GTW_w451_diagCanBufferExhausted "Gateway: w451 diag can buffer exhausted";
CM_ SG_ 62 GTW_w452_diagCanStaleSocket "Gateway: w452 diag can stale socket";
CM_ SG_ 62 GTW_w453_diagCanFdSetDesync "Gateway: w453 diag can fd set desync";
CM_ SG_ 62 GTW_w454_diagCanFrameOverread "Gateway: w454 diag can frame overread";
CM_ SG_ 62 GTW_w455_hrlDumpPageOwnershipErr "Gateway: w455 hrl dump page ownership error";
CM_ SG_ 62 GTW_w456_hrlStateMachinePageOwne "Gateway: w456 hrl state machine page ownership error";
CM_ SG_ 62 GTW_w463_displayEdidReadFailed "Gateway: w463 display edid read failed";
CM_ SG_ 62 GTW_w469_backlightFsmUnhealthy "Gateway: w469 backlight fsm unhealthy";
CM_ BO_ 838 "Gateway message: autopilot override";
CM_ SG_ 838 GTW_autopilotOverrideState "Signals whether an autopilot trial or subscription is active";
CM_ SG_ 838 GTW_autopilotConfig "Current level of permanent Autopilot firmware";
CM_ SG_ 838 GTW_autopilotOverrideConfig "Current level of trial or subscription Autopilot firmware";
CM_ SG_ 838 GTW_autopilotConfigSource "Source of Autopilot configuration broadcast by Gateway";
CM_ SG_ 838 GTW_autopilotOverrideExpireTime "Expiration time for the currently active autopilot trial or subscription";
CM_ BO_ 904 "Gateway message: can status";
CM_ SG_ 904 GTW_VEH_canBusActivity "Active if any frame detected on the bus";
CM_ SG_ 904 GTW_PARTY_canBusActivity "Active if any frame detected on the bus";
CM_ SG_ 904 GTW_CH_canBusActivity "Active if any frame detected on the bus";
CM_ SG_ 904 GTW_VEH_txWarning "Gateway: VEH tx warning";
CM_ SG_ 904 GTW_PARTY_txWarning "Gateway: PARTY tx warning";
CM_ SG_ 904 GTW_CH_txWarning "Gateway: CH tx warning";
CM_ SG_ 904 GTW_VEH_rxWarning "Gateway: VEH rx warning";
CM_ SG_ 904 GTW_PARTY_rxWarning "Gateway: PARTY rx warning";
CM_ SG_ 904 GTW_CH_rxWarning "Gateway: CH rx warning";
CM_ SG_ 904 GTW_VEH_faultConfinement "Fault confinement as per CAN spec";
CM_ SG_ 904 GTW_PARTY_faultConfinement "Fault confinement as per CAN spec";
CM_ SG_ 904 GTW_CH_faultConfinement "Fault confinement as per CAN spec";
CM_ SG_ 904 GTW_BDY_canBusActivity "Active if any frame detected on the bus";
CM_ SG_ 904 GTW_BDY_txWarning "Gateway: BDY tx warning";
CM_ SG_ 904 GTW_BDY_rxWarning "Gateway: BDY rx warning";
CM_ SG_ 904 GTW_BDY_faultConfinement "Fault confinement as per CAN spec";
CM_ BO_ 792 "Gateway message: car state";
CM_ SG_ 792 GTW_factoryGated "Gateway: factory gated";
CM_ BO_ 1080 "Gateway message: eth nm";
CM_ SG_ 1080 GTW_ethGotoSleep "ETH bus sleep commanded";
CM_ SG_ 1080 GTW_ethWakeUpBus "Gateway: eth wake up bus";
CM_ SG_ 1080 GTW_vehBusAsleep "VEH bus sleep state";
CM_ SG_ 1080 GTW_ethHeartBeatCounter "Gateway: eth heart beat counter";
CM_ SG_ 1080 GTW_ethWakeUpReason "Tracks the cause of why the gateway wakes up the ethernet bus";
CM_ BO_ 1376 "Gateway message: factory ecu present";
CM_ SG_ 1376 GTW_OCS1Ppresent "Gateway: OCS1 ppresent";
CM_ SG_ 1376 GTW_PCSpresent "Gateway: PC spresent";
CM_ SG_ 1376 GTW_HVPpresent "Gateway: HV ppresent";
CM_ SG_ 1376 GTW_BMSpresent "Gateway: BM spresent";
CM_ SG_ 1376 GTW_CPpresent "Gateway: c ppresent";
CM_ SG_ 1376 GTW_RCMpresent "Gateway: RC mpresent";
CM_ SG_ 1376 GTW_SCCMpresent "Gateway: SCC mpresent";
CM_ SG_ 1376 GTW_VCSECpresent "Gateway: VCSE cpresent";
CM_ SG_ 1376 GTW_EPAS3Ppresent "Gateway: EPAS3 ppresent";
CM_ SG_ 1376 GTW_EPBLpresent "Gateway: EPB lpresent";
CM_ SG_ 1376 GTW_EPBRpresent "Gateway: EPB rpresent";
CM_ SG_ 1376 GTW_ESPpresent "Gateway: ES ppresent";
CM_ SG_ 1376 GTW_IBSTpresent "Gateway: IBS tpresent";
CM_ SG_ 1376 GTW_PARKpresent "Gateway: PAR kpresent";
CM_ SG_ 1376 GTW_RADCpresent "Gateway: RAD cpresent";
CM_ SG_ 1376 GTW_TPMSpresent "Gateway: TPM spresent";
CM_ SG_ 1376 GTW_VCFRONTpresent "Gateway: VCFRON tpresent";
CM_ SG_ 1376 GTW_VCLEFTpresent "Gateway: VCLEF tpresent";
CM_ SG_ 1376 GTW_VCRIGHTpresent "Gateway: VCRIGH tpresent";
CM_ SG_ 1376 GTW_EPAS3Spresent "Gateway: EPAS3 spresent";
CM_ SG_ 1376 GTW_CMPpresent "Gateway: CM ppresent";
CM_ SG_ 1376 GTW_DASpresent "Gateway: DA spresent";
CM_ SG_ 1376 GTW_PTCpresent "Gateway: PT cpresent";
CM_ SG_ 1376 GTW_SWCpresent "Gateway: SW cpresent";
CM_ SG_ 1376 GTW_PMRpresent "Gateway: PM rpresent";
CM_ SG_ 1376 GTW_PMFpresent "Gateway: PM fpresent";
CM_ SG_ 1376 GTW_DIRpresent "Gateway: DI rpresent";
CM_ SG_ 1376 GTW_DIFpresent "Gateway: DI fpresent";
CM_ BO_ 1656 "Gateway message: gear control";
CM_ SG_ 1656 GTW_gearControlChecksum "Gateway: gear control checksum";
CM_ SG_ 1656 GTW_gearControlCounter "Gateway: gear control counter";
CM_ SG_ 1656 GTW_gearShiftRequest "Request to change gear state from center display UI control; raw 0 = signal not available (SNA)";
CM_ SG_ 1656 GTW_osdActive "Whether OSD is active";
CM_ SG_ 1656 GTW_primaryGearControlStatus "Status of the center display UI control";
CM_ SG_ 1656 GTW_gearStripEnable "UI control for showing and or activating the primary gear strip interface";
CM_ SG_ 1656 GTW_showNeutralButton "Tell UI that it is time to animate the N button to be shown";
CM_ SG_ 1656 GTW_showAutoParkButton "Tell UI that it is time to animate the autopark button to be shown";
CM_ SG_ 1656 GTW_autoParkRequest "Request to auto park from center display UI control";
CM_ SG_ 1656 GTW_smartShiftStatus "Based on the status of the infotainment system smart shift feature should be disabled; raw 0 = signal not available (SNA)";
CM_ SG_ 1656 GTW_processingRDgestures "Is GTW processing R and D swipe gestures";
CM_ SG_ 1656 GTW_processingTapPgestures "Is GTW processing contextual tap-to-park gestures";
CM_ SG_ 1656 GTW_gearStripChangeReason "Gateway: gear strip change reason; raw 0 = signal not available (SNA)";
CM_ SG_ 1656 GTW_touchActive "User present as touch on display is active";
CM_ SG_ 1656 GTW_steamOff "Let UI know to turn Steam off";
CM_ SG_ 1656 GTW_screenPCBTemperature "Reading from display i2c temperature sensor; raw 2047 = signal not available (SNA)";
CM_ BO_ 2033 "Gateway message: hrl";
CM_ SG_ 2033 GTW_hrlIndex "Gateway: hrl index";
CM_ SG_ 2033 GTW_hrlPagesCount "Gateway: hrl pages count";
CM_ SG_ 2033 GTW_hrlSdCardSizeGB "Gateway: hrl sd card size GB; raw 0 = signal not available (SNA)";
CM_ SG_ 2033 GTW_hrlState "GTW hrl state";
CM_ SG_ 2033 GTW_hrlTriggerDuration "HRL duration";
CM_ SG_ 2033 GTW_hrlTriggerType "HRL trigger type";
CM_ SG_ 2033 GTW_hrlTriggerId "HRL trigger ID. A unique ID representing the signal conditions causing the HRL event to occur.";
CM_ SG_ 2033 GTW_hrlTriggerBus "Gateway: hrl trigger bus";
CM_ BO_ 2026 "Gateway message: hrl external event";
CM_ SG_ 2026 GTW_hrlEventStartEpoch "Gateway: hrl event start epoch";
CM_ SG_ 2026 GTW_hrlEventEndEpoch "Gateway: hrl event end epoch";
CM_ BO_ 60 "Gateway message: info";
CM_ SG_ 60 GTW_infoIndex "Gateway: info index";
CM_ SG_ 60 GTW_buildType "Gateway: build type";
CM_ SG_ 60 GTW_hardwareId "GTW hardware ID";
CM_ SG_ 60 GTW_platformType "Gateway: platform type";
CM_ SG_ 60 GTW_appCrc "Gateway: app crc";
CM_ SG_ 60 GTW_applicationGitHash "Gateway: application git hash";
CM_ SG_ 60 GTW_bootGitHash "Gateway: boot git hash";
CM_ BO_ 1370 "Gateway message: mismatch fault";
CM_ SG_ 1370 GTW_mismatchFaultIndex "Gateway: mismatch fault index";
CM_ SG_ 1370 GTW_mismatchFaultChecksum "Gateway: mismatch fault checksum";
CM_ SG_ 1370 GTW_mismatchFaultCounter "Gateway: mismatch fault counter";
CM_ SG_ 1370 GTW_GTWmismatchFault "Reports the Gateway (GTW) running a firmware version that does not match the rest of the vehicle";
CM_ SG_ 1370 GTW_BMSmismatchFault "Reports the high voltage Battery Management System (BMS) electronic control unit (ECU) running a firmware version that does not match the rest of the vehicle";
CM_ SG_ 1370 GTW_APSmismatchFault "Reports the Autopilot Processor Secondary (APS) electronic control unit (ECU) running a firmware version that does not match the rest of the vehicle";
CM_ SG_ 1370 GTW_BLEEPCENTERmismatchFault "Reports the Bluetooth Low Energy End Point Center (BLEEPCENTER) electronic control unit (ECU) running a firmware version that does not match the rest of the vehicle";
CM_ SG_ 1370 GTW_BLEEPLEFTmismatchFault "Reports the Bluetooth Low Energy End Point Left (BLEEPLEFT) electronic control unit (ECU) running a firmware version that does not match the rest of the vehicle";
CM_ SG_ 1370 GTW_BLEEPREARmismatchFault "Reports the Bluetooth Low Energy End Point Rear (BLEEPREAR) electronic control unit (ECU) running a firmware version that does not match the rest of the vehicle";
CM_ SG_ 1370 GTW_BLEEPRIGHTmismatchFault "Reports the Bluetooth Low Energy End Point Right (BLEEPRIGHT) electronic control unit (ECU) running a firmware version that does not match the rest of the vehicle";
CM_ SG_ 1370 GTW_CBCmismatchFault "Reports the Cabin Blower Controller (CBC) electronic control unit (ECU) running a firmware version that does not match the rest of the vehicle";
CM_ SG_ 1370 GTW_CMPmismatchFault "Reports the air conditioning compressor (CMP) electronic control unit (ECU) running a firmware version that does not match the rest of the vehicle";
CM_ SG_ 1370 GTW_CPmismatchFault "Reports the Charge Port (CP) electronic control unit (ECU) running a firmware version that does not match the rest of the vehicle";
CM_ SG_ 1370 GTW_DIFmismatchFault "Reports the front drive inverter (DIF) electronic control unit (ECU) running a firmware version that does not match the rest of the vehicle";
CM_ SG_ 1370 GTW_DIRmismatchFault "Reports the rear drive inverter (DIR) electronic control unit (ECU) running a firmware version that does not match the rest of the vehicle";
CM_ SG_ 1370 GTW_EPAS3PmismatchFault "Reports the primary Electronic Power Assisted Steering (EPAS3P) electronic control unit (ECU) running a firmware version that does not match the rest of the vehicle";
CM_ SG_ 1370 GTW_EPAS3SmismatchFault "Reports the secondary Electronic Power Assisted Steering (EPAS3S) electronic control unit (ECU) running a firmware version that does not match the rest of the vehicle";
CM_ SG_ 1370 GTW_EPBLmismatchFault "Reports the left Electronic Park Brake (EPBL) electronic control unit (ECU) running a firmware version that does not match the rest of the vehicle";
CM_ SG_ 1370 GTW_EPBRmismatchFault "Reports the right Electronic Park Brake (EPBR) electronic control unit (ECU) running a firmware version that does not match the rest of the vehicle";
CM_ SG_ 1370 GTW_ESPCALmismatchFault "Reports the Electronic Stability Program Calibration (ESPCAL) electronic control unit (ECU) running a firmware version that does not match the rest of the vehicle";
CM_ SG_ 1370 GTW_ESPmismatchFault "Reports the Electronic Stability Program (ESP) electronic control unit (ECU) running a firmware version that does not match the rest of the vehicle";
CM_ SG_ 1370 GTW_HCM3LmismatchFault "Reports the left LED matrix Headlamp Control Module (HCM3L) electronic control unit (ECU) running a firmware version that does not match the rest of the vehicle";
CM_ SG_ 1370 GTW_HCM3RmismatchFault "Reports the right LED matrix Headlamp Control Module (HCM3R) electronic control unit (ECU) running a firmware version that does not match the rest of the vehicle";
CM_ SG_ 1370 GTW_HCMLmismatchFault "Reports the left Headlamp Control Module (HCML) electronic control unit (ECU) running a firmware version that does not match the rest of the vehicle";
CM_ SG_ 1370 GTW_HCMRmismatchFault "Reports the right Headlamp Control Module (HCMR) electronic control unit (ECU) running a firmware version that does not match the rest of the vehicle";
CM_ SG_ 1370 GTW_HVPmismatchFault "Reports the High Voltage Processor (HVP) electronic control unit (ECU) running a firmware version that does not match the rest of the vehicle";
CM_ SG_ 1370 GTW_IBSTCALmismatchFault "Reports the electromechanical brake booster calibration, or iBooster Calibration (IBSTCAL), electronic control unit (ECU) running a firmware version that does not match the rest of the vehicle";
CM_ SG_ 1370 GTW_IBSTmismatchFault "Reports the electromechanical brake booster, or iBooster (IBST), electronic control unit (ECU) running a firmware version that does not match the rest of the vehicle";
CM_ SG_ 1370 GTW_LVBMSmismatchFault "Reports the Low Voltage Battery Management System (LVBMS) electronic control unit (ECU) running a firmware version that does not match the rest of the vehicle";
CM_ SG_ 1370 GTW_OCS1PmismatchFault "Reports the Occupancy Classification System - 1st Row Passenger (OCS1P) electronic control unit (ECU) running a firmware version that does not match the rest of the vehicle";
CM_ SG_ 1370 GTW_OPCFmismatchFault "Reports the front Oil Pump Controller (OPCF) electronic control unit (ECU) running a firmware version that does not match the rest of the vehicle";
CM_ SG_ 1370 GTW_OPCRmismatchFault "Reports the rear Oil Pump Controller (OPCR) electronic control unit (ECU) running a firmware version that does not match the rest of the vehicle";
CM_ SG_ 1370 GTW_PARKmismatchFault "Reports the Park Assist (PARK) electronic control unit (ECU) running a firmware version that does not match the rest of the vehicle";
CM_ SG_ 1370 GTW_PCSCPU2mismatchFault "Reports the Power Conversion System AC charging core (PCSCPU2) electronic control unit (ECU) running a firmware version that does not match the rest of the vehicle";
CM_ SG_ 1370 GTW_PCSmismatchFault "Reports the Power Conversion System (PCS) electronic control unit (ECU) running a firmware version that does not match the rest of the vehicle";
CM_ SG_ 1370 GTW_PMFmismatchFault "Reports the front Pedal Monitor (PMF) electronic control unit (ECU) running a firmware version that does not match the rest of the vehicle";
CM_ SG_ 1370 GTW_PMRmismatchFault "Reports the rear Pedal Monitor (PMR) electronic control unit (ECU) running a firmware version that does not match the rest of the vehicle";
CM_ SG_ 1370 GTW_PTCmismatchFault "Reports the Positive Temperature Coefficient (PTC) heater electronic control unit (ECU) running a firmware version that does not match the rest of the vehicle";
CM_ SG_ 1370 GTW_RCMCALmismatchFault "Reports the Restraint Control Module Calibration (RCMCAL) electronic control unit (ECU) running a firmware version that does not match the rest of the vehicle";
CM_ SG_ 1370 GTW_RCMmismatchFault "Reports the Restraint Control Module (RCM) electronic control unit (ECU) running a firmware version that does not match the rest of the vehicle";
CM_ SG_ 1370 GTW_SCCMmismatchFault "Reports the Steering Column Control Module (SCCM) electronic control unit (ECU) running a firmware version that does not match the rest of the vehicle";
CM_ SG_ 1370 GTW_SDCRmismatchFault "Reports the Secondary Disconnect Controller (SDCR) electronic control unit (ECU) running a firmware version that does not match the rest of the vehicle";
CM_ SG_ 1370 GTW_SWCmismatchFault "Reports the Steering Wheel Controller (SWC) electronic control unit (ECU) running a firmware version that does not match the rest of the vehicle";
CM_ SG_ 1370 GTW_THSmismatchFault "Reports the Temperature Humidity Sensor (THS) electronic control unit (ECU) running a firmware version that does not match the rest of the vehicle";
CM_ SG_ 1370 GTW_VCFRONTmismatchFault "Reports the front vehicle controller (VCFRONT) electronic control unit (ECU) running a firmware version that does not match the rest of the vehicle";
CM_ SG_ 1370 GTW_VCLEFTmismatchFault "Reports the left vehicle controller (VCLEFT) electronic control unit (ECU) running a firmware version that does not match the rest of the vehicle";
CM_ SG_ 1370 GTW_VCRIGHTmismatchFault "Reports the right vehicle controller (VCRIGHT) electronic control unit (ECU) running a firmware version that does not match the rest of the vehicle";
CM_ SG_ 1370 GTW_VCSECmismatchFault "Reports the vehicle security controller (VCSEC) electronic control unit (ECU) running a firmware version that does not match the rest of the vehicle";
CM_ SG_ 1370 GTW_PMmismatchFault "Reports the Pedal Monitor (PM) electronic control unit (ECU) running a firmware version that does not match the rest of the vehicle";
CM_ BO_ 840 "Gateway message: status";
CM_ SG_ 840 GTW_vehicleVersionMatchStatus "Signal to indicate if the vehicle ECUs are all on a matched production version";
CM_ SG_ 840 GTW_hwtype "Describes the chip GTW is running on; raw 0 = signal not available (SNA)";
CM_ SG_ 840 GTW_jcanProductName "Describes the JCAN reference (product) name; raw 0 = signal not available (SNA)";
CM_ SG_ 840 GTW_uptimeSeconds "GTW uptime in seconds";
CM_ SG_ 840 GTW_boardRevision "Board revision ID of the MCU PCBA";
CM_ SG_ 840 GTW_touchcoreOsType "Gateway: touchcore os type";
CM_ SG_ 840 GTW_sentryModeState "Sentry Mode state; raw 6 = signal not available (SNA)";
CM_ SG_ 840 GTW_secureBootEnabled "Gateway: secure boot enabled";
CM_ SG_ 840 GTW_socSleepType "Describes the sleep type GTW is expecting from the SoC; raw 0 = signal not available (SNA)";
CM_ SG_ 840 GTW_resetType "Describes the type of reset GTW experienced; raw 0 = signal not available (SNA)";
CM_ BO_ 1005 "Gateway message: update status";
CM_ SG_ 1005 GTW_i2cUpdateActive "Gateway: i2c update active";
CM_ SG_ 1005 GTW_peripheralConfirmedUpdateNee "Detects if peripheral has confirmed update is needed";
CM_ SG_ 1005 GTW_ocuFailed "Reports the offboard charger update was unsuccessful.";
CM_ SG_ 1005 GTW_ecuUpdateStarted "Reports whether Electronic Control Unit (ECU) update phase is active.";
CM_ SG_ 1005 GTW_updateStarted "Main update in progress bit";
CM_ BO_ 1112 "Gateway message: veh nm";
CM_ SG_ 1112 GTW_nmGoingToSleep "Network management - Going to sleep state";
CM_ SG_ 1112 GTW_nmWakeUpBus "Gateway: nm wake up bus";
CM_ SG_ 1112 GTW_chBusAsleep "Chassis bus sleep state";
CM_ SG_ 1112 GTW_ethBusAsleep "ETH bus sleep state";
CM_ SG_ 1112 GTW_nmKeepAwakeReason "Network management - Keep awake reason; raw 0 = signal not available (SNA)";
CM_ SG_ 1112 GTW_nmWakeUpReason "Network management - Wakeup reason";
CM_ SG_ 1112 GTW_ethKeepAwakeReason "Reason GTW is keeping ETH bus awake; raw 0 = signal not available (SNA)";
CM_ SG_ 1112 GTW_nmDebugWakeUp "Gateway: nm debug wake up";
CM_ SG_ 1112 GTW_OTAKeepAwake "Signals that the vehicle buses should remain awake for an ongoing OTA update";
CM_ SG_ 1112 GTW_smsPokeReceived "The modem indicated it received an SMS poke";
CM_ SG_ 1112 GTW_bdyBusAsleep "BDY bus sleep state";
CM_ BO_ 1470 "IDB ECU message: alert log";
CM_ SG_ 1470 IDB_alertID "IDB ECU: alert ID";
CM_ SG_ 1470 IDB_alertState "IDB ECU: alert state";
CM_ SG_ 1470 IDB_a014_wheelSpeedSensorFreq "IDB ECU: a014 wheel speed sensor freq";
CM_ SG_ 1470 IDB_a014_wheelSpeedSensorPhase "IDB ECU: a014 wheel speed sensor phase";
CM_ SG_ 1470 IDB_a014_wheelSpeedSensorMisinst "IDB ECU: a014 wheel speed sensor misinstallation";
CM_ SG_ 1470 IDB_a014_wheelSpeedSensorWrongEx "IDB ECU: a014 wheel speed sensor wrong exciter";
CM_ SG_ 1470 IDB_a014_wheelSpeedSensorSpeedJu "IDB ECU: a014 wheel speed sensor speed jump minus";
CM_ SG_ 1470 IDB_a014_wheelSpeedSensorSp_0001 "IDB ECU: a014 wheel speed sensor speed jump plus";
CM_ SG_ 1470 IDB_a014_wheelSpeedSensorAirGap "IDB ECU: a014 wheel speed sensor air gap";
CM_ SG_ 1470 IDB_a014_wheelSpeedSensorBIST "IDB ECU: a014 wheel speed sensor BIST";
CM_ SG_ 1470 IDB_a014_wheelSpeedSensorLeakage "IDB ECU: a014 wheel speed sensor leakage cur";
CM_ SG_ 1470 IDB_a014_wheelSpeedSensorOverTem "IDB ECU: a014 wheel speed sensor over temp";
CM_ SG_ 1470 IDB_a014_wheelSpeedSensorSh_0001 "IDB ECU: a014 wheel speed sensor short to gnd";
CM_ SG_ 1470 IDB_a014_wheelSpeedSensorShortTo "IDB ECU: a014 wheel speed sensor short to bat";
CM_ SG_ 1470 IDB_a014_wheelSpeedSensorOpen "IDB ECU: a014 wheel speed sensor open";
CM_ SG_ 1470 IDB_a015_wheelSpeedSensorFreq "IDB ECU: a015 wheel speed sensor freq";
CM_ SG_ 1470 IDB_a015_wheelSpeedSensorPhase "IDB ECU: a015 wheel speed sensor phase";
CM_ SG_ 1470 IDB_a015_wheelSpeedSensorMisinst "IDB ECU: a015 wheel speed sensor misinstallation";
CM_ SG_ 1470 IDB_a015_wheelSpeedSensorWrongEx "IDB ECU: a015 wheel speed sensor wrong exciter";
CM_ SG_ 1470 IDB_a015_wheelSpeedSensorSpeedJu "IDB ECU: a015 wheel speed sensor speed jump minus";
CM_ SG_ 1470 IDB_a015_wheelSpeedSensorSp_0001 "IDB ECU: a015 wheel speed sensor speed jump plus";
CM_ SG_ 1470 IDB_a015_wheelSpeedSensorAirGap "IDB ECU: a015 wheel speed sensor air gap";
CM_ SG_ 1470 IDB_a015_wheelSpeedSensorBIST "IDB ECU: a015 wheel speed sensor BIST";
CM_ SG_ 1470 IDB_a015_wheelSpeedSensorLeakage "IDB ECU: a015 wheel speed sensor leakage cur";
CM_ SG_ 1470 IDB_a015_wheelSpeedSensorOverTem "IDB ECU: a015 wheel speed sensor over temp";
CM_ SG_ 1470 IDB_a015_wheelSpeedSensorSh_0001 "IDB ECU: a015 wheel speed sensor short to gnd";
CM_ SG_ 1470 IDB_a015_wheelSpeedSensorShortTo "IDB ECU: a015 wheel speed sensor short to bat";
CM_ SG_ 1470 IDB_a015_wheelSpeedSensorOpen "IDB ECU: a015 wheel speed sensor open";
CM_ SG_ 1470 IDB_a016_wheelSpeedSensorFreq "IDB ECU: a016 wheel speed sensor freq";
CM_ SG_ 1470 IDB_a016_wheelSpeedSensorPhase "IDB ECU: a016 wheel speed sensor phase";
CM_ SG_ 1470 IDB_a016_wheelSpeedSensorMisinst "IDB ECU: a016 wheel speed sensor misinstallation";
CM_ SG_ 1470 IDB_a016_wheelSpeedSensorWrongEx "IDB ECU: a016 wheel speed sensor wrong exciter";
CM_ SG_ 1470 IDB_a016_wheelSpeedSensorSpeedJu "IDB ECU: a016 wheel speed sensor speed jump minus";
CM_ SG_ 1470 IDB_a016_wheelSpeedSensorSp_0001 "IDB ECU: a016 wheel speed sensor speed jump plus";
CM_ SG_ 1470 IDB_a016_wheelSpeedSensorAirGap "IDB ECU: a016 wheel speed sensor air gap";
CM_ SG_ 1470 IDB_a016_wheelSpeedSensorBIST "IDB ECU: a016 wheel speed sensor BIST";
CM_ SG_ 1470 IDB_a016_wheelSpeedSensorLeakage "IDB ECU: a016 wheel speed sensor leakage cur";
CM_ SG_ 1470 IDB_a016_wheelSpeedSensorOverTem "IDB ECU: a016 wheel speed sensor over temp";
CM_ SG_ 1470 IDB_a016_wheelSpeedSensorSh_0001 "IDB ECU: a016 wheel speed sensor short to gnd";
CM_ SG_ 1470 IDB_a016_wheelSpeedSensorShortTo "IDB ECU: a016 wheel speed sensor short to bat";
CM_ SG_ 1470 IDB_a016_wheelSpeedSensorOpen "IDB ECU: a016 wheel speed sensor open";
CM_ SG_ 1470 IDB_a017_wheelSpeedSensorFreq "IDB ECU: a017 wheel speed sensor freq";
CM_ SG_ 1470 IDB_a017_wheelSpeedSensorPhase "IDB ECU: a017 wheel speed sensor phase";
CM_ SG_ 1470 IDB_a017_wheelSpeedSensorMisinst "IDB ECU: a017 wheel speed sensor misinstallation";
CM_ SG_ 1470 IDB_a017_wheelSpeedSensorWrongEx "IDB ECU: a017 wheel speed sensor wrong exciter";
CM_ SG_ 1470 IDB_a017_wheelSpeedSensorSpeedJu "IDB ECU: a017 wheel speed sensor speed jump minus";
CM_ SG_ 1470 IDB_a017_wheelSpeedSensorSp_0001 "IDB ECU: a017 wheel speed sensor speed jump plus";
CM_ SG_ 1470 IDB_a017_wheelSpeedSensorAirGap "IDB ECU: a017 wheel speed sensor air gap";
CM_ SG_ 1470 IDB_a017_wheelSpeedSensorBIST "IDB ECU: a017 wheel speed sensor BIST";
CM_ SG_ 1470 IDB_a017_wheelSpeedSensorLeakage "IDB ECU: a017 wheel speed sensor leakage cur";
CM_ SG_ 1470 IDB_a017_wheelSpeedSensorOverTem "IDB ECU: a017 wheel speed sensor over temp";
CM_ SG_ 1470 IDB_a017_wheelSpeedSensorSh_0001 "IDB ECU: a017 wheel speed sensor short to gnd";
CM_ SG_ 1470 IDB_a017_wheelSpeedSensorShortTo "IDB ECU: a017 wheel speed sensor short to bat";
CM_ SG_ 1470 IDB_a017_wheelSpeedSensorOpen "IDB ECU: a017 wheel speed sensor open";
CM_ SG_ 1470 IDB_a020_canSignalValidity "IDB ECU: a020 can signal validity";
CM_ SG_ 1470 IDB_a020_signalValueCrosscheck "IDB ECU: a020 signal value crosscheck";
CM_ SG_ 1470 IDB_a030_primaryExternalCircuitL "IDB ECU: a030 primary external circuit leakage";
CM_ SG_ 1470 IDB_a030_secondaryExternalCircui "IDB ECU: a030 secondary external circuit leakage";
CM_ SG_ 1470 IDB_a030_primaryChamberInternalL "IDB ECU: a030 primary chamber internal leakage";
CM_ SG_ 1470 IDB_a030_syncModeInternalLeakage "IDB ECU: a030 sync mode internal leakage";
CM_ SG_ 1470 IDB_a030_secondaryChamberInterna "IDB ECU: a030 secondary chamber internal leakage";
CM_ SG_ 1470 IDB_a030_masterCylinderInternalL "IDB ECU: a030 master cylinder internal leakage";
CM_ SG_ 1470 IDB_a060_validityOnChassisBus "IDB ECU: a060 validity on chassis bus";
CM_ SG_ 1470 IDB_a060_validityOnPartyBus "IDB ECU: a060 validity on party bus";
CM_ SG_ 1470 IDB_a061_validityOnChassisBus "IDB ECU: a061 validity on chassis bus";
CM_ SG_ 1470 IDB_a061_validityOnPartyBus "IDB ECU: a061 validity on party bus";
CM_ SG_ 1470 IDB_a063_validityOnChassisBus "IDB ECU: a063 validity on chassis bus";
CM_ SG_ 1470 IDB_a063_validityOnPartyBus "IDB ECU: a063 validity on party bus";
CM_ SG_ 1470 IDB_a064_validityOnChassisBus "IDB ECU: a064 validity on chassis bus";
CM_ SG_ 1470 IDB_a064_validityOnPartyBus "IDB ECU: a064 validity on party bus";
CM_ SG_ 1470 IDB_a065_validityOnChassisBus "IDB ECU: a065 validity on chassis bus";
CM_ SG_ 1470 IDB_a065_validityOnPartyBus "IDB ECU: a065 validity on party bus";
CM_ SG_ 1470 IDB_a106_qualifierValidity "IDB ECU: a106 qualifier validity";
CM_ SG_ 1470 IDB_a106_signalNotAvailable "IDB ECU: a106 signal not available";
CM_ SG_ 1470 IDB_a107_qualifierValidity "IDB ECU: a107 qualifier validity";
CM_ SG_ 1470 IDB_a107_signalNotAvailable "IDB ECU: a107 signal not available";
CM_ SG_ 1470 IDB_a112_qualifierValidity "IDB ECU: a112 qualifier validity";
CM_ SG_ 1470 IDB_a112_signalNotAvailable "IDB ECU: a112 signal not available";
CM_ SG_ 1470 IDB_a113_qualifierValidity "IDB ECU: a113 qualifier validity";
CM_ SG_ 1470 IDB_a113_signalNotAvailable "IDB ECU: a113 signal not available";
CM_ SG_ 1470 IDB_a114_qualifierValidity "IDB ECU: a114 qualifier validity";
CM_ SG_ 1470 IDB_a114_signalNotAvailable "IDB ECU: a114 signal not available";
CM_ SG_ 1470 IDB_a126_PMebrCmdStateValidity "IDB ECU: a126 p mebr cmd state validity";
CM_ SG_ 1470 IDB_a126_PMstate2Validity "IDB ECU: a126 p mstate2 validity";
CM_ SG_ 1470 IDB_a126_PMstate2Missing "IDB ECU: a126 p mstate2 missing";
CM_ SG_ 1470 IDB_a126_DIchassisControlValidit "IDB ECU: a126 d ichassis control validity";
CM_ SG_ 1470 IDB_a126_DIchassisControlMissing "IDB ECU: a126 d ichassis control missing";
CM_ SG_ 1470 IDB_a126_DIrequestActiveValidity "IDB ECU: a126 d irequest active validity";
CM_ SG_ 1470 IDB_a129_validityOnChassisBus "IDB ECU: a129 validity on chassis bus";
CM_ SG_ 1470 IDB_a129_validityOnPartyBus "IDB ECU: a129 validity on party bus";
CM_ SG_ 1470 IDB_a130_PMbrakePedalCmdQFValidi "IDB ECU: a130 p mbrake pedal cmd QF validity";
CM_ SG_ 1470 IDB_a130_PMstate2Validity "IDB ECU: a130 p mstate2 validity";
CM_ SG_ 1470 IDB_a130_PMstate2Missing "IDB ECU: a130 p mstate2 missing";
CM_ SG_ 1470 IDB_a130_DIbrakeCommandValidity "IDB ECU: a130 d ibrake command validity";
CM_ SG_ 1470 IDB_a130_DIbrakeCommandMissing "IDB ECU: a130 d ibrake command missing";
CM_ SG_ 1470 IDB_a130_DIbrakeTorqueCommandFul "IDB ECU: a130 d ibrake torque command full SNA";
CM_ SG_ 1470 IDB_a130_DIbrakeTorqueComma_0001 "IDB ECU: a130 d ibrake torque command full too low";
CM_ SG_ 1470 IDB_a132_validityOnChassisBus "IDB ECU: a132 validity on chassis bus";
CM_ SG_ 1470 IDB_a132_validityOnPartyBus "IDB ECU: a132 validity on party bus";
CM_ BO_ 983 "IDB ECU message: alert matrix";
CM_ SG_ 983 IDB_matrixIndex "IDB ECU: matrix index";
CM_ SG_ 983 IDB_a001_mcuGenericFault "IDB ECU: a001 mcu generic fault";
CM_ SG_ 983 IDB_a002_supplyOvervoltage "IDB ECU: a002 supply overvoltage";
CM_ SG_ 983 IDB_a003_supplyHardOvervoltage "IDB ECU: a003 supply hard overvoltage";
CM_ SG_ 983 IDB_a004_supplyUndervoltage "IDB ECU: a004 supply undervoltage";
CM_ SG_ 983 IDB_a005_supplyMidUndervoltage "IDB ECU: a005 supply mid undervoltage";
CM_ SG_ 983 IDB_a006_supplyHardUndervoltage "IDB ECU: a006 supply hard undervoltage";
CM_ SG_ 983 IDB_a007_wakeLineOpen "IDB ECU: a007 wake line open";
CM_ SG_ 983 IDB_a008_motorPowerOpen "IDB ECU: a008 motor power open";
CM_ SG_ 983 IDB_a009_asicBoostFault "IDB ECU: a009 asic boost fault";
CM_ SG_ 983 IDB_a010_asicGenericFault "IDB ECU: a010 asic generic fault";
CM_ SG_ 983 IDB_a011_solenoidValveFault "IDB ECU: a011 solenoid valve fault";
CM_ SG_ 983 IDB_a012_motorGenericFault "IDB ECU: a012 motor generic fault";
CM_ SG_ 983 IDB_a013_motorPosSensorFault "IDB ECU: a013 motor pos sensor fault";
CM_ SG_ 983 IDB_a014_FrLWSSFault "IDB ECU: a014 fr LWSS fault";
CM_ SG_ 983 IDB_a015_FrRWSSFault "IDB ECU: a015 fr RWSS fault";
CM_ SG_ 983 IDB_a016_ReLWSSFault "IDB ECU: a016 re LWSS fault";
CM_ SG_ 983 IDB_a017_ReRWSSFault "IDB ECU: a017 re RWSS fault";
CM_ SG_ 983 IDB_a018_WSSGenericFault "IDB ECU: a018 WSS generic fault";
CM_ SG_ 983 IDB_a019_pedalSensorFault "IDB ECU: a019 pedal sensor fault";
CM_ SG_ 983 IDB_a020_RCUpedalTravelMismatch "IDB ECU: a020 RC upedal travel mismatch";
CM_ SG_ 983 IDB_a021_pedalSensorNotCal "IDB ECU: a021 pedal sensor not cal";
CM_ SG_ 983 IDB_a022_brakeFluidLow "IDB ECU: a022 brake fluid low";
CM_ SG_ 983 IDB_a023_steeringImplausible "IDB ECU: a023 steering implausible";
CM_ SG_ 983 IDB_a024_yawImplausible "IDB ECU: a024 yaw implausible";
CM_ SG_ 983 IDB_a025_ayImplausible "IDB ECU: a025 ay implausible";
CM_ SG_ 983 IDB_a026_axImplausible "IDB ECU: a026 ax implausible";
CM_ SG_ 983 IDB_a027_circuitPresSensorFault "IDB ECU: a027 circuit pres sensor fault";
CM_ SG_ 983 IDB_a028_simPresSensorFault "IDB ECU: a028 sim pres sensor fault";
CM_ SG_ 983 IDB_a029_pressureSensNotCal "IDB ECU: a029 pressure sens not cal";
CM_ SG_ 983 IDB_a030_fluidLeakDetected "IDB ECU: a030 fluid leak detected";
CM_ SG_ 983 IDB_a031_solenoidValveStuck "IDB ECU: a031 solenoid valve stuck";
CM_ SG_ 983 IDB_a032_motorSoftOverheat "IDB ECU: a032 motor soft overheat";
CM_ SG_ 983 IDB_a033_motorHardOverheat "IDB ECU: a033 motor hard overheat";
CM_ SG_ 983 IDB_a034_motorPositionSetFault "IDB ECU: a034 motor position set fault";
CM_ SG_ 983 IDB_a035_motorStuck "IDB ECU: a035 motor stuck";
CM_ SG_ 983 IDB_a036_partyBusOff "IDB ECU: a036 party bus off";
CM_ SG_ 983 IDB_a037_chassisBusOff "IDB ECU: a037 chassis bus off";
CM_ SG_ 983 IDB_a038_motorInitFault "IDB ECU: a038 motor init fault";
CM_ SG_ 983 IDB_a039_absActive "IDB ECU: a039 abs active";
CM_ SG_ 983 IDB_a040_ebdActive "IDB ECU: a040 ebd active";
CM_ SG_ 983 IDB_a041_vdcActive "IDB ECU: a041 vdc active";
CM_ SG_ 983 IDB_a042_btcActive "IDB ECU: a042 btc active";
CM_ SG_ 983 IDB_a043_cbcActive "IDB ECU: a043 cbc active";
CM_ SG_ 983 IDB_a044_standstillSkidDetected "IDB ECU: a044 standstill skid detected";
CM_ SG_ 983 IDB_a045_panicBrakeAssistActive "IDB ECU: a045 panic brake assist active";
CM_ SG_ 983 IDB_a046_fadeCompensationActive "IDB ECU: a046 fade compensation active";
CM_ SG_ 983 IDB_a047_brakeDiscWipeActive "IDB ECU: a047 brake disc wipe active";
CM_ SG_ 983 IDB_a048_scmActive "IDB ECU: a048 scm active";
CM_ SG_ 983 IDB_a049_cdpActive "IDB ECU: a049 cdp active";
CM_ SG_ 983 IDB_a050_absFaulted "IDB ECU: a050 abs faulted";
CM_ SG_ 983 IDB_a051_ebdFaulted "IDB ECU: a051 ebd faulted";
CM_ SG_ 983 IDB_a052_vdcFaulted "IDB ECU: a052 vdc faulted";
CM_ SG_ 983 IDB_a053_DItorquePathFaulted "IDB ECU: a053 d itorque path faulted";
CM_ SG_ 983 IDB_a054_skidDetectionFaulted "IDB ECU: a054 skid detection faulted";
CM_ SG_ 983 IDB_a055_panicBrakeAssistFaulted "IDB ECU: a055 panic brake assist faulted";
CM_ SG_ 983 IDB_a056_fadeCompensationFaulted "IDB ECU: a056 fade compensation faulted";
CM_ SG_ 983 IDB_a057_bdwRequestInvalid "IDB ECU: a057 bdw request invalid";
CM_ SG_ 983 IDB_a058_scmFaulted "IDB ECU: a058 scm faulted";
CM_ SG_ 983 IDB_a059_cdpFaulted "IDB ECU: a059 cdp faulted";
CM_ SG_ 983 IDB_a060_RCUstatusDLC "IDB ECU: a060 RC ustatus DLC";
CM_ SG_ 983 IDB_a061_RCUstatusChecksum "IDB ECU: a061 RC ustatus checksum";
CM_ SG_ 983 IDB_a062_RCUstatusCounter "IDB ECU: a062 RC ustatus counter";
CM_ SG_ 983 IDB_a063_RCUactuationDLC "IDB ECU: a063 RC uactuation DLC";
CM_ SG_ 983 IDB_a064_RCUactuationChecksum "IDB ECU: a064 RC uactuation checksum";
CM_ SG_ 983 IDB_a065_RCUactuationCounter "IDB ECU: a065 RC uactuation counter";
CM_ SG_ 983 IDB_a066_DIFtorqueDLC "IDB ECU: a066 DI ftorque DLC";
CM_ SG_ 983 IDB_a067_DIFtorqueChecksum "IDB ECU: a067 DI ftorque checksum";
CM_ SG_ 983 IDB_a068_DIFtorqueCounter "IDB ECU: a068 DI ftorque counter";
CM_ SG_ 983 IDB_a069_DIchassisControlDLC "IDB ECU: a069 d ichassis control DLC";
CM_ SG_ 983 IDB_a070_DIchassisControlChecksu "IDB ECU: a070 d ichassis control checksum";
CM_ SG_ 983 IDB_a071_DIchassisControlCounter "IDB ECU: a071 d ichassis control counter";
CM_ SG_ 983 IDB_a072_DIsystemStatusDLC "IDB ECU: a072 d isystem status DLC";
CM_ SG_ 983 IDB_a073_DIsystemStatusChecksum "IDB ECU: a073 d isystem status checksum";
CM_ SG_ 983 IDB_a074_DIsystemStatusCounter "IDB ECU: a074 d isystem status counter";
CM_ SG_ 983 IDB_a075_DIRtorqueDLC "IDB ECU: a075 DI rtorque DLC";
CM_ SG_ 983 IDB_a076_DIRtorqueChecksum "IDB ECU: a076 DI rtorque checksum";
CM_ SG_ 983 IDB_a077_DIRtorqueCounter "IDB ECU: a077 DI rtorque counter";
CM_ SG_ 983 IDB_a078_DIvdcLeftDLC "IDB ECU: a078 d ivdc left DLC";
CM_ SG_ 983 IDB_a079_DIvdcLeftChecksum "IDB ECU: a079 d ivdc left checksum";
CM_ SG_ 983 IDB_a080_DIvdcLeftCounter "IDB ECU: a080 d ivdc left counter";
CM_ SG_ 983 IDB_a081_DIvdcRightDLC "IDB ECU: a081 d ivdc right DLC";
CM_ SG_ 983 IDB_a082_DIvdcRightChecksum "IDB ECU: a082 d ivdc right checksum";
CM_ SG_ 983 IDB_a083_DIvdcRightCounter "IDB ECU: a083 d ivdc right counter";
CM_ SG_ 983 IDB_a084_EPAS3PsysStatusDLC "IDB ECU: a084 EPAS3 psys status DLC";
CM_ SG_ 983 IDB_a085_EPAS3PsysStatusChecksum "IDB ECU: a085 EPAS3 psys status checksum";
CM_ SG_ 983 IDB_a086_EPAS3PsysStatusCounter "IDB ECU: a086 EPAS3 psys status counter";
CM_ SG_ 983 IDB_a087_PMstate2DLC "IDB ECU: a087 p mstate2 DLC";
CM_ SG_ 983 IDB_a088_PMstate2Checksum "IDB ECU: a088 p mstate2 checksum";
CM_ SG_ 983 IDB_a089_PMstate2Counter "IDB ECU: a089 p mstate2 counter";
CM_ SG_ 983 IDB_a090_RCMinertial1DLC "IDB ECU: a090 RC minertial1 DLC";
CM_ SG_ 983 IDB_a091_RCMinertial1Checksum "IDB ECU: a091 RC minertial1 checksum";
CM_ SG_ 983 IDB_a092_RCMinertial1Counter "IDB ECU: a092 RC minertial1 counter";
CM_ SG_ 983 IDB_a093_RCMinertial2DLC "IDB ECU: a093 RC minertial2 DLC";
CM_ SG_ 983 IDB_a094_RCMinertial2Checksum "IDB ECU: a094 RC minertial2 checksum";
CM_ SG_ 983 IDB_a095_RCMinertial2Counter "IDB ECU: a095 RC minertial2 counter";
CM_ SG_ 983 IDB_a096_VCFRONTLVPowerStateDLC "IDB ECU: a096 VCFRONTLV power state DLC";
CM_ SG_ 983 IDB_a097_VCFRONTLVPwrStChecksum "IDB ECU: a097 VCFRONTLV pwr st checksum";
CM_ SG_ 983 IDB_a098_VCFRONTLVPwrStCounter "IDB ECU: a098 VCFRONTLV pwr st counter";
CM_ SG_ 983 IDB_a099_RCMcollisionDLC "IDB ECU: a099 RC mcollision DLC";
CM_ SG_ 983 IDB_a100_RCMcollisionChecksum "IDB ECU: a100 RC mcollision checksum";
CM_ SG_ 983 IDB_a101_RCMcollisionCounter "IDB ECU: a101 RC mcollision counter";
CM_ SG_ 983 IDB_a102_bdwRequestActiveInvalid "IDB ECU: a102 bdw request active invalid";
CM_ SG_ 983 IDB_a103_DIfullTorquePathFaulted "IDB ECU: a103 d ifull torque path faulted";
CM_ SG_ 983 IDB_a104_DIaccelPosInvalid "IDB ECU: a104 d iaccel pos invalid";
CM_ SG_ 983 IDB_a105_DIgearInvalid "IDB ECU: a105 d igear invalid";
CM_ SG_ 983 IDB_a106_DIFtorqueInvalid "IDB ECU: a106 DI ftorque invalid";
CM_ SG_ 983 IDB_a107_DIRtorqueInvalid "IDB ECU: a107 DI rtorque invalid";
CM_ SG_ 983 IDB_a108_EPBstatusDLC "IDB ECU: a108 EP bstatus DLC";
CM_ SG_ 983 IDB_a109_BDWsignalInvalid "IDB ECU: a109 BD wsignal invalid";
CM_ SG_ 983 IDB_a110_EPBstatusCounter "IDB ECU: a110 EP bstatus counter";
CM_ SG_ 983 IDB_a111_EPBstatusChecksum "IDB ECU: a111 EP bstatus checksum";
CM_ SG_ 983 IDB_a112_yawRateInvalid "IDB ECU: a112 yaw rate invalid";
CM_ SG_ 983 IDB_a113_latAccelInvalid "IDB ECU: a113 lat accel invalid";
CM_ SG_ 983 IDB_a114_longAccelInvalid "IDB ECU: a114 long accel invalid";
CM_ SG_ 983 IDB_a115_VCFRONTespLvStInvalid "IDB ECU: a115 VCFRON tesp lv st invalid";
CM_ SG_ 983 IDB_a116_VCFRONTsensorsDLC "IDB ECU: a116 VCFRON tsensors DLC";
CM_ SG_ 983 IDB_a117_VCLEFTepbmStatusDLC "IDB ECU: a117 VCLEF tepbm status DLC";
CM_ SG_ 983 IDB_a118_VCLEFTepbmStatusCounter "IDB ECU: a118 VCLEF tepbm status counter";
CM_ SG_ 983 IDB_a119_VCLEFTepbmStatusChecksu "IDB ECU: a119 VCLEF tepbm status checksum";
CM_ SG_ 983 IDB_a120_EPAS3Pinvalid "IDB ECU: a120 EPAS3 pinvalid";
CM_ SG_ 983 IDB_a121_dynoModeActive "IDB ECU: a121 dyno mode active";
CM_ SG_ 983 IDB_a122_DIFtorqueCommandInvalid "IDB ECU: a122 DI ftorque command invalid";
CM_ SG_ 983 IDB_a123_DIRtorqueCommandInvalid "IDB ECU: a123 DI rtorque command invalid";
CM_ SG_ 983 IDB_a124_VCFRONTtempInvalid "IDB ECU: a124 VCFRON ttemp invalid";
CM_ SG_ 983 IDB_a125_PMvdcCmdStateInvalid "IDB ECU: a125 p mvdc cmd state invalid";
CM_ SG_ 983 IDB_a126_DItorqueRequestInvalid "IDB ECU: a126 d itorque request invalid";
CM_ SG_ 983 IDB_a127_brakeFluidLevelInvalid "IDB ECU: a127 brake fluid level invalid";
CM_ SG_ 983 IDB_a128_largeAirVolume "IDB ECU: a128 large air volume";
CM_ SG_ 983 IDB_a129_RCUinputRodStrokeInvali "IDB ECU: a129 RC uinput rod stroke invalid";
CM_ SG_ 983 IDB_a130_DIfullTorqueRequestInva "IDB ECU: a130 d ifull torque request invalid";
CM_ SG_ 983 IDB_a131_cbcFaulted "IDB ECU: a131 cbc faulted";
CM_ SG_ 983 IDB_a132_RCUinputRodStrokeQFInva "IDB ECU: a132 RC uinput rod stroke QF invalid";
CM_ SG_ 983 IDB_a133_DIbrakeCommandDLC "IDB ECU: a133 d ibrake command DLC";
CM_ SG_ 983 IDB_a134_DIbrakeCommandCounter "IDB ECU: a134 d ibrake command counter";
CM_ SG_ 983 IDB_a135_DIbrakeCommandChecksum "IDB ECU: a135 d ibrake command checksum";
CM_ SG_ 983 IDB_a136_RCUptsCalMissing "IDB ECU: a136 RC upts cal missing";
CM_ SG_ 983 IDB_a137_VCLEFTcdpRequestInvalid "IDB ECU: a137 VCLEF tcdp request invalid";
CM_ SG_ 983 IDB_a138_DIbrakeTorqueCommandAnd "IDB ECU: a138 d ibrake torque command and flag mismatch";
CM_ SG_ 983 IDB_a139_DIbrakeTorqueCommandFul "IDB ECU: a139 d ibrake torque command full SNA";
CM_ SG_ 983 IDB_a140_PMbrakePedalCmdQFInvali "IDB ECU: a140 p mbrake pedal cmd QF invalid";
CM_ SG_ 983 IDB_a141_DIbrakeTorqueCommandFul "IDB ECU: a141 d ibrake torque command full too low";
CM_ SG_ 983 IDB_a142_PMebrCmdStateInvalid "IDB ECU: a142 p mebr cmd state invalid";
CM_ SG_ 983 IDB_a143_factoryModeActive "IDB ECU: a143 factory mode active";
CM_ SG_ 983 IDB_a144_hydraulicPushthroughAct "IDB ECU: a144 hydraulic pushthrough active";
CM_ SG_ 983 IDB_a145_DASredundantBrakingCont "IDB ECU: a145 DA sredundant braking control DLC";
CM_ SG_ 983 IDB_a146_DASredundantBrakingCont "IDB ECU: a146 DA sredundant braking control counter";
CM_ SG_ 983 IDB_a147_DASredundantBrakingCont "IDB ECU: a147 DA sredundant braking control checksum";
CM_ SG_ 983 IDB_a148_DASbrakeTorqueCommandIn "IDB ECU: a148 DA sbrake torque command invalid";
CM_ SG_ 983 IDB_a149_DASmiaBrakeTorqueComman "IDB ECU: a149 DA smia brake torque command invalid";
CM_ SG_ 983 IDB_a150_DIlocStatus2DLC "IDB ECU: a150 d iloc status2 DLC";
CM_ SG_ 983 IDB_a151_DIlocStatus2Counter "IDB ECU: a151 d iloc status2 counter";
CM_ SG_ 983 IDB_a152_DIlocStatus2Checksum "IDB ECU: a152 d iloc status2 checksum";
CM_ SG_ 983 IDB_a155_PMlocStateDLC "IDB ECU: a155 p mloc state DLC";
CM_ SG_ 983 IDB_a156_PMlocStateChecksum "IDB ECU: a156 p mloc state checksum";
CM_ SG_ 983 IDB_a157_PMlocStateCounter "IDB ECU: a157 p mloc state counter";
CM_ BO_ 828 "IDB ECU message: info";
CM_ SG_ 828 IDB_infoIndex "IDB ECU: info index";
CM_ SG_ 828 IDB_infoPcbaID "IDB ECU: info pcba ID";
CM_ SG_ 828 IDB_infoAssemblyID "IDB ECU: info assembly ID";
CM_ SG_ 828 IDB_infoUsageID "IDB ECU: info usage ID";
CM_ SG_ 828 IDB_infoSubUsageID "IDB ECU: info sub usage ID";
CM_ BO_ 1429 "Occupant classification system message: alert log";
CM_ SG_ 1429 OCS1P_alertID "Occupant classification system: alert ID";
CM_ SG_ 1429 OCS1P_alertState "Occupant classification system: alert state";
CM_ SG_ 1429 OCS1P_a121_sandwichFreq "Occupant classification system: a121 sandwich freq";
CM_ SG_ 1429 OCS1P_a122_sandwichFreq "Occupant classification system: a122 sandwich freq";
CM_ SG_ 1429 OCS1P_a123_sandwichFreq "Occupant classification system: a123 sandwich freq";
CM_ SG_ 1429 OCS1P_a124_cushionSelfFreq "Occupant classification system: a124 cushion self freq";
CM_ SG_ 1429 OCS1P_a125_cushionSelfFreq "Occupant classification system: a125 cushion self freq";
CM_ SG_ 1429 OCS1P_a126_cushionSelfFreq "Occupant classification system: a126 cushion self freq";
CM_ SG_ 1429 OCS1P_a127_seatbackSelfFreq "Occupant classification system: a127 seatback self freq";
CM_ SG_ 1429 OCS1P_a128_seatbackSelfFreq "Occupant classification system: a128 seatback self freq";
CM_ SG_ 1429 OCS1P_a129_seatbackSelfFreq "Occupant classification system: a129 seatback self freq";
CM_ SG_ 1429 OCS1P_a130_sandwichNoCalib "Occupant classification system: a130 sandwich no calib";
CM_ SG_ 1429 OCS1P_a131_cushionSelfNoCalib "Occupant classification system: a131 cushion self no calib";
CM_ SG_ 1429 OCS1P_a132_seatbackSelfNoCalib "Occupant classification system: a132 seatback self no calib";
CM_ SG_ 1429 OCS1P_a133_sandwichBadCalib "Occupant classification system: a133 sandwich bad calib";
CM_ SG_ 1429 OCS1P_a134_uninitializedCalib "Occupant classification system: a134 uninitialized calib";
CM_ SG_ 1429 OCS1P_a135_tempNoCalib "Occupant classification system: a135 temp no calib";
CM_ SG_ 1429 OCS1P_a140_tempInvalidCalib "Occupant classification system: a140 temp invalid calib";
CM_ SG_ 1429 OCS1P_a141_humidityInvalidCalib "Occupant classification system: a141 humidity invalid calib";
CM_ SG_ 1429 OCS1P_a142_tempHumidityInvalid "Occupant classification system: a142 temp humidity invalid";
CM_ SG_ 1429 OCS1P_a143_mismatchPassAirbag "Occupant classification system: a143 mismatch pass airbag";
CM_ SG_ 1429 OCS1P_a144_mismatchCarRegion "Occupant classification system: a144 mismatch car region";
BA_DEF_ BO_ "GenMsgCycleTime" INT 0 3600000;
BA_DEF_ BO_ "GenMsgSendType" ENUM "Cyclic","NotUsed","NotUsed","NotUsed","NotUsed","NotUsed","NotUsed","IfActive","NoMsgSendType","NotUsed";
BA_DEF_ BO_ "VFrameFormat" ENUM "StandardCAN","ExtendedCAN","reserved","J1939PG","reserved","reserved","reserved","reserved","reserved","reserved","reserved","reserved","reserved","reserved","StandardCAN_FD","ExtendedCAN_FD";
BA_DEF_ BO_ "CANFD_BRS" ENUM "0","1";
BA_DEF_ SG_ "GenSigSNA" STRING;
BA_DEF_ SG_ "SystemSignalLongSymbol" STRING;
BA_DEF_ SG_ "Confidence" ENUM "validated","plausible","layout-only","contradicted";
BA_DEF_DEF_ "GenMsgCycleTime" 0;
BA_DEF_DEF_ "GenMsgSendType" "NoMsgSendType";
BA_DEF_DEF_ "VFrameFormat" "StandardCAN";
BA_DEF_DEF_ "CANFD_BRS" "1";
BA_DEF_DEF_ "GenSigSNA" "";
BA_DEF_DEF_ "SystemSignalLongSymbol" "";
BA_DEF_DEF_ "Confidence" "layout-only";
BA_ "GenMsgCycleTime" BO_ 62 100;
BA_ "GenMsgSendType" BO_ 62 0;
BA_ "GenMsgCycleTime" BO_ 838 1000;
BA_ "GenMsgSendType" BO_ 838 0;
BA_ "GenMsgCycleTime" BO_ 904 1000;
BA_ "GenMsgSendType" BO_ 904 0;
BA_ "GenMsgCycleTime" BO_ 792 100;
BA_ "GenMsgSendType" BO_ 792 0;
BA_ "GenMsgCycleTime" BO_ 1080 100;
BA_ "GenMsgSendType" BO_ 1080 0;
BA_ "GenMsgCycleTime" BO_ 1376 1000;
BA_ "GenMsgSendType" BO_ 1376 0;
BA_ "GenMsgCycleTime" BO_ 1656 100;
BA_ "GenMsgSendType" BO_ 1656 0;
BA_ "GenMsgCycleTime" BO_ 2033 2000;
BA_ "GenMsgSendType" BO_ 2033 0;
BA_ "GenMsgCycleTime" BO_ 2026 1000;
BA_ "GenMsgSendType" BO_ 2026 0;
BA_ "GenMsgCycleTime" BO_ 60 2000;
BA_ "GenMsgSendType" BO_ 60 0;
BA_ "GenMsgCycleTime" BO_ 1370 250;
BA_ "GenMsgSendType" BO_ 1370 0;
BA_ "GenMsgCycleTime" BO_ 840 1000;
BA_ "GenMsgSendType" BO_ 840 0;
BA_ "GenMsgCycleTime" BO_ 1005 1000;
BA_ "GenMsgSendType" BO_ 1005 0;
BA_ "GenMsgCycleTime" BO_ 1112 100;
BA_ "GenMsgSendType" BO_ 1112 0;
BA_ "GenMsgCycleTime" BO_ 983 1000;
BA_ "GenMsgSendType" BO_ 983 0;
BA_ "GenMsgCycleTime" BO_ 828 10000;
BA_ "GenMsgSendType" BO_ 828 0;
BA_ "Confidence" SG_ 1384 GTW_alertID 1;
BA_ "Confidence" SG_ 1384 GTW_alertState 1;
BA_ "Confidence" SG_ 1384 GTW_a049_headerError 1;
BA_ "Confidence" SG_ 1384 GTW_a062_bmpWatchdogReason 1;
BA_ "Confidence" SG_ 1384 GTW_a063_VEH_faultConfinement 1;
BA_ "Confidence" SG_ 1384 GTW_a064_CH_faultConfinement 1;
BA_ "Confidence" SG_ 1384 GTW_a065_PARTY_faultConfinement 1;
BA_ "Confidence" SG_ 1384 GTW_a073_SOCResetRequestor 1;
BA_ "Confidence" SG_ 1384 GTW_a077_bmpPmicErrorType 1;
BA_ "Confidence" SG_ 1384 GTW_a122_BDY_faultConfinement 1;
BA_ "Confidence" SG_ 1384 GTW_a261_failureReason 1;
BA_ "Confidence" SG_ 1384 GTW_a277_mitigationFailureReason 1;
BA_ "Confidence" SG_ 1384 GTW_a279_failureReason 1;
BA_ "Confidence" SG_ 1384 GTW_a317_status 1;
BA_ "Confidence" SG_ 1384 GTW_a317_errorCode 1;
BA_ "Confidence" SG_ 62 GTW_matrixIndex 1;
BA_ "SystemSignalLongSymbol" SG_ 62 GTW_w016_BLEEPCENTERversionMisma "GTW_w016_BLEEPCENTERversionMismatch";
BA_ "SystemSignalLongSymbol" SG_ 62 GTW_w093_sdCardInvReqOverflowBas "GTW_w093_sdCardInvReqOverflowBase";
BA_ "SystemSignalLongSymbol" SG_ 62 GTW_w094_sdCardInvReqOverflowCou "GTW_w094_sdCardInvReqOverflowCount";
BA_ "SystemSignalLongSymbol" SG_ 62 GTW_w104_sdCardDriverArgCorrupte "GTW_w104_sdCardDriverArgCorrupted";
BA_ "SystemSignalLongSymbol" SG_ 62 GTW_w106_BLEEPLEFTversionMismatc "GTW_w106_BLEEPLEFTversionMismatch";
BA_ "SystemSignalLongSymbol" SG_ 62 GTW_w107_BLEEPRIGHTversionMismat "GTW_w107_BLEEPRIGHTversionMismatch";
BA_ "SystemSignalLongSymbol" SG_ 62 GTW_w108_BLEEPREARversionMismatc "GTW_w108_BLEEPREARversionMismatch";
BA_ "SystemSignalLongSymbol" SG_ 62 GTW_w117_unexpectedDestructiveRe "GTW_w117_unexpectedDestructiveResetStatus";
BA_ "SystemSignalLongSymbol" SG_ 62 GTW_w118_unexpectedFunctionalRes "GTW_w118_unexpectedFunctionalResetStatus";
BA_ "SystemSignalLongSymbol" SG_ 62 GTW_w146_performancePackageMisma "GTW_w146_performancePackageMismatch";
BA_ "SystemSignalLongSymbol" SG_ 62 GTW_w227_DISPTOUCHversionMismatc "GTW_w227_DISPTOUCHversionMismatch";
BA_ "SystemSignalLongSymbol" SG_ 62 GTW_w229_displaySoftsetConnectio "GTW_w229_displaySoftsetConnection";
BA_ "SystemSignalLongSymbol" SG_ 62 GTW_w273_BLEEPREARLEFTversionMis "GTW_w273_BLEEPREARLEFTversionMismatch";
BA_ "SystemSignalLongSymbol" SG_ 62 GTW_w274_BLEEPREARRIGHTversionMi "GTW_w274_BLEEPREARRIGHTversionMismatch";
BA_ "SystemSignalLongSymbol" SG_ 62 GTW_w277_NonRevCDrMOSMitigationF "GTW_w277_NonRevCDrMOSMitigationFailed";
BA_ "SystemSignalLongSymbol" SG_ 62 GTW_w282_tcuPhyConfigurationFail "GTW_w282_tcuPhyConfigurationFailed";
BA_ "SystemSignalLongSymbol" SG_ 62 GTW_w311_canLogQueueFullBeforeFs "GTW_w311_canLogQueueFullBeforeFsInit";
BA_ "SystemSignalLongSymbol" SG_ 62 GTW_w317_sdCardChkdskRepairFaile "GTW_w317_sdCardChkdskRepairFailed";
BA_ "SystemSignalLongSymbol" SG_ 62 GTW_w322_gestureUnrecognizedFrom "GTW_w322_gestureUnrecognizedFromMoving";
BA_ "SystemSignalLongSymbol" SG_ 62 GTW_w360_RGBDOORFLversionMismatc "GTW_w360_RGBDOORFLversionMismatch";
BA_ "SystemSignalLongSymbol" SG_ 62 GTW_w361_RGBDOORRLversionMismatc "GTW_w361_RGBDOORRLversionMismatch";
BA_ "SystemSignalLongSymbol" SG_ 62 GTW_w362_RGBDOORFRversionMismatc "GTW_w362_RGBDOORFRversionMismatch";
BA_ "SystemSignalLongSymbol" SG_ 62 GTW_w363_RGBDOORRRversionMismatc "GTW_w363_RGBDOORRRversionMismatch";
BA_ "SystemSignalLongSymbol" SG_ 62 GTW_w364_BLEEPCRADLEversionMisma "GTW_w364_BLEEPCRADLEversionMismatch";
BA_ "SystemSignalLongSymbol" SG_ 62 GTW_w420_unexpectedCanMessageLen "GTW_w420_unexpectedCanMessageLength";
BA_ "SystemSignalLongSymbol" SG_ 62 GTW_w422_ethSwitchSevereCongesti "GTW_w422_ethSwitchSevereCongestionWatchdog";
BA_ "SystemSignalLongSymbol" SG_ 62 GTW_w427_DISPBRIDGEversionMismat "GTW_w427_DISPBRIDGEversionMismatch";
BA_ "SystemSignalLongSymbol" SG_ 62 GTW_w428_LUMBAR32LversionMismatc "GTW_w428_LUMBAR32LversionMismatch";
BA_ "SystemSignalLongSymbol" SG_ 62 GTW_w429_LUMBAR32RversionMismatc "GTW_w429_LUMBAR32RversionMismatch";
BA_ "SystemSignalLongSymbol" SG_ 62 GTW_w437_softFlowControlNotRunni "GTW_w437_softFlowControlNotRunning";
BA_ "SystemSignalLongSymbol" SG_ 62 GTW_w450_unexpectedAutopilotCont "GTW_w450_unexpectedAutopilotControlCanMessage";
BA_ "SystemSignalLongSymbol" SG_ 62 GTW_w455_hrlDumpPageOwnershipErr "GTW_w455_hrlDumpPageOwnershipError";
BA_ "SystemSignalLongSymbol" SG_ 62 GTW_w456_hrlStateMachinePageOwne "GTW_w456_hrlStateMachinePageOwnershipError";
BA_ "Confidence" SG_ 838 GTW_autopilotOverrideState 0;
BA_ "Confidence" SG_ 838 GTW_autopilotConfig 0;
BA_ "Confidence" SG_ 838 GTW_autopilotOverrideConfig 0;
BA_ "Confidence" SG_ 838 GTW_autopilotConfigSource 0;
BA_ "Confidence" SG_ 838 GTW_autopilotOverrideExpireTime 0;
BA_ "Confidence" SG_ 904 GTW_VEH_canBusActivity 0;
BA_ "Confidence" SG_ 904 GTW_PARTY_canBusActivity 0;
BA_ "Confidence" SG_ 904 GTW_CH_canBusActivity 0;
BA_ "Confidence" SG_ 904 GTW_VEH_txWarning 0;
BA_ "Confidence" SG_ 904 GTW_PARTY_txWarning 0;
BA_ "Confidence" SG_ 904 GTW_CH_txWarning 0;
BA_ "Confidence" SG_ 904 GTW_VEH_rxWarning 0;
BA_ "Confidence" SG_ 904 GTW_PARTY_rxWarning 0;
BA_ "Confidence" SG_ 904 GTW_CH_rxWarning 0;
BA_ "Confidence" SG_ 904 GTW_VEH_faultConfinement 0;
BA_ "Confidence" SG_ 904 GTW_PARTY_faultConfinement 0;
BA_ "Confidence" SG_ 904 GTW_CH_faultConfinement 0;
BA_ "Confidence" SG_ 904 GTW_BDY_canBusActivity 0;
BA_ "Confidence" SG_ 904 GTW_BDY_txWarning 0;
BA_ "Confidence" SG_ 904 GTW_BDY_rxWarning 0;
BA_ "Confidence" SG_ 904 GTW_BDY_faultConfinement 0;
BA_ "Confidence" SG_ 792 GTW_factoryGated 1;
BA_ "Confidence" SG_ 1080 GTW_ethGotoSleep 0;
BA_ "Confidence" SG_ 1080 GTW_ethWakeUpBus 0;
BA_ "Confidence" SG_ 1080 GTW_vehBusAsleep 0;
BA_ "Confidence" SG_ 1080 GTW_ethHeartBeatCounter 0;
BA_ "Confidence" SG_ 1080 GTW_ethWakeUpReason 0;
BA_ "Confidence" SG_ 1376 GTW_OCS1Ppresent 1;
BA_ "Confidence" SG_ 1376 GTW_PCSpresent 1;
BA_ "Confidence" SG_ 1376 GTW_HVPpresent 1;
BA_ "Confidence" SG_ 1376 GTW_BMSpresent 1;
BA_ "Confidence" SG_ 1376 GTW_CPpresent 1;
BA_ "Confidence" SG_ 1376 GTW_RCMpresent 1;
BA_ "Confidence" SG_ 1376 GTW_SCCMpresent 1;
BA_ "Confidence" SG_ 1376 GTW_VCSECpresent 1;
BA_ "Confidence" SG_ 1376 GTW_EPAS3Ppresent 1;
BA_ "Confidence" SG_ 1376 GTW_EPBLpresent 1;
BA_ "Confidence" SG_ 1376 GTW_EPBRpresent 1;
BA_ "Confidence" SG_ 1376 GTW_ESPpresent 1;
BA_ "Confidence" SG_ 1376 GTW_IBSTpresent 1;
BA_ "Confidence" SG_ 1376 GTW_PARKpresent 1;
BA_ "Confidence" SG_ 1376 GTW_RADCpresent 1;
BA_ "Confidence" SG_ 1376 GTW_TPMSpresent 1;
BA_ "Confidence" SG_ 1376 GTW_VCFRONTpresent 1;
BA_ "Confidence" SG_ 1376 GTW_VCLEFTpresent 1;
BA_ "Confidence" SG_ 1376 GTW_VCRIGHTpresent 1;
BA_ "Confidence" SG_ 1376 GTW_EPAS3Spresent 1;
BA_ "Confidence" SG_ 1376 GTW_CMPpresent 1;
BA_ "Confidence" SG_ 1376 GTW_DASpresent 1;
BA_ "Confidence" SG_ 1376 GTW_PTCpresent 1;
BA_ "Confidence" SG_ 1376 GTW_SWCpresent 1;
BA_ "Confidence" SG_ 1376 GTW_PMRpresent 1;
BA_ "Confidence" SG_ 1376 GTW_PMFpresent 1;
BA_ "Confidence" SG_ 1376 GTW_DIRpresent 1;
BA_ "Confidence" SG_ 1376 GTW_DIFpresent 1;
BA_ "Confidence" SG_ 1656 GTW_gearControlChecksum 0;
BA_ "Confidence" SG_ 1656 GTW_gearControlCounter 0;
BA_ "Confidence" SG_ 1656 GTW_gearShiftRequest 0;
BA_ "GenSigSNA" SG_ 1656 GTW_gearShiftRequest "0";
BA_ "Confidence" SG_ 1656 GTW_osdActive 0;
BA_ "Confidence" SG_ 1656 GTW_primaryGearControlStatus 0;
BA_ "Confidence" SG_ 1656 GTW_gearStripEnable 0;
BA_ "Confidence" SG_ 1656 GTW_showNeutralButton 0;
BA_ "Confidence" SG_ 1656 GTW_showAutoParkButton 0;
BA_ "Confidence" SG_ 1656 GTW_autoParkRequest 0;
BA_ "Confidence" SG_ 1656 GTW_smartShiftStatus 0;
BA_ "GenSigSNA" SG_ 1656 GTW_smartShiftStatus "0";
BA_ "Confidence" SG_ 1656 GTW_processingRDgestures 0;
BA_ "Confidence" SG_ 1656 GTW_processingTapPgestures 0;
BA_ "Confidence" SG_ 1656 GTW_gearStripChangeReason 0;
BA_ "GenSigSNA" SG_ 1656 GTW_gearStripChangeReason "0";
BA_ "Confidence" SG_ 1656 GTW_touchActive 0;
BA_ "Confidence" SG_ 1656 GTW_steamOff 0;
BA_ "Confidence" SG_ 1656 GTW_screenPCBTemperature 1;
BA_ "GenSigSNA" SG_ 1656 GTW_screenPCBTemperature "2047";
BA_ "Confidence" SG_ 2033 GTW_hrlIndex 1;
BA_ "Confidence" SG_ 2033 GTW_hrlSdCardSizeGB 0;
BA_ "GenSigSNA" SG_ 2033 GTW_hrlSdCardSizeGB "0";
BA_ "Confidence" SG_ 2033 GTW_hrlState 0;
BA_ "Confidence" SG_ 2033 GTW_hrlTriggerDuration 1;
BA_ "Confidence" SG_ 2033 GTW_hrlTriggerType 0;
BA_ "Confidence" SG_ 2033 GTW_hrlTriggerId 1;
BA_ "Confidence" SG_ 2026 GTW_hrlEventStartEpoch 1;
BA_ "Confidence" SG_ 2026 GTW_hrlEventEndEpoch 1;
BA_ "Confidence" SG_ 60 GTW_infoIndex 1;
BA_ "Confidence" SG_ 60 GTW_buildType 0;
BA_ "Confidence" SG_ 60 GTW_hardwareId 0;
BA_ "Confidence" SG_ 60 GTW_platformType 0;
BA_ "Confidence" SG_ 60 GTW_appCrc 0;
BA_ "Confidence" SG_ 60 GTW_applicationGitHash 0;
BA_ "Confidence" SG_ 60 GTW_bootGitHash 0;
BA_ "Confidence" SG_ 1370 GTW_mismatchFaultIndex 1;
BA_ "Confidence" SG_ 1370 GTW_mismatchFaultChecksum 0;
BA_ "Confidence" SG_ 1370 GTW_mismatchFaultCounter 0;
BA_ "Confidence" SG_ 1370 GTW_GTWmismatchFault 0;
BA_ "Confidence" SG_ 1370 GTW_BMSmismatchFault 0;
BA_ "Confidence" SG_ 1370 GTW_APSmismatchFault 0;
BA_ "Confidence" SG_ 1370 GTW_BLEEPCENTERmismatchFault 0;
BA_ "Confidence" SG_ 1370 GTW_BLEEPLEFTmismatchFault 0;
BA_ "Confidence" SG_ 1370 GTW_BLEEPREARmismatchFault 0;
BA_ "Confidence" SG_ 1370 GTW_BLEEPRIGHTmismatchFault 0;
BA_ "Confidence" SG_ 1370 GTW_CBCmismatchFault 0;
BA_ "Confidence" SG_ 1370 GTW_CMPmismatchFault 0;
BA_ "Confidence" SG_ 1370 GTW_CPmismatchFault 0;
BA_ "Confidence" SG_ 1370 GTW_DIFmismatchFault 0;
BA_ "Confidence" SG_ 1370 GTW_DIRmismatchFault 0;
BA_ "Confidence" SG_ 1370 GTW_EPAS3PmismatchFault 0;
BA_ "Confidence" SG_ 1370 GTW_EPAS3SmismatchFault 0;
BA_ "Confidence" SG_ 1370 GTW_EPBLmismatchFault 0;
BA_ "Confidence" SG_ 1370 GTW_EPBRmismatchFault 0;
BA_ "Confidence" SG_ 1370 GTW_ESPCALmismatchFault 0;
BA_ "Confidence" SG_ 1370 GTW_ESPmismatchFault 0;
BA_ "Confidence" SG_ 1370 GTW_HCM3LmismatchFault 0;
BA_ "Confidence" SG_ 1370 GTW_HCM3RmismatchFault 0;
BA_ "Confidence" SG_ 1370 GTW_HCMLmismatchFault 0;
BA_ "Confidence" SG_ 1370 GTW_HCMRmismatchFault 0;
BA_ "Confidence" SG_ 1370 GTW_HVPmismatchFault 0;
BA_ "Confidence" SG_ 1370 GTW_IBSTCALmismatchFault 0;
BA_ "Confidence" SG_ 1370 GTW_IBSTmismatchFault 0;
BA_ "Confidence" SG_ 1370 GTW_LVBMSmismatchFault 0;
BA_ "Confidence" SG_ 1370 GTW_OCS1PmismatchFault 0;
BA_ "Confidence" SG_ 1370 GTW_OPCFmismatchFault 0;
BA_ "Confidence" SG_ 1370 GTW_OPCRmismatchFault 0;
BA_ "Confidence" SG_ 1370 GTW_PARKmismatchFault 0;
BA_ "Confidence" SG_ 1370 GTW_PCSCPU2mismatchFault 0;
BA_ "Confidence" SG_ 1370 GTW_PCSmismatchFault 0;
BA_ "Confidence" SG_ 1370 GTW_PMFmismatchFault 0;
BA_ "Confidence" SG_ 1370 GTW_PMRmismatchFault 0;
BA_ "Confidence" SG_ 1370 GTW_PTCmismatchFault 0;
BA_ "Confidence" SG_ 1370 GTW_RCMCALmismatchFault 0;
BA_ "Confidence" SG_ 1370 GTW_RCMmismatchFault 0;
BA_ "Confidence" SG_ 1370 GTW_SCCMmismatchFault 0;
BA_ "Confidence" SG_ 1370 GTW_SDCRmismatchFault 0;
BA_ "Confidence" SG_ 1370 GTW_SWCmismatchFault 0;
BA_ "Confidence" SG_ 1370 GTW_THSmismatchFault 0;
BA_ "Confidence" SG_ 1370 GTW_VCFRONTmismatchFault 0;
BA_ "Confidence" SG_ 1370 GTW_VCLEFTmismatchFault 0;
BA_ "Confidence" SG_ 1370 GTW_VCRIGHTmismatchFault 0;
BA_ "Confidence" SG_ 1370 GTW_VCSECmismatchFault 0;
BA_ "Confidence" SG_ 1370 GTW_PMmismatchFault 0;
BA_ "Confidence" SG_ 840 GTW_vehicleVersionMatchStatus 0;
BA_ "Confidence" SG_ 840 GTW_hwtype 0;
BA_ "GenSigSNA" SG_ 840 GTW_hwtype "0";
BA_ "Confidence" SG_ 840 GTW_jcanProductName 0;
BA_ "GenSigSNA" SG_ 840 GTW_jcanProductName "0";
BA_ "Confidence" SG_ 840 GTW_uptimeSeconds 1;
BA_ "Confidence" SG_ 840 GTW_boardRevision 0;
BA_ "Confidence" SG_ 840 GTW_touchcoreOsType 0;
BA_ "Confidence" SG_ 840 GTW_sentryModeState 0;
BA_ "GenSigSNA" SG_ 840 GTW_sentryModeState "6";
BA_ "Confidence" SG_ 840 GTW_secureBootEnabled 0;
BA_ "Confidence" SG_ 840 GTW_socSleepType 0;
BA_ "GenSigSNA" SG_ 840 GTW_socSleepType "0";
BA_ "Confidence" SG_ 840 GTW_resetType 0;
BA_ "GenSigSNA" SG_ 840 GTW_resetType "0";
BA_ "Confidence" SG_ 1005 GTW_peripheralConfirmedUpdateNee 1;
BA_ "SystemSignalLongSymbol" SG_ 1005 GTW_peripheralConfirmedUpdateNee "GTW_peripheralConfirmedUpdateNeeded";
BA_ "Confidence" SG_ 1005 GTW_ocuFailed 0;
BA_ "Confidence" SG_ 1005 GTW_ecuUpdateStarted 0;
BA_ "Confidence" SG_ 1005 GTW_updateStarted 1;
BA_ "Confidence" SG_ 1112 GTW_nmGoingToSleep 0;
BA_ "Confidence" SG_ 1112 GTW_nmWakeUpBus 0;
BA_ "Confidence" SG_ 1112 GTW_chBusAsleep 0;
BA_ "Confidence" SG_ 1112 GTW_ethBusAsleep 0;
BA_ "Confidence" SG_ 1112 GTW_nmKeepAwakeReason 0;
BA_ "GenSigSNA" SG_ 1112 GTW_nmKeepAwakeReason "0";
BA_ "Confidence" SG_ 1112 GTW_nmWakeUpReason 0;
BA_ "Confidence" SG_ 1112 GTW_ethKeepAwakeReason 0;
BA_ "GenSigSNA" SG_ 1112 GTW_ethKeepAwakeReason "0";
BA_ "Confidence" SG_ 1112 GTW_nmDebugWakeUp 0;
BA_ "Confidence" SG_ 1112 GTW_OTAKeepAwake 0;
BA_ "Confidence" SG_ 1112 GTW_smsPokeReceived 0;
BA_ "Confidence" SG_ 1112 GTW_bdyBusAsleep 0;
BA_ "Confidence" SG_ 1470 IDB_alertID 1;
BA_ "Confidence" SG_ 1470 IDB_alertState 1;
BA_ "Confidence" SG_ 1470 IDB_a014_wheelSpeedSensorFreq 1;
BA_ "Confidence" SG_ 1470 IDB_a014_wheelSpeedSensorPhase 1;
BA_ "Confidence" SG_ 1470 IDB_a014_wheelSpeedSensorMisinst 1;
BA_ "SystemSignalLongSymbol" SG_ 1470 IDB_a014_wheelSpeedSensorMisinst "IDB_a014_wheelSpeedSensorMisinstallation";
BA_ "Confidence" SG_ 1470 IDB_a014_wheelSpeedSensorWrongEx 1;
BA_ "SystemSignalLongSymbol" SG_ 1470 IDB_a014_wheelSpeedSensorWrongEx "IDB_a014_wheelSpeedSensorWrongExciter";
BA_ "Confidence" SG_ 1470 IDB_a014_wheelSpeedSensorSpeedJu 1;
BA_ "SystemSignalLongSymbol" SG_ 1470 IDB_a014_wheelSpeedSensorSpeedJu "IDB_a014_wheelSpeedSensorSpeedJumpMinus";
BA_ "Confidence" SG_ 1470 IDB_a014_wheelSpeedSensorSp_0001 1;
BA_ "SystemSignalLongSymbol" SG_ 1470 IDB_a014_wheelSpeedSensorSp_0001 "IDB_a014_wheelSpeedSensorSpeedJumpPlus";
BA_ "Confidence" SG_ 1470 IDB_a014_wheelSpeedSensorAirGap 1;
BA_ "Confidence" SG_ 1470 IDB_a014_wheelSpeedSensorBIST 1;
BA_ "Confidence" SG_ 1470 IDB_a014_wheelSpeedSensorLeakage 1;
BA_ "SystemSignalLongSymbol" SG_ 1470 IDB_a014_wheelSpeedSensorLeakage "IDB_a014_wheelSpeedSensorLeakageCur";
BA_ "Confidence" SG_ 1470 IDB_a014_wheelSpeedSensorOverTem 1;
BA_ "SystemSignalLongSymbol" SG_ 1470 IDB_a014_wheelSpeedSensorOverTem "IDB_a014_wheelSpeedSensorOverTemp";
BA_ "Confidence" SG_ 1470 IDB_a014_wheelSpeedSensorSh_0001 1;
BA_ "SystemSignalLongSymbol" SG_ 1470 IDB_a014_wheelSpeedSensorSh_0001 "IDB_a014_wheelSpeedSensorShortToGnd";
BA_ "Confidence" SG_ 1470 IDB_a014_wheelSpeedSensorShortTo 1;
BA_ "SystemSignalLongSymbol" SG_ 1470 IDB_a014_wheelSpeedSensorShortTo "IDB_a014_wheelSpeedSensorShortToBat";
BA_ "Confidence" SG_ 1470 IDB_a014_wheelSpeedSensorOpen 1;
BA_ "Confidence" SG_ 1470 IDB_a015_wheelSpeedSensorFreq 1;
BA_ "Confidence" SG_ 1470 IDB_a015_wheelSpeedSensorPhase 1;
BA_ "Confidence" SG_ 1470 IDB_a015_wheelSpeedSensorMisinst 1;
BA_ "SystemSignalLongSymbol" SG_ 1470 IDB_a015_wheelSpeedSensorMisinst "IDB_a015_wheelSpeedSensorMisinstallation";
BA_ "Confidence" SG_ 1470 IDB_a015_wheelSpeedSensorWrongEx 1;
BA_ "SystemSignalLongSymbol" SG_ 1470 IDB_a015_wheelSpeedSensorWrongEx "IDB_a015_wheelSpeedSensorWrongExciter";
BA_ "Confidence" SG_ 1470 IDB_a015_wheelSpeedSensorSpeedJu 1;
BA_ "SystemSignalLongSymbol" SG_ 1470 IDB_a015_wheelSpeedSensorSpeedJu "IDB_a015_wheelSpeedSensorSpeedJumpMinus";
BA_ "Confidence" SG_ 1470 IDB_a015_wheelSpeedSensorSp_0001 1;
BA_ "SystemSignalLongSymbol" SG_ 1470 IDB_a015_wheelSpeedSensorSp_0001 "IDB_a015_wheelSpeedSensorSpeedJumpPlus";
BA_ "Confidence" SG_ 1470 IDB_a015_wheelSpeedSensorAirGap 1;
BA_ "Confidence" SG_ 1470 IDB_a015_wheelSpeedSensorBIST 1;
BA_ "Confidence" SG_ 1470 IDB_a015_wheelSpeedSensorLeakage 1;
BA_ "SystemSignalLongSymbol" SG_ 1470 IDB_a015_wheelSpeedSensorLeakage "IDB_a015_wheelSpeedSensorLeakageCur";
BA_ "Confidence" SG_ 1470 IDB_a015_wheelSpeedSensorOverTem 1;
BA_ "SystemSignalLongSymbol" SG_ 1470 IDB_a015_wheelSpeedSensorOverTem "IDB_a015_wheelSpeedSensorOverTemp";
BA_ "Confidence" SG_ 1470 IDB_a015_wheelSpeedSensorSh_0001 1;
BA_ "SystemSignalLongSymbol" SG_ 1470 IDB_a015_wheelSpeedSensorSh_0001 "IDB_a015_wheelSpeedSensorShortToGnd";
BA_ "Confidence" SG_ 1470 IDB_a015_wheelSpeedSensorShortTo 1;
BA_ "SystemSignalLongSymbol" SG_ 1470 IDB_a015_wheelSpeedSensorShortTo "IDB_a015_wheelSpeedSensorShortToBat";
BA_ "Confidence" SG_ 1470 IDB_a015_wheelSpeedSensorOpen 1;
BA_ "Confidence" SG_ 1470 IDB_a016_wheelSpeedSensorFreq 1;
BA_ "Confidence" SG_ 1470 IDB_a016_wheelSpeedSensorPhase 1;
BA_ "Confidence" SG_ 1470 IDB_a016_wheelSpeedSensorMisinst 1;
BA_ "SystemSignalLongSymbol" SG_ 1470 IDB_a016_wheelSpeedSensorMisinst "IDB_a016_wheelSpeedSensorMisinstallation";
BA_ "Confidence" SG_ 1470 IDB_a016_wheelSpeedSensorWrongEx 1;
BA_ "SystemSignalLongSymbol" SG_ 1470 IDB_a016_wheelSpeedSensorWrongEx "IDB_a016_wheelSpeedSensorWrongExciter";
BA_ "Confidence" SG_ 1470 IDB_a016_wheelSpeedSensorSpeedJu 1;
BA_ "SystemSignalLongSymbol" SG_ 1470 IDB_a016_wheelSpeedSensorSpeedJu "IDB_a016_wheelSpeedSensorSpeedJumpMinus";
BA_ "Confidence" SG_ 1470 IDB_a016_wheelSpeedSensorSp_0001 1;
BA_ "SystemSignalLongSymbol" SG_ 1470 IDB_a016_wheelSpeedSensorSp_0001 "IDB_a016_wheelSpeedSensorSpeedJumpPlus";
BA_ "Confidence" SG_ 1470 IDB_a016_wheelSpeedSensorAirGap 1;
BA_ "Confidence" SG_ 1470 IDB_a016_wheelSpeedSensorBIST 1;
BA_ "Confidence" SG_ 1470 IDB_a016_wheelSpeedSensorLeakage 1;
BA_ "SystemSignalLongSymbol" SG_ 1470 IDB_a016_wheelSpeedSensorLeakage "IDB_a016_wheelSpeedSensorLeakageCur";
BA_ "Confidence" SG_ 1470 IDB_a016_wheelSpeedSensorOverTem 1;
BA_ "SystemSignalLongSymbol" SG_ 1470 IDB_a016_wheelSpeedSensorOverTem "IDB_a016_wheelSpeedSensorOverTemp";
BA_ "Confidence" SG_ 1470 IDB_a016_wheelSpeedSensorSh_0001 1;
BA_ "SystemSignalLongSymbol" SG_ 1470 IDB_a016_wheelSpeedSensorSh_0001 "IDB_a016_wheelSpeedSensorShortToGnd";
BA_ "Confidence" SG_ 1470 IDB_a016_wheelSpeedSensorShortTo 1;
BA_ "SystemSignalLongSymbol" SG_ 1470 IDB_a016_wheelSpeedSensorShortTo "IDB_a016_wheelSpeedSensorShortToBat";
BA_ "Confidence" SG_ 1470 IDB_a016_wheelSpeedSensorOpen 1;
BA_ "Confidence" SG_ 1470 IDB_a017_wheelSpeedSensorFreq 1;
BA_ "Confidence" SG_ 1470 IDB_a017_wheelSpeedSensorPhase 1;
BA_ "Confidence" SG_ 1470 IDB_a017_wheelSpeedSensorMisinst 1;
BA_ "SystemSignalLongSymbol" SG_ 1470 IDB_a017_wheelSpeedSensorMisinst "IDB_a017_wheelSpeedSensorMisinstallation";
BA_ "Confidence" SG_ 1470 IDB_a017_wheelSpeedSensorWrongEx 1;
BA_ "SystemSignalLongSymbol" SG_ 1470 IDB_a017_wheelSpeedSensorWrongEx "IDB_a017_wheelSpeedSensorWrongExciter";
BA_ "Confidence" SG_ 1470 IDB_a017_wheelSpeedSensorSpeedJu 1;
BA_ "SystemSignalLongSymbol" SG_ 1470 IDB_a017_wheelSpeedSensorSpeedJu "IDB_a017_wheelSpeedSensorSpeedJumpMinus";
BA_ "Confidence" SG_ 1470 IDB_a017_wheelSpeedSensorSp_0001 1;
BA_ "SystemSignalLongSymbol" SG_ 1470 IDB_a017_wheelSpeedSensorSp_0001 "IDB_a017_wheelSpeedSensorSpeedJumpPlus";
BA_ "Confidence" SG_ 1470 IDB_a017_wheelSpeedSensorAirGap 1;
BA_ "Confidence" SG_ 1470 IDB_a017_wheelSpeedSensorBIST 1;
BA_ "Confidence" SG_ 1470 IDB_a017_wheelSpeedSensorLeakage 1;
BA_ "SystemSignalLongSymbol" SG_ 1470 IDB_a017_wheelSpeedSensorLeakage "IDB_a017_wheelSpeedSensorLeakageCur";
BA_ "Confidence" SG_ 1470 IDB_a017_wheelSpeedSensorOverTem 1;
BA_ "SystemSignalLongSymbol" SG_ 1470 IDB_a017_wheelSpeedSensorOverTem "IDB_a017_wheelSpeedSensorOverTemp";
BA_ "Confidence" SG_ 1470 IDB_a017_wheelSpeedSensorSh_0001 1;
BA_ "SystemSignalLongSymbol" SG_ 1470 IDB_a017_wheelSpeedSensorSh_0001 "IDB_a017_wheelSpeedSensorShortToGnd";
BA_ "Confidence" SG_ 1470 IDB_a017_wheelSpeedSensorShortTo 1;
BA_ "SystemSignalLongSymbol" SG_ 1470 IDB_a017_wheelSpeedSensorShortTo "IDB_a017_wheelSpeedSensorShortToBat";
BA_ "Confidence" SG_ 1470 IDB_a017_wheelSpeedSensorOpen 1;
BA_ "Confidence" SG_ 1470 IDB_a020_canSignalValidity 1;
BA_ "Confidence" SG_ 1470 IDB_a020_signalValueCrosscheck 1;
BA_ "Confidence" SG_ 1470 IDB_a030_primaryExternalCircuitL 1;
BA_ "SystemSignalLongSymbol" SG_ 1470 IDB_a030_primaryExternalCircuitL "IDB_a030_primaryExternalCircuitLeakage";
BA_ "Confidence" SG_ 1470 IDB_a030_secondaryExternalCircui 1;
BA_ "SystemSignalLongSymbol" SG_ 1470 IDB_a030_secondaryExternalCircui "IDB_a030_secondaryExternalCircuitLeakage";
BA_ "Confidence" SG_ 1470 IDB_a030_primaryChamberInternalL 1;
BA_ "SystemSignalLongSymbol" SG_ 1470 IDB_a030_primaryChamberInternalL "IDB_a030_primaryChamberInternalLeakage";
BA_ "Confidence" SG_ 1470 IDB_a030_syncModeInternalLeakage 1;
BA_ "Confidence" SG_ 1470 IDB_a030_secondaryChamberInterna 1;
BA_ "SystemSignalLongSymbol" SG_ 1470 IDB_a030_secondaryChamberInterna "IDB_a030_secondaryChamberInternalLeakage";
BA_ "Confidence" SG_ 1470 IDB_a030_masterCylinderInternalL 1;
BA_ "SystemSignalLongSymbol" SG_ 1470 IDB_a030_masterCylinderInternalL "IDB_a030_masterCylinderInternalLeakage";
BA_ "Confidence" SG_ 1470 IDB_a060_validityOnChassisBus 1;
BA_ "Confidence" SG_ 1470 IDB_a060_validityOnPartyBus 1;
BA_ "Confidence" SG_ 1470 IDB_a061_validityOnChassisBus 1;
BA_ "Confidence" SG_ 1470 IDB_a061_validityOnPartyBus 1;
BA_ "Confidence" SG_ 1470 IDB_a063_validityOnChassisBus 1;
BA_ "Confidence" SG_ 1470 IDB_a063_validityOnPartyBus 1;
BA_ "Confidence" SG_ 1470 IDB_a064_validityOnChassisBus 1;
BA_ "Confidence" SG_ 1470 IDB_a064_validityOnPartyBus 1;
BA_ "Confidence" SG_ 1470 IDB_a065_validityOnChassisBus 1;
BA_ "Confidence" SG_ 1470 IDB_a065_validityOnPartyBus 1;
BA_ "Confidence" SG_ 1470 IDB_a106_qualifierValidity 1;
BA_ "Confidence" SG_ 1470 IDB_a106_signalNotAvailable 1;
BA_ "Confidence" SG_ 1470 IDB_a107_qualifierValidity 1;
BA_ "Confidence" SG_ 1470 IDB_a107_signalNotAvailable 1;
BA_ "Confidence" SG_ 1470 IDB_a112_qualifierValidity 1;
BA_ "Confidence" SG_ 1470 IDB_a112_signalNotAvailable 1;
BA_ "Confidence" SG_ 1470 IDB_a113_qualifierValidity 1;
BA_ "Confidence" SG_ 1470 IDB_a113_signalNotAvailable 1;
BA_ "Confidence" SG_ 1470 IDB_a114_qualifierValidity 1;
BA_ "Confidence" SG_ 1470 IDB_a114_signalNotAvailable 1;
BA_ "Confidence" SG_ 1470 IDB_a126_PMebrCmdStateValidity 1;
BA_ "Confidence" SG_ 1470 IDB_a126_PMstate2Validity 1;
BA_ "Confidence" SG_ 1470 IDB_a126_PMstate2Missing 1;
BA_ "Confidence" SG_ 1470 IDB_a126_DIchassisControlValidit 1;
BA_ "SystemSignalLongSymbol" SG_ 1470 IDB_a126_DIchassisControlValidit "IDB_a126_DIchassisControlValidity";
BA_ "Confidence" SG_ 1470 IDB_a126_DIchassisControlMissing 1;
BA_ "Confidence" SG_ 1470 IDB_a126_DIrequestActiveValidity 1;
BA_ "Confidence" SG_ 1470 IDB_a129_validityOnChassisBus 1;
BA_ "Confidence" SG_ 1470 IDB_a129_validityOnPartyBus 1;
BA_ "Confidence" SG_ 1470 IDB_a130_PMbrakePedalCmdQFValidi 1;
BA_ "SystemSignalLongSymbol" SG_ 1470 IDB_a130_PMbrakePedalCmdQFValidi "IDB_a130_PMbrakePedalCmdQFValidity";
BA_ "Confidence" SG_ 1470 IDB_a130_PMstate2Validity 1;
BA_ "Confidence" SG_ 1470 IDB_a130_PMstate2Missing 1;
BA_ "Confidence" SG_ 1470 IDB_a130_DIbrakeCommandValidity 1;
BA_ "Confidence" SG_ 1470 IDB_a130_DIbrakeCommandMissing 1;
BA_ "Confidence" SG_ 1470 IDB_a130_DIbrakeTorqueCommandFul 1;
BA_ "SystemSignalLongSymbol" SG_ 1470 IDB_a130_DIbrakeTorqueCommandFul "IDB_a130_DIbrakeTorqueCommandFullSNA";
BA_ "Confidence" SG_ 1470 IDB_a130_DIbrakeTorqueComma_0001 1;
BA_ "SystemSignalLongSymbol" SG_ 1470 IDB_a130_DIbrakeTorqueComma_0001 "IDB_a130_DIbrakeTorqueCommandFullTooLow";
BA_ "Confidence" SG_ 1470 IDB_a132_validityOnChassisBus 1;
BA_ "Confidence" SG_ 1470 IDB_a132_validityOnPartyBus 1;
BA_ "Confidence" SG_ 983 IDB_matrixIndex 1;
BA_ "SystemSignalLongSymbol" SG_ 983 IDB_a070_DIchassisControlChecksu "IDB_a070_DIchassisControlChecksum";
BA_ "SystemSignalLongSymbol" SG_ 983 IDB_a119_VCLEFTepbmStatusChecksu "IDB_a119_VCLEFTepbmStatusChecksum";
BA_ "SystemSignalLongSymbol" SG_ 983 IDB_a129_RCUinputRodStrokeInvali "IDB_a129_RCUinputRodStrokeInvalid";
BA_ "SystemSignalLongSymbol" SG_ 983 IDB_a130_DIfullTorqueRequestInva "IDB_a130_DIfullTorqueRequestInvalid";
BA_ "SystemSignalLongSymbol" SG_ 983 IDB_a132_RCUinputRodStrokeQFInva "IDB_a132_RCUinputRodStrokeQFInvalid";
BA_ "SystemSignalLongSymbol" SG_ 983 IDB_a138_DIbrakeTorqueCommandAnd "IDB_a138_DIbrakeTorqueCommandAndFlagMismatch";
BA_ "SystemSignalLongSymbol" SG_ 983 IDB_a139_DIbrakeTorqueCommandFul "IDB_a139_DIbrakeTorqueCommandFullSNA";
BA_ "SystemSignalLongSymbol" SG_ 983 IDB_a140_PMbrakePedalCmdQFInvali "IDB_a140_PMbrakePedalCmdQFInvalid";
BA_ "SystemSignalLongSymbol" SG_ 983 IDB_a141_DIbrakeTorqueCommandFul "IDB_a141_DIbrakeTorqueCommandFullTooLow";
BA_ "SystemSignalLongSymbol" SG_ 983 IDB_a144_hydraulicPushthroughAct "IDB_a144_hydraulicPushthroughActive";
BA_ "SystemSignalLongSymbol" SG_ 983 IDB_a145_DASredundantBrakingCont "IDB_a145_DASredundantBrakingControlDLC";
BA_ "SystemSignalLongSymbol" SG_ 983 IDB_a146_DASredundantBrakingCont "IDB_a146_DASredundantBrakingControlCounter";
BA_ "SystemSignalLongSymbol" SG_ 983 IDB_a147_DASredundantBrakingCont "IDB_a147_DASredundantBrakingControlChecksum";
BA_ "SystemSignalLongSymbol" SG_ 983 IDB_a148_DASbrakeTorqueCommandIn "IDB_a148_DASbrakeTorqueCommandInvalid";
BA_ "SystemSignalLongSymbol" SG_ 983 IDB_a149_DASmiaBrakeTorqueComman "IDB_a149_DASmiaBrakeTorqueCommandInvalid";
BA_ "Confidence" SG_ 828 IDB_infoIndex 1;
BA_ "Confidence" SG_ 828 IDB_infoPcbaID 0;
BA_ "Confidence" SG_ 828 IDB_infoAssemblyID 0;
BA_ "Confidence" SG_ 828 IDB_infoUsageID 0;
BA_ "Confidence" SG_ 828 IDB_infoSubUsageID 0;
BA_ "Confidence" SG_ 1429 OCS1P_alertID 1;
BA_ "Confidence" SG_ 1429 OCS1P_alertState 1;
VAL_ 1384 GTW_alertID 469 "a469_backlightFsmUnhealthy" 463 "a463_displayEdidReadFailed" 456 "a456_hrlStateMachinePageOwnershipError" 455 "a455_hrlDumpPageOwnershipError" 454 "a454_diagCanFrameOverread" 453 "a453_diagCanFdSetDesync" 452 "a452_diagCanStaleSocket" 451 "a451_diagCanBufferExhausted" 450 "a450_unexpectedAutopilotControlCanMessage" 439 "a439_VCCCversionMismatch" 438 "a438_wakeSourceUnknown" 437 "a437_softFlowControlNotRunning" 436 "a436_possibleCanRxIssue" 429 "a429_LUMBAR32RversionMismatch" 428 "a428_LUMBAR32LversionMismatch" 427 "a427_DISPBRIDGEversionMismatch" 422 "a422_ethSwitchSevereCongestionWatchdog" 421 "a421_ModemEthLinkDown" 420 "a420_unexpectedCanMessageLength" 418 "a418_TRCMversionMismatch" 414 "a414_socHeldInReset" 411 "a411_tASILStatusCheck" 410 "a410_unexpectedResetCause2" 409 "a409_unexpectedResetCause" 402 "a402_VCSEAT2RversionMismatch" 401 "a401_VCSEAT2LversionMismatch" 400 "a400_ethlSwitchOTPIncorrect" 399 "a399_ethIfRxTcpipQueueDrop" 398 "a398_awakeForExtendedTime" 397 "a397_alreadyInDrive" 396 "a396_alreadyInReverse" 395 "a395_lwipIcmpError" 394 "a394_WIPERversionMismatch" 393 "a393_osdSramCrcMismatch" 391 "a391_adspMacAddrCheckFailed" 390 "a390_displayFwQueryFailed" 389 "a389_rcmEventDetected" 388 "a388_adspWatchdogSkipped" 387 "a387_externalRtcReadFailure" 386 "a386_RCUCALversionMismatch" 385 "a385_RCUversionMismatch" 384 "a384_IDBCALversionMismatch" 383 "a383_IDB1versionMismatch" 382 "a382_IDBversionMismatch" 381 "a381_DPBCALversionMismatch" 380 "a380_DPBversionMismatch" 376 "a376_blFailedToExecBootImg" 366 "a366_uiGearRequestMismatch" 364 "a364_BLEEPCRADLEversionMismatch" 363 "a363_RGBDOORRRversionMismatch" 362 "a362_RGBDOORFRversionMismatch" 361 "a361_RGBDOORRLversionMismatch" 360 "a360_RGBDOORFLversionMismatch" 359 "a359_RGBIPFRversionMismatch" 358 "a358_RGBIPFLversionMismatch" 356 "a356_touchGPIOStatusCheck" 355 "a355_EPASTSversionMismatch" 354 "a354_EPASTPversionMismatch" 353 "a353_sASILStatusCheck" 352 "a352_mASILStatusCheck" 351 "a351_sOSDCrcCheck" 350 "a350_mOSDCrcCheck" 349 "a349_VCBLDCPBversionMismatch" 348 "a348_VCBLDCFversionMismatch" 342 "a342_VCBLDCPPversionMismatch" 336 "a336_possibleCanTxIssue" 334 "a334_hrlFolderSpaceLow" 332 "a332_unknownDisplayPN" 331 "a331_SWSRversionMismatch" 330 "a330_SWSLversionMismatch" 329 "a329_FOHMversionMismatch" 328 "a328_smartShiftDisabled" 323 "a323_gestureStartOutOfStrip" 322 "a322_gestureUnrecognizedFromMoving" 317 "a317_sdCardChkdskRepairFailed" 316 "a316_sdCardChkdskRepair" 314 "a314_canLogBlockWriteErr" 313 "a313_OSDActive" 312 "a312_hrlFileIncomplete" 311 "a311_canLogQueueFullBeforeFsInit" 309 "a309_VCUSBversionMismatch" 282 "a282_tcuPhyConfigurationFailed" 281 "a281_likelyMissedPoke" 280 "a280_hrlFrameDropped" 279 "a279_adspRepeatedWatchdog" 278 "a278_ethSwitchCongested" 277 "a277_NonRevCDrMOSMitigationFailed" 276 "a276_VDDSOC_DrMOS_Fault" 275 "a275_VDDCORE_DrMOS_Fault" 274 "a274_BLEEPREARRIGHTversionMismatch" 273 "a273_BLEEPREARLEFTversionMismatch" 268 "a268_stoMIA" 267 "a267_dpp2MIA" 266 "a266_dpp1MIA" 265 "a265_optionFlagsError" 264 "a264_hrlPseudoFileAvail" 263 "a263_hrlUdpFileAvail" 262 "a262_canLogBlockDropped" 261 "a261_adspWatchdog" 260 "a260_unknownPN" 255 "a255_rtc32KHzWatchdog" 246 "a246_touchcoreHeartbeat" 245 "a245_apsNotDisabled" 244 "a244_SDCRversionMismatch" 230 "a230_touchInterruptStorm" 229 "a229_displaySoftsetConnection" 228 "a228_DISPOSDversionMismatch" 227 "a227_DISPTOUCHversionMismatch" 226 "a226_DISPversionMismatch" 225 "a225_resetOnSleepWake" 224 "a224_sdCardUpgradeNeeded" 223 "a223_LVBMSversionMismatch" 219 "a219_CMPSversionMismatch" 218 "a218_switchOTPIncorrect" 186 "a186_swrPrecaution" 176 "a176_TPMShardWarnRearRight" 175 "a175_TPMShardWarnRearLeft" 174 "a174_TPMShardWarnFrontRight" 173 "a173_TPMShardWarnFrontLeft" 172 "a172_TPMSsoftWarnRearRight" 171 "a171_TPMSsoftWarnRearLeft" 170 "a170_TPMSsoftWarnFrontRight" 169 "a169_TPMSsoftWarnFrontLeft" 168 "a168_nErrCanFaultParty" 167 "a167_nErrCanFaultCh" 166 "a166_nErrCanFaultVeh" 165 "a165_USMversionMismatch" 164 "a164_VCBATTversionMismatch" 155 "a155_PMversionMismatch" 153 "a153_externalRtcAlarmFailure" 151 "a151_HCM3RversionMismatch" 150 "a150_HCM3LversionMismatch" 149 "a149_rtcTimeSetInPast" 147 "a147_updateAbortFor12v" 146 "a146_performancePackageMismatch" 145 "a145_carConfigsNotWritten" 144 "a144_hrlStateMachine" 143 "a143_possibleCanWakeIssue" 141 "a141_teleCANETHis" 140 "a140_cancoreHeartbeat" 139 "a139_CMPDversionMismatch" 138 "a138_sdCardEndOfLife" 137 "a137_lowHeap" 136 "a136_hrlGameModeFileAvail" 135 "a135_canLogQueueFull" 134 "a134_disableFeatureFailed" 133 "a133_adspFaultDetected" 129 "a129_ICRversionMismatch" 127 "a127_noFilePointersAvailable" 125 "a125_switchReplayUnlocked" 123 "a123_BDYbusOverloaded" 122 "a122_BDY_canFault" 120 "a120_switchUnlocked" 118 "a118_unexpectedFunctionalResetStatus" 117 "a117_unexpectedDestructiveResetStatus" 116 "a116_switchInitFailed" 115 "a115_hrlEventFileAvail" 114 "a114_updtRetried" 113 "a113_unrecognizedCanMessage" 112 "a112_z4bDisabled" 111 "a111_writeMdioFailed" 110 "a110_readMdioFailed" 109 "a109_failedToStartUpdater" 108 "a108_BLEEPREARversionMismatch" 107 "a107_BLEEPRIGHTversionMismatch" 106 "a106_BLEEPLEFTversionMismatch" 105 "a105_eBuckConfigured" 104 "a104_sdCardDriverArgCorrupted" 103 "a103_sdCardFormatted" 101 "a101_switchWatchdog" 100 "a100_CBCversionMismatch" 99 "a099_SWCversionMismatch" 98 "a098_HCMRversionMismatch" 97 "a097_HCMLversionMismatch" 96 "a096_sdCardFatCorrupted" 95 "a095_sdCardFull" 94 "a094_sdCardInvReqOverflowCount" 93 "a093_sdCardInvReqOverflowBase" 92 "a092_sdCardInvReqZero" 91 "a091_lowStack" 90 "a090_ocuFailed" 89 "a089_sdCardWatchdog" 88 "a088_sdCardInvReqParallel" 87 "a087_ocuInProgress" 86 "a086_ocu" 85 "a085_fuseStateUnknown" 84 "a084_canFrameDropped" 83 "a083_udsMsgDroppedByTcpStack" 82 "a082_sdCardBSCorrupted" 81 "a081_udsMessageRejected" 80 "a080_CHbusOverloaded" 79 "a079_PARTYbusOverloaded" 78 "a078_VEHbusOverloaded" 77 "a077_bmpPmicError" 76 "a076_ethInterfaceReset" 75 "a075_epas3sMIA" 74 "a074_epas3pMIA" 73 "a073_steeringWheelReset" 72 "a072_updateFailure" 71 "a071_hrlTrigger" 70 "a070_hrlDump" 69 "a069_diskioErr" 68 "a068_prodKeyMissing" 67 "a067_tcpDebug" 66 "a066_exception" 65 "a065_PARTY_canFault" 64 "a064_CH_canFault" 63 "a063_VEH_canFault" 62 "a062_bmpWatchdog" 61 "a061_bmpSleepFailure" 60 "a060_unFused" 59 "a059_inFactoryMode" 58 "a058_rtcAlarmFailure" 57 "a057_i2cFailure" 55 "a055_OPCFversionMismatch" 54 "a054_OPCRversionMismatch" 53 "a053_busSleepFailure" 52 "a052_ifTxSpans" 51 "a051_sdCardFileSystemFailure" 50 "a050_sdCardInitFailure" 49 "a049_corruptedManifest" 48 "a048_EPAS3SversionMismatch" 47 "a047_VCRIGHTversionMismatch" 46 "a046_VCLEFTversionMismatch" 45 "a045_VCFRONTversionMismatch" 43 "a043_THSversionMismatch" 42 "a042_TASversionMismatch" 41 "a041_VCSECversionMismatch" 40 "a040_SCCMversionMismatch" 39 "a039_RCMCALversionMismatch" 38 "a038_RCMversionMismatch" 37 "a037_RADCversionMismatch" 36 "a036_PTCversionMismatch" 35 "a035_PMFversionMismatch" 34 "a034_PMRversionMismatch" 33 "a033_PCSCPU2versionMismatch" 32 "a032_PCSversionMismatch" 31 "a031_PARKversionMismatch" 30 "a030_OCS1PversionMismatch" 29 "a029_IBSTCALversionMismatch" 28 "a028_IBSTversionMismatch" 27 "a027_HVPversionMismatch" 26 "a026_GTWversionMismatch" 25 "a025_ESPCALversionMismatch" 24 "a024_ESPversionMismatch" 23 "a023_EPBRversionMismatch" 22 "a022_EPBLversionMismatch" 21 "a021_EPAS3PversionMismatch" 20 "a020_DIRversionMismatch" 19 "a019_CPversionMismatch" 18 "a018_CMPversionMismatch" 17 "a017_BMSversionMismatch" 16 "a016_BLEEPCENTERversionMismatch" 15 "a015_DIFversionMismatch" 14 "a014_APSversionMismatch" 12 "a012_maincoreWatchdog" 11 "a011_cancoreWatchdog" 10 "a010_wdTaskCount" 9 "a009_lateTask" 8 "a008_ifPbufAllocError" 7 "a007_ifRxBufError" 6 "a006_ifTxOutputFull" 5 "a005_stackOverflowHook" 4 "a004_mallocHook" 3 "a003_logWriteRecord" 2 "a002_taskError" 1 "a001_canEthTxQueue" 0 "ALERT_DO_NOT_USE_ZERO" ;
VAL_ 1384 GTW_alertState 1 "SET" 0 "CLEARED" ;
VAL_ 1384 GTW_a049_headerError 3 "HEADER_READ_FAIL" 2 "MUID_LIST_UNEXPECTED" 1 "HEADER_INFO_BAD" 0 "HEADER_OK" ;
VAL_ 1384 GTW_a062_bmpWatchdogReason 4 "THERMAL_TRIP" 3 "SLEEP_FAILURE" 2 "WAKE_FAILURE" 1 "RUNTIME_FAILURE" 0 "WATCHDOG_NONE" ;
VAL_ 1384 GTW_a063_VEH_faultConfinement 2 "BUS_OFF" 1 "ERROR_PASSIVE" 0 "ERROR_ACTIVE" ;
VAL_ 1384 GTW_a064_CH_faultConfinement 2 "BUS_OFF" 1 "ERROR_PASSIVE" 0 "ERROR_ACTIVE" ;
VAL_ 1384 GTW_a065_PARTY_faultConfinement 2 "BUS_OFF" 1 "ERROR_PASSIVE" 0 "ERROR_ACTIVE" ;
VAL_ 1384 GTW_a073_SOCResetRequestor 4 "DAS" 3 "VCSEC" 2 "FORCE" 1 "BUTTONS" 0 "UNKNOWN" ;
VAL_ 1384 GTW_a077_bmpPmicErrorType 4 "INTERNAL_SM" 3 "OT" 2 "MEM_CORRUPT" 1 "OC_OV_CC" 0 "NONE" ;
VAL_ 1384 GTW_a122_BDY_faultConfinement 2 "BUS_OFF" 1 "ERROR_PASSIVE" 0 "ERROR_ACTIVE" ;
VAL_ 1384 GTW_a261_failureReason 6 "INCORRECT_TYPE" 5 "INCORRECT_SEQ_NO" 4 "INCORRECT_ID" 3 "INCORRECT_ADDRESS" 2 "INCORRECT_LENGTH" 1 "RECEIVE_ERROR" 0 "NO_ERROR" ;
VAL_ 1384 GTW_a277_mitigationFailureReason 7 "FAILED_NVRAM_WRITE" 6 "FAILED_NVRAM_WRITE_PROTECTED" 5 "FAILED_REGISTERS_WRITE_PROTECTED" 4 "FAILED_REGISTER_WRITE" 3 "FAILED_REGISTER_READ" 2 "FAILED_ICE_NOT_AWAKE" 1 "NOT_NEEDED" 0 "APPLIED_SUCCESSFULLY" ;
VAL_ 1384 GTW_a279_failureReason 6 "INCORRECT_TYPE" 5 "INCORRECT_SEQ_NO" 4 "INCORRECT_ID" 3 "INCORRECT_ADDRESS" 2 "INCORRECT_LENGTH" 1 "RECEIVE_ERROR" 0 "NO_ERROR" ;
VAL_ 1384 GTW_a317_status 7 "MASK" 4 "PARTIAL" 3 "FAILED" 2 "SUCCESS" 1 "NOT_NEEDED" ;
VAL_ 1384 GTW_a317_errorCode 19 "FS_INFO_INVALID_SIG" 18 "FS_INFO_SECTOR_NOT_FOUND" 17 "FS_INFO_READ_FAILED" 16 "FS_INFO_WRITE_FAILED" 15 "INVALID_CLUSTER" 14 "DIR_TOO_DEEP" 13 "UNKNOWN_FS" 12 "CLUSTER_IN_USE" 11 "FAT_MISMATCHED" 10 "FAT_READ_FAILED" 9 "FAT_WRITE_FAILED" 8 "NOT_FAT32" 7 "BAD_SECTOR_SIZE" 6 "BR_READ_FAILED" 5 "MBR_READ_FAILED" 4 "DISK_INIT_FAILED" 3 "INSUFFICIENT_MEMORY" 2 "ERROR_FOUND_FIXED" 1 "ERROR_FOUND" 0 "NO_ERROR" ;
VAL_ 62 GTW_matrixIndex 7 "AlertMatrix7" 6 "AlertMatrix6" 5 "AlertMatrix5" 4 "AlertMatrix4" 3 "AlertMatrix3" 2 "AlertMatrix2" 1 "AlertMatrix1" 0 "AlertMatrix0" ;
VAL_ 838 GTW_autopilotOverrideState 8 "UNKNOWN" 7 "VEHICLE_MANAGED" 6 "OPTION_OVERRIDE" 5 "OPTION_CODE" 4 "TIMEBOUND_TRIAL" 3 "TIMEBOUND_SUBSCRIPTION" 2 "TRIAL" 1 "SUBSCRIPTION" 0 "BASE" ;
VAL_ 838 GTW_autopilotConfig 4 "BASIC" 3 "SELF_DRIVING" 2 "ENHANCED" 1 "HIGHWAY" 0 "NONE" ;
VAL_ 838 GTW_autopilotOverrideConfig 4 "BASIC" 3 "SELF_DRIVING" 2 "ENHANCED" 1 "HIGHWAY" 0 "NONE" ;
VAL_ 838 GTW_autopilotConfigSource 2 "AUTOPILOT_NOT_UPDATED" 1 "AUTOPILOT" 0 "GATEWAY" ;
VAL_ 904 GTW_VEH_faultConfinement 2 "BUS_OFF" 1 "ERROR_PASSIVE" 0 "ERROR_ACTIVE" ;
VAL_ 904 GTW_PARTY_faultConfinement 2 "BUS_OFF" 1 "ERROR_PASSIVE" 0 "ERROR_ACTIVE" ;
VAL_ 904 GTW_CH_faultConfinement 2 "BUS_OFF" 1 "ERROR_PASSIVE" 0 "ERROR_ACTIVE" ;
VAL_ 904 GTW_BDY_faultConfinement 2 "BUS_OFF" 1 "ERROR_PASSIVE" 0 "ERROR_ACTIVE" ;
VAL_ 1080 GTW_ethWakeUpReason 17 "GTW_WAKEUP_REASON_TCU_TC10_VERSION_CHECK" 16 "GTW_WAKEUP_REASON_EGGLEFT_LINK_DOWN" 15 "GTW_WAKEUP_REASON_RCMPRIVATE_CAN" 14 "GTW_WAKEUP_REASON_VCLEFT" 13 "GTW_WAKEUP_REASON_LOOP" 12 "GTW_WAKEUP_REASON_DISPLAY_TAP" 11 "GTW_WAKEUP_REASON_URGENT_TRANSMIT_ALERT" 10 "GTW_WAKEUP_REASON_BDY_CAN" 9 "GTW_WAKEUP_REASON_PT_CAN" 8 "GTW_WAKEUP_REASON_UI_SCHEDULED" 7 "GTW_WAKEUP_REASON_RTC_ALARM" 6 "GTW_WAKEUP_REASON_VCFRONT" 5 "GTW_WAKEUP_REASON_VEH_CAN" 4 "GTW_WAKEUP_REASON_ETH_CAN" 3 "GTW_WAKEUP_REASON_CH_CAN" 2 "GTW_WAKEUP_REASON_GSM_RI" 1 "GTW_WAKEUP_REASON_RESET" 0 "GTW_WAKEUP_REASON_NONE" ;
VAL_ 1656 GTW_gearShiftRequest 4 "GEAR_REQUEST_DRIVE" 3 "GEAR_REQUEST_NEUTRAL" 2 "GEAR_REQUEST_REVERSE" 1 "GEAR_REQUEST_PARK" 0 "GEAR_REQUEST_IDLE_SNA" ;
VAL_ 1656 GTW_primaryGearControlStatus 14 "NOT_QUALIFIED_RHD_CONFIG_UNAVAILABLE" 13 "NOT_QUALIFIED_DISPLAY_KNOWN_FROZEN_SCREEN" 12 "NOT_QUALIFIED_DISPLAY_ASIL_VIDEO_ERROR" 11 "NOT_QUALIFIED_GEAR_STRIP_MISMATCH" 10 "NOT_QUALIFIED_DISPLAY_UNTRAINED" 9 "NOT_QUALIFIED_UI_NO_RESP_GEAR_STRIP" 8 "NOT_QUALIFIED_CENTER_DISP_UI_UNHEALTHY" 7 "NOT_QUALIFIED_DISPLAY_FROZEN_ON_GESTURE" 6 "NOT_QUALIFIED_LOW_BRIGHTNESS" 5 "NOT_QUALIFIED_FALSE_TOUCH" 4 "NOT_QUALIFIED_MANUAL" 3 "NOT_QUALIFIED_DISPLAY_ERRS" 2 "NOT_QUALIFIED_FULLSCREEN" 1 "QUALIFIED" 0 "NOT_QUALIFIED" ;
VAL_ 1656 GTW_autoParkRequest 1 "ACTIVE" 0 "IDLE" ;
VAL_ 1656 GTW_smartShiftStatus 9 "DISABLED_AUDIO_NOT_READY" 8 "DISABLED_OSD_ACTIVATED" 7 "DISABLED_DISQUALIFIED" 6 "DISABLED_FULLSCREEN" 5 "DISABLED_UI_MIA" 4 "DISABLED_CLUSTER_DISP_ERR" 3 "DISABLED_CENTER_DISP_ERR" 2 "DISABLED_UI_CONFIG" 1 "ENABLED" 0 "DISABLED_SNA" ;
VAL_ 1656 GTW_gearStripChangeReason 27 "EBUCK_DISABLE" 26 "SLEEP_DISABLE" 25 "VC_MIA_GRACE_DISABLE" 24 "VC_MIA_ENABLE" 23 "DRIVERLESS_NO_TAKEOVER_DISABLE" 22 "EMERGENCY_OPERATION_ENABLE" 21 "WOT_ENABLE" 20 "PARK_ENGAGED_ENABLE" 19 "MISSING_SPEED_OR_STEERING_ESTIMATE_IN_D_ENABLE" 18 "UI_MIA_ENABLE" 16 "NOT_DRIVE_STATE_DISABLE" 15 "FULLSCREEN_DISABLE" 14 "DEFAULT_DISABLE" 13 "REVERSE_ENABLE" 12 "NEUTRAL_ENABLE" 11 "P_AND_BRAKE_ENABLE" 10 "CHARGING_DISABLE" 9 "CRUISE_ACTIVE_DISABLE" 8 "DI_MIA_ENABLE" 7 "HIGH_ACCEL_DISABLE" 6 "MEDIUM_SPEED_DISABLE" 5 "TRAFFIC_CONTROL_NO_CHANGE" 4 "VERY_LOW_SPEED_ENABLE" 3 "HIGH_STEERING_ANGLE_ENABLE" 2 "HIGH_JERK_ENABLE" 1 "DRIVER_BRAKE_APPLY_ENABLE" 0 "SNA" ;
VAL_ 1656 GTW_screenPCBTemperature 2047 "GTW_I2C_TEMP_SNA" ;
VAL_ 2033 GTW_hrlIndex 2 "Mux2" 1 "Mux1" ;
VAL_ 2033 GTW_hrlSdCardSizeGB 0 "SNA" ;
VAL_ 2033 GTW_hrlState 1 "ENABLED" 0 "DISABLED" ;
VAL_ 2033 GTW_hrlTriggerType 15 "HRL_TRIGGER_NONE" 5 "HRL_TRIGGER_EVENT_EXTERNAL" 4 "HRL_TRIGGER_PSEUDONYMOUS" 3 "HRL_TRIGGER_CONTINUOUS" 2 "HRL_TRIGGER_GAME_MODE" 1 "HRL_TRIGGER_EVENT" 0 "HRL_TRIGGER_UDPAPI" ;
VAL_ 60 GTW_infoIndex 255 "END" 31 "SUBCOMPONENT_GITHASH" 30 "PACKAGE_SN_8_14" 29 "PACKAGE_SN_1_7" 27 "PACKAGE_PN_15_20" 26 "PACKAGE_PN_8_14" 25 "PACKAGE_PN_1_7" 23 "SUBCOMPONENT2" 22 "VARIANTCRC" 20 "UDS_PROTOCOL_BOOTCRC" 19 "VERSION_DEPRECATED" 18 "BOOTLOADER_GITHASH" 17 "APP_GITHASH" 16 "SUBCOMPONENT" 15 "BOOTLOADER_CRC" 14 "BOOTLOADER_SVN" 13 "APP_CRC" 11 "PCBAID_ASSYID_USAGEID" 10 "BUILD_HWID_COMPONENTID" 9 "DEPRECATED_9" 8 "DEPRECATED_8" 7 "DEPRECATED_7" 6 "DEPRECATED_6" 5 "DEPRECATED_5" 4 "DEPRECATED_4" 3 "DEPRECATED_3" 2 "DEPRECATED_2" 1 "DEPRECATED_1" 0 "DEPRECATED_0" ;
VAL_ 60 GTW_buildType 4 "INFO_MFG_BUILD" 3 "INFO_TRACEABLE_CI_BUILD" 2 "INFO_LOCAL_BUILD" 1 "INFO_PLATFORM_BUILD" 0 "INFO_UNKNOWN_BUILD" ;
VAL_ 60 GTW_platformType 255 "GTW_PLATFORM_END" 3 "GTW_PLATFORM_MODEL3" 0 "GTW_PLATFORM_UNKNOWN" ;
VAL_ 1370 GTW_mismatchFaultIndex 5 "Mux5" 4 "Mux4" 3 "Mux3" 2 "Mux2" 1 "Mux1" ;
VAL_ 840 GTW_vehicleVersionMatchStatus 2 "MATCHED" 1 "MISMATCHED" 0 "NOT_CALCULATED_YET" ;
VAL_ 840 GTW_hwtype 3 "TRAVEO2" 2 "SPC58" 1 "MPC57" 0 "SNA" ;
VAL_ 840 GTW_jcanProductName 11 "SEMITRUCKV2" 10 "GOLDENSNITCH" 8 "BAYBERRY" 7 "CYBERTRUCK" 6 "POPPYSEED" 5 "SEMITRUCK" 4 "TAMARIND" 3 "LYCHEE" 2 "MODELY" 1 "MODEL3" 0 "SNA" ;
VAL_ 840 GTW_touchcoreOsType 1 "GTW_OS_RT" 0 "GTW_OS_FREERTOS" ;
VAL_ 840 GTW_sentryModeState 6 "SNA" 5 "QUIET" 4 "PANIC" 3 "AWARE" 2 "ARMED" 1 "IDLE" 0 "OFF" ;
VAL_ 840 GTW_secureBootEnabled 1 "TRUE" 0 "FALSE" ;
VAL_ 840 GTW_socSleepType 2 "SHALLOW" 1 "S3" 0 "SNA" ;
VAL_ 840 GTW_resetType 8 "OTHER" 7 "TOUCHCORE_WATCHDOG" 6 "CANCORE_WATCHDOG" 5 "MAINCORE_WATCHDOG" 4 "WAKE" 3 "BUTTON" 2 "SOFTWARE" 1 "POR" 0 "SNA" ;
VAL_ 1005 GTW_peripheralConfirmedUpdateNee 3 "UPDATE_CONDITIONS_NOT_CORRECT" 2 "UPDATE_NOT_NEEDED" 1 "UPDATE_NEEDED" 0 "UNKNOWN" ;
VAL_ 1112 GTW_nmKeepAwakeReason 15 "GTW_KEEPAWAKE_REASON_TBD" 7 "GTW_KEEPAWAKE_REASON_TCU_TC10_VERSION_UNSUPPORTED" 6 "GTW_KEEPAWAKE_REASON_TCU_TC10_VERSION_CHECK" 5 "GTW_KEEPAWAKE_REASON_EGGLEFT_LINK_DOWN" 4 "GTW_KEEPAWAKE_REASON_URGENT_TRANSMIT_ALERT" 3 "GTW_KEEPAWAKE_REASON_FCSM_ACTIVE" 2 "GTW_KEEPAWAKE_REASON_GSM_RI" 1 "GTW_KEEPAWAKE_REASON_UI_SCHEDULED" 0 "GTW_KEEPAWAKE_REASON_NONE_SNA" ;
VAL_ 1112 GTW_nmWakeUpReason 17 "GTW_WAKEUP_REASON_TCU_TC10_VERSION_CHECK" 16 "GTW_WAKEUP_REASON_EGGLEFT_LINK_DOWN" 15 "GTW_WAKEUP_REASON_RCMPRIVATE_CAN" 14 "GTW_WAKEUP_REASON_VCLEFT" 13 "GTW_WAKEUP_REASON_LOOP" 12 "GTW_WAKEUP_REASON_DISPLAY_TAP" 11 "GTW_WAKEUP_REASON_URGENT_TRANSMIT_ALERT" 10 "GTW_WAKEUP_REASON_BDY_CAN" 9 "GTW_WAKEUP_REASON_PT_CAN" 8 "GTW_WAKEUP_REASON_UI_SCHEDULED" 7 "GTW_WAKEUP_REASON_RTC_ALARM" 6 "GTW_WAKEUP_REASON_VCFRONT" 5 "GTW_WAKEUP_REASON_VEH_CAN" 4 "GTW_WAKEUP_REASON_ETH_CAN" 3 "GTW_WAKEUP_REASON_CH_CAN" 2 "GTW_WAKEUP_REASON_GSM_RI" 1 "GTW_WAKEUP_REASON_RESET" 0 "GTW_WAKEUP_REASON_NONE" ;
VAL_ 1112 GTW_ethKeepAwakeReason 3 "TCU_TC10_VERSION_UNSUPPORTED" 2 "TCU_TC10_VERSION_CHECK" 1 "URGENT_TRANSMIT_ALERT" 0 "NONE_SNA" ;
VAL_ 1112 GTW_nmDebugWakeUp 2147483648 "WKPU_31" 1073741824 "WKPU_30" 536870912 "WKPU_29" 268435456 "WKPU_28" 134217728 "WKPU_27" 67108864 "WKPU_26" 33554432 "WKPU_25" 16777216 "WKPU_24" 8388608 "WKPU_23" 4194304 "WKPU_22" 2097152 "WKPU_21" 1048576 "WKPU_20" 524288 "WKPU_19" 262144 "WKPU_18" 131072 "WKPU_17" 65536 "WKPU_16" 32768 "WKPU_15" 16384 "WKPU_14" 8192 "WKPU_13" 4096 "WKPU_12" 2048 "WKPU_11" 1024 "WKPU_10" 512 "WKPU_9" 256 "WKPU_8" 128 "WKPU_7" 64 "WKPU_6" 32 "WKPU_5" 16 "WKPU_4" 8 "WKPU_3" 4 "WKPU_2" 2 "WKPU_1" 1 "WKPU_0" 0 "WKPU_NONE" ;
VAL_ 1470 IDB_alertID 157 "a157_PMlocStateCounter" 156 "a156_PMlocStateChecksum" 155 "a155_PMlocStateDLC" 152 "a152_DIlocStatus2Checksum" 151 "a151_DIlocStatus2Counter" 150 "a150_DIlocStatus2DLC" 149 "a149_DASmiaBrakeTorqueCommandInvalid" 148 "a148_DASbrakeTorqueCommandInvalid" 147 "a147_DASredundantBrakingControlChecksum" 146 "a146_DASredundantBrakingControlCounter" 145 "a145_DASredundantBrakingControlDLC" 144 "a144_hydraulicPushthroughActive" 143 "a143_factoryModeActive" 142 "a142_PMebrCmdStateInvalid" 141 "a141_DIbrakeTorqueCommandFullTooLow" 140 "a140_PMbrakePedalCmdQFInvalid" 139 "a139_DIbrakeTorqueCommandFullSNA" 138 "a138_DIbrakeTorqueCommandAndFlagMismatch" 137 "a137_VCLEFTcdpRequestInvalid" 136 "a136_RCUptsCalMissing" 135 "a135_DIbrakeCommandChecksum" 134 "a134_DIbrakeCommandCounter" 133 "a133_DIbrakeCommandDLC" 132 "a132_RCUinputRodStrokeQFInvalid" 131 "a131_cbcFaulted" 130 "a130_DIfullTorqueRequestInvalid" 129 "a129_RCUinputRodStrokeInvalid" 128 "a128_largeAirVolume" 127 "a127_brakeFluidLevelInvalid" 126 "a126_DItorqueRequestInvalid" 125 "a125_PMvdcCmdStateInvalid" 124 "a124_VCFRONTtempInvalid" 123 "a123_DIRtorqueCommandInvalid" 122 "a122_DIFtorqueCommandInvalid" 121 "a121_dynoModeActive" 120 "a120_EPAS3Pinvalid" 119 "a119_VCLEFTepbmStatusChecksum" 118 "a118_VCLEFTepbmStatusCounter" 117 "a117_VCLEFTepbmStatusDLC" 116 "a116_VCFRONTsensorsDLC" 115 "a115_VCFRONTespLvStInvalid" 114 "a114_longAccelInvalid" 113 "a113_latAccelInvalid" 112 "a112_yawRateInvalid" 111 "a111_EPBstatusChecksum" 110 "a110_EPBstatusCounter" 109 "a109_BDWsignalInvalid" 108 "a108_EPBstatusDLC" 107 "a107_DIRtorqueInvalid" 106 "a106_DIFtorqueInvalid" 105 "a105_DIgearInvalid" 104 "a104_DIaccelPosInvalid" 103 "a103_DIfullTorquePathFaulted" 102 "a102_bdwRequestActiveInvalid" 101 "a101_RCMcollisionCounter" 100 "a100_RCMcollisionChecksum" 99 "a099_RCMcollisionDLC" 98 "a098_VCFRONTLVPwrStCounter" 97 "a097_VCFRONTLVPwrStChecksum" 96 "a096_VCFRONTLVPowerStateDLC" 95 "a095_RCMinertial2Counter" 94 "a094_RCMinertial2Checksum" 93 "a093_RCMinertial2DLC" 92 "a092_RCMinertial1Counter" 91 "a091_RCMinertial1Checksum" 90 "a090_RCMinertial1DLC" 89 "a089_PMstate2Counter" 88 "a088_PMstate2Checksum" 87 "a087_PMstate2DLC" 86 "a086_EPAS3PsysStatusCounter" 85 "a085_EPAS3PsysStatusChecksum" 84 "a084_EPAS3PsysStatusDLC" 83 "a083_DIvdcRightCounter" 82 "a082_DIvdcRightChecksum" 81 "a081_DIvdcRightDLC" 80 "a080_DIvdcLeftCounter" 79 "a079_DIvdcLeftChecksum" 78 "a078_DIvdcLeftDLC" 77 "a077_DIRtorqueCounter" 76 "a076_DIRtorqueChecksum" 75 "a075_DIRtorqueDLC" 74 "a074_DIsystemStatusCounter" 73 "a073_DIsystemStatusChecksum" 72 "a072_DIsystemStatusDLC" 71 "a071_DIchassisControlCounter" 70 "a070_DIchassisControlChecksum" 69 "a069_DIchassisControlDLC" 68 "a068_DIFtorqueCounter" 67 "a067_DIFtorqueChecksum" 66 "a066_DIFtorqueDLC" 65 "a065_RCUactuationCounter" 64 "a064_RCUactuationChecksum" 63 "a063_RCUactuationDLC" 62 "a062_RCUstatusCounter" 61 "a061_RCUstatusChecksum" 60 "a060_RCUstatusDLC" 59 "a059_cdpFaulted" 58 "a058_scmFaulted" 57 "a057_bdwRequestInvalid" 56 "a056_fadeCompensationFaulted" 55 "a055_panicBrakeAssistFaulted" 54 "a054_skidDetectionFaulted" 53 "a053_DItorquePathFaulted" 52 "a052_vdcFaulted" 51 "a051_ebdFaulted" 50 "a050_absFaulted" 49 "a049_cdpActive" 48 "a048_scmActive" 47 "a047_brakeDiscWipeActive" 46 "a046_fadeCompensationActive" 45 "a045_panicBrakeAssistActive" 44 "a044_standstillSkidDetected" 43 "a043_cbcActive" 42 "a042_btcActive" 41 "a041_vdcActive" 40 "a040_ebdActive" 39 "a039_absActive" 38 "a038_motorInitFault" 37 "a037_chassisBusOff" 36 "a036_partyBusOff" 35 "a035_motorStuck" 34 "a034_motorPositionSetFault" 33 "a033_motorHardOverheat" 32 "a032_motorSoftOverheat" 31 "a031_solenoidValveStuck" 30 "a030_fluidLeakDetected" 29 "a029_pressureSensNotCal" 28 "a028_simPresSensorFault" 27 "a027_circuitPresSensorFault" 26 "a026_axImplausible" 25 "a025_ayImplausible" 24 "a024_yawImplausible" 23 "a023_steeringImplausible" 22 "a022_brakeFluidLow" 21 "a021_pedalSensorNotCal" 20 "a020_RCUpedalTravelMismatch" 19 "a019_pedalSensorFault" 18 "a018_WSSGenericFault" 17 "a017_ReRWSSFault" 16 "a016_ReLWSSFault" 15 "a015_FrRWSSFault" 14 "a014_FrLWSSFault" 13 "a013_motorPosSensorFault" 12 "a012_motorGenericFault" 11 "a011_solenoidValveFault" 10 "a010_asicGenericFault" 9 "a009_asicBoostFault" 8 "a008_motorPowerOpen" 7 "a007_wakeLineOpen" 6 "a006_supplyHardUndervoltage" 5 "a005_supplyMidUndervoltage" 4 "a004_supplyUndervoltage" 3 "a003_supplyHardOvervoltage" 2 "a002_supplyOvervoltage" 1 "a001_mcuGenericFault" 0 "ALERT_DO_NOT_USE_ZERO" ;
VAL_ 1470 IDB_alertState 1 "SET" 0 "CLEARED" ;
VAL_ 1470 IDB_a014_wheelSpeedSensorFreq 1 "NOT_OK" 0 "OK" ;
VAL_ 1470 IDB_a014_wheelSpeedSensorPhase 1 "NOT_OK" 0 "OK" ;
VAL_ 1470 IDB_a014_wheelSpeedSensorMisinst 1 "NOT_OK" 0 "OK" ;
VAL_ 1470 IDB_a014_wheelSpeedSensorWrongEx 1 "NOT_OK" 0 "OK" ;
VAL_ 1470 IDB_a014_wheelSpeedSensorSpeedJu 1 "NOT_OK" 0 "OK" ;
VAL_ 1470 IDB_a014_wheelSpeedSensorSp_0001 1 "NOT_OK" 0 "OK" ;
VAL_ 1470 IDB_a014_wheelSpeedSensorAirGap 1 "NOT_OK" 0 "OK" ;
VAL_ 1470 IDB_a014_wheelSpeedSensorBIST 1 "NOT_OK" 0 "OK" ;
VAL_ 1470 IDB_a014_wheelSpeedSensorLeakage 1 "NOT_OK" 0 "OK" ;
VAL_ 1470 IDB_a014_wheelSpeedSensorOverTem 1 "NOT_OK" 0 "OK" ;
VAL_ 1470 IDB_a014_wheelSpeedSensorSh_0001 1 "NOT_OK" 0 "OK" ;
VAL_ 1470 IDB_a014_wheelSpeedSensorShortTo 1 "NOT_OK" 0 "OK" ;
VAL_ 1470 IDB_a014_wheelSpeedSensorOpen 1 "NOT_OK" 0 "OK" ;
VAL_ 1470 IDB_a015_wheelSpeedSensorFreq 1 "NOT_OK" 0 "OK" ;
VAL_ 1470 IDB_a015_wheelSpeedSensorPhase 1 "NOT_OK" 0 "OK" ;
VAL_ 1470 IDB_a015_wheelSpeedSensorMisinst 1 "NOT_OK" 0 "OK" ;
VAL_ 1470 IDB_a015_wheelSpeedSensorWrongEx 1 "NOT_OK" 0 "OK" ;
VAL_ 1470 IDB_a015_wheelSpeedSensorSpeedJu 1 "NOT_OK" 0 "OK" ;
VAL_ 1470 IDB_a015_wheelSpeedSensorSp_0001 1 "NOT_OK" 0 "OK" ;
VAL_ 1470 IDB_a015_wheelSpeedSensorAirGap 1 "NOT_OK" 0 "OK" ;
VAL_ 1470 IDB_a015_wheelSpeedSensorBIST 1 "NOT_OK" 0 "OK" ;
VAL_ 1470 IDB_a015_wheelSpeedSensorLeakage 1 "NOT_OK" 0 "OK" ;
VAL_ 1470 IDB_a015_wheelSpeedSensorOverTem 1 "NOT_OK" 0 "OK" ;
VAL_ 1470 IDB_a015_wheelSpeedSensorSh_0001 1 "NOT_OK" 0 "OK" ;
VAL_ 1470 IDB_a015_wheelSpeedSensorShortTo 1 "NOT_OK" 0 "OK" ;
VAL_ 1470 IDB_a015_wheelSpeedSensorOpen 1 "NOT_OK" 0 "OK" ;
VAL_ 1470 IDB_a016_wheelSpeedSensorFreq 1 "NOT_OK" 0 "OK" ;
VAL_ 1470 IDB_a016_wheelSpeedSensorPhase 1 "NOT_OK" 0 "OK" ;
VAL_ 1470 IDB_a016_wheelSpeedSensorMisinst 1 "NOT_OK" 0 "OK" ;
VAL_ 1470 IDB_a016_wheelSpeedSensorWrongEx 1 "NOT_OK" 0 "OK" ;
VAL_ 1470 IDB_a016_wheelSpeedSensorSpeedJu 1 "NOT_OK" 0 "OK" ;
VAL_ 1470 IDB_a016_wheelSpeedSensorSp_0001 1 "NOT_OK" 0 "OK" ;
VAL_ 1470 IDB_a016_wheelSpeedSensorAirGap 1 "NOT_OK" 0 "OK" ;
VAL_ 1470 IDB_a016_wheelSpeedSensorBIST 1 "NOT_OK" 0 "OK" ;
VAL_ 1470 IDB_a016_wheelSpeedSensorLeakage 1 "NOT_OK" 0 "OK" ;
VAL_ 1470 IDB_a016_wheelSpeedSensorOverTem 1 "NOT_OK" 0 "OK" ;
VAL_ 1470 IDB_a016_wheelSpeedSensorSh_0001 1 "NOT_OK" 0 "OK" ;
VAL_ 1470 IDB_a016_wheelSpeedSensorShortTo 1 "NOT_OK" 0 "OK" ;
VAL_ 1470 IDB_a016_wheelSpeedSensorOpen 1 "NOT_OK" 0 "OK" ;
VAL_ 1470 IDB_a017_wheelSpeedSensorFreq 1 "NOT_OK" 0 "OK" ;
VAL_ 1470 IDB_a017_wheelSpeedSensorPhase 1 "NOT_OK" 0 "OK" ;
VAL_ 1470 IDB_a017_wheelSpeedSensorMisinst 1 "NOT_OK" 0 "OK" ;
VAL_ 1470 IDB_a017_wheelSpeedSensorWrongEx 1 "NOT_OK" 0 "OK" ;
VAL_ 1470 IDB_a017_wheelSpeedSensorSpeedJu 1 "NOT_OK" 0 "OK" ;
VAL_ 1470 IDB_a017_wheelSpeedSensorSp_0001 1 "NOT_OK" 0 "OK" ;
VAL_ 1470 IDB_a017_wheelSpeedSensorAirGap 1 "NOT_OK" 0 "OK" ;
VAL_ 1470 IDB_a017_wheelSpeedSensorBIST 1 "NOT_OK" 0 "OK" ;
VAL_ 1470 IDB_a017_wheelSpeedSensorLeakage 1 "NOT_OK" 0 "OK" ;
VAL_ 1470 IDB_a017_wheelSpeedSensorOverTem 1 "NOT_OK" 0 "OK" ;
VAL_ 1470 IDB_a017_wheelSpeedSensorSh_0001 1 "NOT_OK" 0 "OK" ;
VAL_ 1470 IDB_a017_wheelSpeedSensorShortTo 1 "NOT_OK" 0 "OK" ;
VAL_ 1470 IDB_a017_wheelSpeedSensorOpen 1 "NOT_OK" 0 "OK" ;
VAL_ 1470 IDB_a020_canSignalValidity 1 "NOT_OK" 0 "OK" ;
VAL_ 1470 IDB_a020_signalValueCrosscheck 1 "NOT_OK" 0 "OK" ;
VAL_ 1470 IDB_a030_primaryExternalCircuitL 1 "NOT_OK" 0 "OK" ;
VAL_ 1470 IDB_a030_secondaryExternalCircui 1 "NOT_OK" 0 "OK" ;
VAL_ 1470 IDB_a030_primaryChamberInternalL 1 "NOT_OK" 0 "OK" ;
VAL_ 1470 IDB_a030_syncModeInternalLeakage 1 "NOT_OK" 0 "OK" ;
VAL_ 1470 IDB_a030_secondaryChamberInterna 1 "NOT_OK" 0 "OK" ;
VAL_ 1470 IDB_a030_masterCylinderInternalL 1 "NOT_OK" 0 "OK" ;
VAL_ 1470 IDB_a060_validityOnChassisBus 1 "NOT_OK" 0 "OK" ;
VAL_ 1470 IDB_a060_validityOnPartyBus 1 "NOT_OK" 0 "OK" ;
VAL_ 1470 IDB_a061_validityOnChassisBus 1 "NOT_OK" 0 "OK" ;
VAL_ 1470 IDB_a061_validityOnPartyBus 1 "NOT_OK" 0 "OK" ;
VAL_ 1470 IDB_a063_validityOnChassisBus 1 "NOT_OK" 0 "OK" ;
VAL_ 1470 IDB_a063_validityOnPartyBus 1 "NOT_OK" 0 "OK" ;
VAL_ 1470 IDB_a064_validityOnChassisBus 1 "NOT_OK" 0 "OK" ;
VAL_ 1470 IDB_a064_validityOnPartyBus 1 "NOT_OK" 0 "OK" ;
VAL_ 1470 IDB_a065_validityOnChassisBus 1 "NOT_OK" 0 "OK" ;
VAL_ 1470 IDB_a065_validityOnPartyBus 1 "NOT_OK" 0 "OK" ;
VAL_ 1470 IDB_a106_qualifierValidity 1 "NOT_OK" 0 "OK" ;
VAL_ 1470 IDB_a106_signalNotAvailable 1 "NOT_OK" 0 "OK" ;
VAL_ 1470 IDB_a107_qualifierValidity 1 "NOT_OK" 0 "OK" ;
VAL_ 1470 IDB_a107_signalNotAvailable 1 "NOT_OK" 0 "OK" ;
VAL_ 1470 IDB_a112_qualifierValidity 1 "NOT_OK" 0 "OK" ;
VAL_ 1470 IDB_a112_signalNotAvailable 1 "NOT_OK" 0 "OK" ;
VAL_ 1470 IDB_a113_qualifierValidity 1 "NOT_OK" 0 "OK" ;
VAL_ 1470 IDB_a113_signalNotAvailable 1 "NOT_OK" 0 "OK" ;
VAL_ 1470 IDB_a114_qualifierValidity 1 "NOT_OK" 0 "OK" ;
VAL_ 1470 IDB_a114_signalNotAvailable 1 "NOT_OK" 0 "OK" ;
VAL_ 1470 IDB_a126_PMebrCmdStateValidity 1 "NOT_OK" 0 "OK" ;
VAL_ 1470 IDB_a126_PMstate2Validity 1 "NOT_OK" 0 "OK" ;
VAL_ 1470 IDB_a126_PMstate2Missing 1 "NOT_OK" 0 "OK" ;
VAL_ 1470 IDB_a126_DIchassisControlValidit 1 "NOT_OK" 0 "OK" ;
VAL_ 1470 IDB_a126_DIchassisControlMissing 1 "NOT_OK" 0 "OK" ;
VAL_ 1470 IDB_a126_DIrequestActiveValidity 1 "NOT_OK" 0 "OK" ;
VAL_ 1470 IDB_a129_validityOnChassisBus 1 "NOT_OK" 0 "OK" ;
VAL_ 1470 IDB_a129_validityOnPartyBus 1 "NOT_OK" 0 "OK" ;
VAL_ 1470 IDB_a130_PMbrakePedalCmdQFValidi 1 "NOT_OK" 0 "OK" ;
VAL_ 1470 IDB_a130_PMstate2Validity 1 "NOT_OK" 0 "OK" ;
VAL_ 1470 IDB_a130_PMstate2Missing 1 "NOT_OK" 0 "OK" ;
VAL_ 1470 IDB_a130_DIbrakeCommandValidity 1 "NOT_OK" 0 "OK" ;
VAL_ 1470 IDB_a130_DIbrakeCommandMissing 1 "NOT_OK" 0 "OK" ;
VAL_ 1470 IDB_a130_DIbrakeTorqueCommandFul 1 "NOT_OK" 0 "OK" ;
VAL_ 1470 IDB_a130_DIbrakeTorqueComma_0001 1 "NOT_OK" 0 "OK" ;
VAL_ 1470 IDB_a132_validityOnChassisBus 1 "NOT_OK" 0 "OK" ;
VAL_ 1470 IDB_a132_validityOnPartyBus 1 "NOT_OK" 0 "OK" ;
VAL_ 983 IDB_matrixIndex 2 "AlertMatrix2" 1 "AlertMatrix1" 0 "AlertMatrix0" ;
VAL_ 828 IDB_infoIndex 255 "END" 31 "SUBCOMPONENT_GITHASH" 30 "PACKAGE_SN_8_14" 29 "PACKAGE_SN_1_7" 27 "PACKAGE_PN_15_20" 26 "PACKAGE_PN_8_14" 25 "PACKAGE_PN_1_7" 23 "SUBCOMPONENT2" 22 "VARIANTCRC" 20 "UDS_PROTOCOL_BOOTCRC" 19 "VERSION_DEPRECATED" 18 "BOOTLOADER_GITHASH" 17 "APP_GITHASH" 16 "SUBCOMPONENT" 15 "BOOTLOADER_CRC" 14 "BOOTLOADER_SVN" 13 "APP_CRC" 11 "PCBAID_ASSYID_USAGEID" 10 "BUILD_HWID_COMPONENTID" 9 "DEPRECATED_9" 8 "DEPRECATED_8" 7 "DEPRECATED_7" 6 "DEPRECATED_6" 5 "DEPRECATED_5" 4 "DEPRECATED_4" 3 "DEPRECATED_3" 2 "DEPRECATED_2" 1 "DEPRECATED_1" 0 "DEPRECATED_0" ;
VAL_ 1429 OCS1P_alertID 156 "a156_seatbeltReminderUnavailable" 155 "a155_rbExit2Exited2" 154 "a154_rbExit2Exited1" 153 "a153_rbExit1Exited" 152 "a152_rbExit1Triggered" 151 "a151_rbEntryExited" 150 "a150_rbEntryTriggered" 148 "a148_classificationMismatch" 145 "a145_rebaselineTriggered" 144 "a144_mismatchCarRegion" 143 "a143_mismatchPassAirbag" 142 "a142_tempHumidityInvalid" 141 "a141_humidityInvalidCalib" 140 "a140_tempInvalidCalib" 139 "a139_seatbackSelfDutyHigh" 138 "a138_seatbackSelfDutyLow" 137 "a137_cushionSelfDutyHigh" 136 "a136_cushionSelfDutyLow" 135 "a135_tempNoCalib" 134 "a134_uninitializedCalib" 133 "a133_sandwichBadCalib" 132 "a132_seatbackSelfNoCalib" 131 "a131_cushionSelfNoCalib" 130 "a130_sandwichNoCalib" 129 "a129_seatbackSelfShort" 128 "a128_seatbackSelfLow" 127 "a127_seatbackSelfOpen" 126 "a126_cushionSelfShort" 125 "a125_cushionSelfLow" 124 "a124_cushionSelfOpen" 123 "a123_sandwichShort" 122 "a122_sandwichLow" 121 "a121_sandwichOpen" 15 "a015_NVMMAlert" 0 "ALERT_DO_NOT_USE_ZERO" ;
VAL_ 1429 OCS1P_alertState 1 "SET" 0 "CLEARED" ;
